VERSION ""

NS_ :

BS_:

BU_: SBZA_R_LS SBZA_L_LS VIS2_LS SDM_LS PEPS_LS UPA_LS PTM_LS MSM_LS HFP_LS EOCM_F_LS ECC_LS DCAC_LS CGM_LS BSM_LS BCM_LS AOS_LS

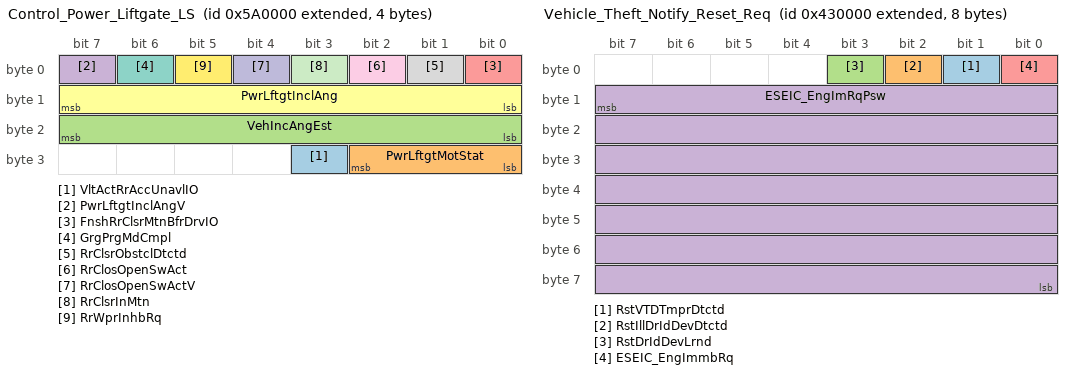
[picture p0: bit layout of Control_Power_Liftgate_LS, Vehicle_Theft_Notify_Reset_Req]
BO_ 2153381888 Control_Power_Liftgate_LS: 4 PTM_LS
 SG_ VltActRrAccUnavlIO : 27|1@0+ (1,0) [0|1] ""  CGM_LS
 SG_ PwrLftgtMotStat : 26|3@0+ (1,0) [0|7] ""  ECC_LS,CGM_LS
 SG_ VehIncAngEst : 23|8@0+ (1,0) [0|255] "deg"  CGM_LS
 SG_ PwrLftgtInclAngV : 7|1@0+ (1,0) [0|1] ""  CGM_LS
 SG_ FnshRrClsrMtnBfrDrvIO : 0|1@0+ (1,0) [0|1] ""  CGM_LS
 SG_ PwrLftgtInclAng : 15|8@0+ (1,0) [0|255] ""  CGM_LS
 SG_ GrgPrgMdCmpl : 6|1@0+ (1,0) [0|1] ""  CGM_LS,BCM_LS
 SG_ RrClsrObstclDtctd : 1|1@0+ (1,0) [0|1] ""  CGM_LS,BCM_LS
 SG_ RrClosOpenSwAct : 2|1@0+ (1,0) [0|1] ""  CGM_LS,BCM_LS
 SG_ RrClosOpenSwActV : 4|1@0+ (1,0) [0|1] ""  CGM_LS,BCM_LS
 SG_ RrClsrInMtn : 3|1@0+ (1,0) [0|1] ""  CGM_LS,BCM_LS
 SG_ RrWprInhbRq : 5|1@0+ (1,0) [0|1] ""  CGM_LS,BCM_LS

BO_ 2151514112 Reset_OilLife_Request_LS: 1 CGM_LS
 SG_ EngOilLfRstRq : 0|1@0+ (1,0) [0|1] ""  BCM_LS

BO_ 2151153664 Rear_Window_Defog_Status_LS: 1 ECC_LS
 SG_ RrWndDfgOn : 0|1@0+ (1,0) [0|1] ""  CGM_LS,BCM_LS

BO_ 2151874560 Vehicle_Theft_Notify_Reset_Req: 8 CGM_LS
 SG_ RstVTDTmprDtctd : 1|1@0+ (1,0) [0|1] ""  BCM_LS
 SG_ RstIllDrIdDevDtctd : 2|1@0+ (1,0) [0|1] ""  BCM_LS
 SG_ RstDrIdDevLrnd : 3|1@0+ (1,0) [0|1] ""  BCM_LS
 SG_ ESEIC_EngImRqPsw : 15|56@0+ (1,0) [0|1] ""  BCM_LS
 SG_ ESEIC_EngImmbRq : 0|1@0+ (1,0) [0|1] ""  BCM_LS

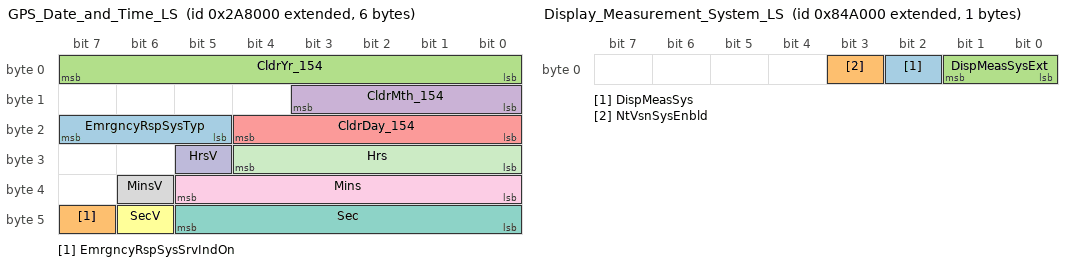
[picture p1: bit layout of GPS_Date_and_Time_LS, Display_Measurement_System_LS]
BO_ 2150268928 GPS_Date_and_Time_LS: 6 CGM_LS
 SG_ EmrgncyRspSysTyp : 23|3@0+ (1,0) [0|7] "" Vector__XXX
 SG_ EmrgncyRspSysSrvIndOn : 47|1@0+ (1,0) [0|1] "" Vector__XXX
 SG_ CldrYr_154 : 7|8@0+ (1,2000) [2000|2255] "year"  VIS2_LS,EOCM_F_LS,BCM_LS
 SG_ CldrMth_154 : 11|4@0+ (1,0) [0|15] ""  VIS2_LS,EOCM_F_LS,ECC_LS,BCM_LS
 SG_ CldrDay_154 : 20|5@0+ (1,0) [0|31] "days"  VIS2_LS,EOCM_F_LS,ECC_LS,BCM_LS
 SG_ SecV : 46|1@0+ (1,0) [0|1] ""  VIS2_LS,EOCM_F_LS,BCM_LS
 SG_ Sec : 45|6@0+ (1,0) [0|63] "s"  VIS2_LS,EOCM_F_LS,BCM_LS
 SG_ MinsV : 38|1@0+ (1,0) [0|1] ""  VIS2_LS,EOCM_F_LS,ECC_LS,BCM_LS
 SG_ Mins : 37|6@0+ (1,0) [0|63] "min"  VIS2_LS,EOCM_F_LS,ECC_LS,BCM_LS
 SG_ HrsV : 29|1@0+ (1,0) [0|1] ""  VIS2_LS,EOCM_F_LS,ECC_LS,BCM_LS
 SG_ Hrs : 28|5@0+ (1,0) [0|31] "h"  VIS2_LS,EOCM_F_LS,ECC_LS,BCM_LS

BO_ 2041 PCU_Resp_From_SDM_LS: 8 SDM_LS
 SG_ PCUInfo_7F9 : 7|64@0+ (1,0) [0|1.84467440737096E+019] ""  CGM_LS,BCM_LS

BO_ 577 USDT_Req_to_BCM_LS: 8 CGM_LS
 SG_ DgnInf : 7|64@0+ (1,0) [0|1.84467440737096E+019] ""  BCM_LS

BO_ 2156175360 Display_Measurement_System_LS: 1 CGM_LS
 SG_ DispMeasSys : 2|1@0+ (1,0) [0|1] ""  EOCM_F_LS,BCM_LS
 SG_ NtVsnSysEnbld : 3|1@0+ (1,0) [0|1] ""  EOCM_F_LS
 SG_ DispMeasSysExt : 1|2@0+ (1,0) [0|3] ""  ECC_LS,BSM_LS

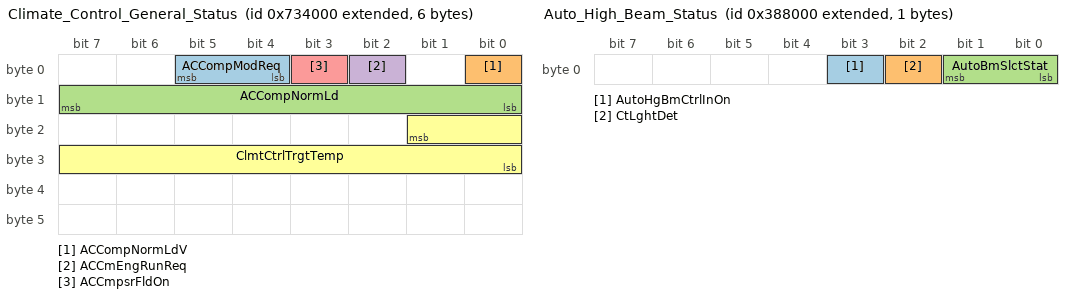
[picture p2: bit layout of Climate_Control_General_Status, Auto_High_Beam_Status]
BO_ 2155036672 Climate_Control_General_Status: 6 ECC_LS
 SG_ ACCompModReq : 5|2@0+ (1,0) [0|3] ""  CGM_LS,BSM_LS,BCM_LS
 SG_ ACCompNormLdV : 0|1@0+ (1,0) [0|1] ""  CGM_LS,BCM_LS
 SG_ ACCompNormLd : 15|8@0+ (0.1,0) [0|25.5] "l/min"  CGM_LS,BCM_LS
 SG_ ACCmEngRunReq : 2|1@0+ (1,0) [0|1] ""  CGM_LS,BCM_LS
 SG_ ACCmpsrFldOn : 3|1@0+ (1,0) [0|1] ""  CGM_LS,BCM_LS
 SG_ ClmtCtrlTrgtTemp : 17|10@0+ (0.1,-10) [-10|92.3] "deg C"  CGM_LS,BSM_LS

BO_ 2151186432 Auto_High_Beam_Status: 1 EOCM_F_LS
 SG_ AutoHgBmCtrlInOn : 3|1@0+ (1,0) [0|1] ""  CGM_LS
 SG_ CtLghtDet : 2|1@0+ (1,0) [0|1] ""  CGM_LS,BCM_LS
 SG_ AutoBmSlctStat : 1|2@0+ (1,0) [0|3] ""  CGM_LS,BCM_LS

BO_ 2152062976 Thrml_Ref_Comp_Spd_Feedbak_LS: 3 BCM_LS
 SG_ ThrmlRefCompStatFdbck : 3|4@0+ (1,0) [0|15] " "  ECC_LS,CGM_LS
 SG_ ThrmlRefCompSpdFdbck : 13|14@0+ (1,0) [0|16383] "rpm"  ECC_LS,CGM_LS

BO_ 2150711296 Tachometer_Engine_Speed_LS: 4 BCM_LS
 SG_ TachEngSpd : 4|13@0+ (1,0) [0|8191] "rpm"  CGM_LS

BO_ 2153406464 Power_Tailgate_Release_Info_LS: 1 BCM_LS
 SG_ RrClsrInrAjrSwAct : 6|1@0+ (1,0) [0|1] ""  CGM_LS
 SG_ TlgtUnavlbleIO : 7|1@0+ (1,0) [0|1] ""  CGM_LS

BO_ 2152177664 OTA_Electric_Pwr_Readiness_LS: 1 BCM_LS
 SG_ RmtRflshElecPwrRdness : 7|8@0+ (0.025,0) [0|6.375] "AmpHour"  CGM_LS

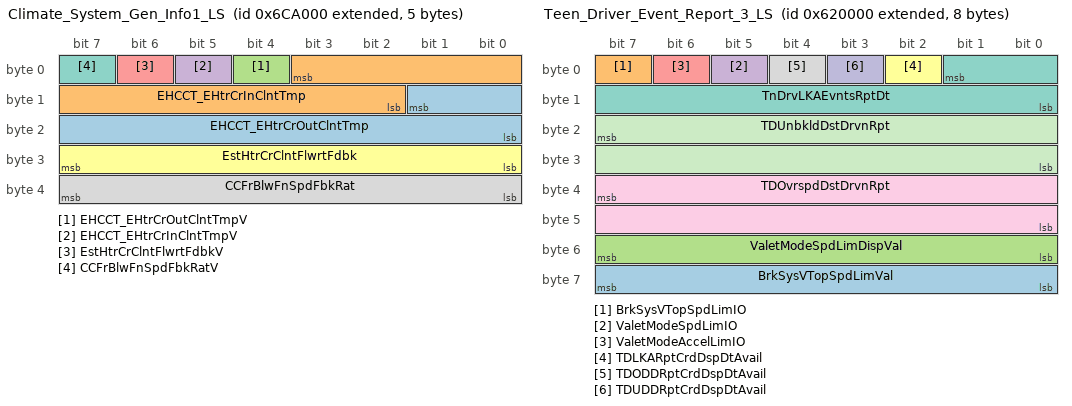
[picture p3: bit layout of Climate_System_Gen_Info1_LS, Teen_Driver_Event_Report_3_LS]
BO_ 2154602496 Climate_System_Gen_Info1_LS: 5 BCM_LS
 SG_ EHCCT_EHtrCrOutClntTmp : 9|10@0+ (0.1857,-40) [-40|149.9711] "DegC"  ECC_LS,CGM_LS
 SG_ EHCCT_EHtrCrInClntTmp : 3|10@0+ (0.1857,-40) [-40|149.9711] "DegC"  ECC_LS,CGM_LS
 SG_ EHCCT_EHtrCrOutClntTmpV : 4|1@0+ (1,0) [0|1] ""  ECC_LS,CGM_LS
 SG_ EHCCT_EHtrCrInClntTmpV : 5|1@0+ (1,0) [0|1] ""  ECC_LS,CGM_LS
 SG_ EstHtrCrClntFlwrtFdbkV : 6|1@0+ (1,0) [0|1] ""  ECC_LS,CGM_LS
 SG_ EstHtrCrClntFlwrtFdbk : 31|8@0+ (0.2509,0) [0|63.9795] "l/min"  ECC_LS,CGM_LS
 SG_ CCFrBlwFnSpdFbkRatV : 7|1@0+ (1,0) [0|1] ""  ECC_LS,CGM_LS
 SG_ CCFrBlwFnSpdFbkRat : 39|8@0+ (0.392157,0) [0|100.000035] "%"  ECC_LS,CGM_LS

BO_ 2153906176 Teen_Driver_Event_Report_3_LS: 8 BCM_LS
 SG_ BrkSysVTopSpdLimVal : 63|8@0+ (2,0) [0|510] "km / h"  CGM_LS
 SG_ BrkSysVTopSpdLimIO : 7|1@0+ (1,0) [0|1] ""  CGM_LS
 SG_ ValetModeSpdLimDispVal : 55|8@0+ (2,0) [0|510] "km/h"  CGM_LS
 SG_ ValetModeSpdLimIO : 5|1@0+ (1,0) [0|1] ""  CGM_LS
 SG_ ValetModeAccelLimIO : 6|1@0+ (1,0) [0|1] ""  CGM_LS
 SG_ TDLKARptCrdDspDtAvail : 2|1@0+ (1,0) [0|1] ""  CGM_LS
 SG_ TnDrvLKAEvntsRptDt : 1|10@0+ (1,0) [0|1023] ""  CGM_LS
 SG_ TDODDRptCrdDspDtAvail : 4|1@0+ (1,0) [0|1] ""  CGM_LS
 SG_ TDOvrspdDstDrvnRpt : 39|16@0+ (1,0) [0|65535] ""  CGM_LS
 SG_ TDUDDRptCrdDspDtAvail : 3|1@0+ (1,0) [0|1] ""  CGM_LS
 SG_ TDUnbkldDstDrvnRpt : 23|16@0+ (1,0) [0|65535] ""  CGM_LS

BO_ 2155978752 Brake_Pad_life_LS: 8 BCM_LS
 SG_ BrkPdLfRrCnfrmReplcmntIO : 63|1@0+ (1,0) [0|1] ""  CGM_LS
 SG_ BrkPdLfFrtCnfrmReplcmntIO : 48|1@0+ (1,0) [0|1] ""  CGM_LS
 SG_ ABSActIO : 39|1@0+ (1,0) [0|1] ""  CGM_LS
 SG_ CrwlModeDndRsnIndReq : 51|3@0+ (1,0) [0|7] ""  CGM_LS
 SG_ BrkPdLfRrDstRmng : 31|8@0+ (100,0) [0|25500] ""  CGM_LS
 SG_ BrkPdLfFrtDstRmng : 23|8@0+ (100,0) [0|25500] ""  CGM_LS
 SG_ BrkPdLfRrDstWrnIndRq : 53|2@0+ (1,0) [0|3] ""  CGM_LS
 SG_ BrkPdLfFrtDstWrnIndRq : 55|2@0+ (1,0) [0|3] ""  CGM_LS
 SG_ BrkPdLfRrRstAvail : 40|1@0+ (1,0) [0|1] ""  CGM_LS
 SG_ BrkPdLfFrtRstAvail : 41|1@0+ (1,0) [0|1] ""  CGM_LS
 SG_ BrkPdLfRrV : 15|1@0+ (1,0) [0|1] ""  CGM_LS
 SG_ BrkPdLfRr : 14|7@0+ (1,0) [0|127] "%"  CGM_LS
 SG_ BrkPdLfFrtV : 7|1@0+ (1,0) [0|1] ""  CGM_LS
 SG_ BrkPdLfFrt : 6|7@0+ (1,0) [0|127] "%"  CGM_LS
 SG_ BrkPdLfStatIndRq : 47|3@0+ (1,0) [0|7] ""  CGM_LS
 SG_ EngAirFltLfRmn : 38|7@0+ (1,0) [0|127] "%"  CGM_LS
 SG_ EngAirFltMonSt : 44|3@0+ (1,0) [0|7] ""  CGM_LS

BO_ 2159247360 ODI_BCM_2_CenterStack_LS: 8 BCM_LS
 SG_ ODI_BCM2CntrStck : 7|64@0+ (1,0) [0|1.84467440737096E+019] ""  CGM_LS

BO_ 2151833600 Heated_Wndshild_CstmrIhbt_Req_LS: 1 BCM_LS
 SG_ HtdFrntWSDispReq : 7|2@0+ (1,0) [0|3] ""  ECC_LS,CGM_LS
 SG_ HtdFrntWSCustRqIhbt : 5|1@0+ (1,0) [0|1] ""  ECC_LS,CGM_LS

BO_ 2150236160 Unlock_Key_Store_Crypt_2_LS: 8 BCM_LS
 SG_ UlckKyStrCrptoDt2M : 4|1@0+ (1,0) [0|1] ""  CGM_LS
 SG_ UlckKyStrCrptoDt2 : 3|60@0+ (1,0) [0|1.15292150460685E+018] ""  CGM_LS

BO_ 2150170624 Unlock_Key_Store_Crypt_1_LS: 8 BCM_LS
 SG_ UlckKyStrCrptoDt1M : 4|1@0+ (1,0) [0|1] ""  CGM_LS
 SG_ UlckKyStrCrptoDt1 : 3|60@0+ (1,0) [0|1.15292150460685E+018] ""  CGM_LS

BO_ 2154725376 Auxiliary_Heater_LS: 1 BCM_LS
 SG_ AuxHtrAtv378 : 6|1@0+ (1,0) [0|1] ""  ECC_LS,CGM_LS
 SG_ AuxHtrRq : 7|1@0+ (1,0) [0|1] ""  ECC_LS,CGM_LS

BO_ 2151931904 Custom_Launch_Ctrl_LS: 8 BCM_LS
 SG_ FourWhlDrvIdReqExtRng : 59|4@0+ (1,0) [0|15] ""  CGM_LS
 SG_ LnchCtrlTmrVal : 35|4@0+ (1,0) [0|15] ""  CGM_LS
 SG_ LnchCtrlBrkPresVal : 47|4@0+ (10,0) [0|150] "%"  CGM_LS
 SG_ FuelMdTrnstnIndReq : 63|4@0+ (1,0) [0|15] ""  CGM_LS
 SG_ BiFuelRflGaslinIndReq : 42|3@0+ (1,0) [0|7] ""  CGM_LS
 SG_ AutoShtdwnTmr : 55|8@0+ (1,0) [0|255] "min"  CGM_LS
 SG_ AutoShtdwnIO : 43|1@0+ (1,0) [0|1] ""  CGM_LS
 SG_ TCSTempDsblReqIO : 24|1@0+ (1,0) [0|1] ""  CGM_LS
 SG_ VehStbCmptvMdCstAvl : 25|1@0+ (1,0) [0|1] ""  CGM_LS
 SG_ VehStbEnmntCstAvl : 26|1@0+ (1,0) [0|1] ""  CGM_LS
 SG_ TCSysCstAvl : 27|1@0+ (1,0) [0|1] ""  CGM_LS
 SG_ VehStbCmptvMdCurSt : 28|1@0+ (1,0) [0|1] ""  CGM_LS
 SG_ VehStbEnhmntCurSt : 36|1@0+ (1,0) [0|1] ""  CGM_LS
 SG_ TCSysCurSt : 37|1@0+ (1,0) [0|1] ""  CGM_LS
 SG_ TracAndStbScrnCnfg : 39|2@0+ (1,0) [0|3] ""  CGM_LS
 SG_ ElctShfPriLtdPerfMdIO : 29|1@0+ (1,0) [0|1] ""  CGM_LS
 SG_ LnchCtrlWhlSlpStat : 7|5@0+ (1,0) [0|31] ""  CGM_LS
 SG_ LnchCtrlMdStat : 2|3@0+ (1,0) [0|7] ""  CGM_LS
 SG_ LnchCtrlEngRPMStat : 15|6@0+ (1,0) [0|63] ""  CGM_LS
 SG_ RegVltCtlEngyRcvryAct : 30|1@0+ (1,0) [0|1] ""  CGM_LS
 SG_ VehSpdCntlSystmType : 20|3@0+ (1,0) [0|7] ""  CGM_LS
 SG_ ACCSysSltdMdDispIO : 31|1@0+ (1,0) [0|1] ""  CGM_LS
 SG_ ACCSysSltdMd : 17|2@0+ (1,0) [0|3] ""  CGM_LS
 SG_ PTExPrtclFltWrng3IO : 8|1@0+ (1,0) [0|1] ""  CGM_LS
 SG_ PTExPartFltManRegStat : 23|3@0+ (1,0) [0|7] ""  CGM_LS
 SG_ AWDRecmndIO : 9|1@0+ (1,0) [0|1] ""  CGM_LS

BO_ 2151915520 HMI_Display_LS: 8 BCM_LS
 SG_ ESPTrnVehOffFrPrkIO : 44|1@0+ (1,0) [0|1] ""  CGM_LS
 SG_ ESPTrnsCtlrMalfIO : 45|1@0+ (1,0) [0|1] ""  CGM_LS
 SG_ ESPShfToDrvTryAgnIO : 43|1@0+ (1,0) [0|1] ""  CGM_LS
 SG_ ElcShfPriTwoGrsSlInRq : 47|2@0+ (1,0) [0|3] ""  CGM_LS
 SG_ DrvEffInd : 39|8@0- (0.78125,0) [-100|99.21875] "%"  CGM_LS
 SG_ EngIntkArBstPrExtRngV : 14|1@0+ (1,0) [0|1] ""  CGM_LS
 SG_ EngIntkArBstPrExtRng : 8|9@0+ (1,-110) [-110|401] "kPa"  CGM_LS
 SG_ ElecShfRngDispRCExtd : 27|4@0+ (1,0) [0|15] ""  CGM_LS
 SG_ ElecShfRngDisp : 31|4@0+ (1,0) [0|15] ""  CGM_LS
 SG_ ESPTransMalfIO : 9|1@0+ (1,0) [0|1] ""  CGM_LS
 SG_ ESPRngInvldReqIO : 10|1@0+ (1,0) [0|1] ""  CGM_LS
 SG_ ESPPrkInvldReqIO : 11|1@0+ (1,0) [0|1] ""  CGM_LS
 SG_ ESPHldShfLvrToEngRgIO : 12|1@0+ (1,0) [0|1] ""  CGM_LS
 SG_ ESPDrvrPrkIlkSftAtdIO : 13|1@0+ (1,0) [0|1] ""  CGM_LS
 SG_ ESPDrvrIlkShfAtdIO : 7|1@0+ (1,0) [0|1] ""  CGM_LS
 SG_ AHAct : 6|1@0+ (1,0) [0|1] ""  CGM_LS
 SG_ AHEnbld : 5|1@0+ (1,0) [0|1] ""  CGM_LS
 SG_ ShfToPrkBfExtngIO : 4|1@0+ (1,0) [0|1] ""  CGM_LS
 SG_ AHServcIO : 3|1@0+ (1,0) [0|1] ""  CGM_LS
 SG_ AHAppBrkPedlIO : 2|1@0+ (1,0) [0|1] ""  CGM_LS
 SG_ AHDisbldStbltIO : 1|1@0+ (1,0) [0|1] ""  CGM_LS
 SG_ AHDisbldDrOpnIO : 0|1@0+ (1,0) [0|1] ""  CGM_LS
 SG_ ElcTransRngSlctVDA : 15|1@0+ (1,0) [0|1] ""  CGM_LS

BO_ 2153947136 Remote_Reflash_Stat_LS: 1 BCM_LS
 SG_ RmtRflshMdAct : 7|1@0+ (1,0) [0|1] ""  CGM_LS

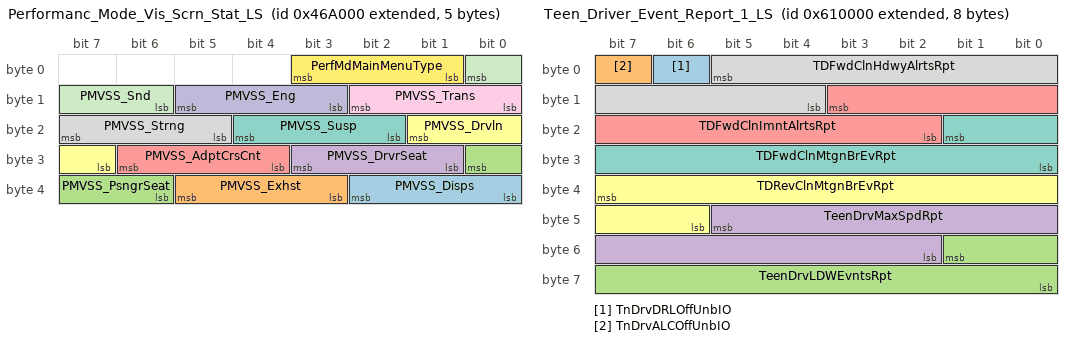
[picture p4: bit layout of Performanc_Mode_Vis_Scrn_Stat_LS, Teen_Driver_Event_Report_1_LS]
BO_ 2152112128 Performanc_Mode_Vis_Scrn_Stat_LS: 5 BCM_LS
 SG_ PMVSS_Disps : 34|3@0+ (1,0) [0|7] ""  CGM_LS
 SG_ PMVSS_Exhst : 37|3@0+ (1,0) [0|7] ""  CGM_LS
 SG_ PMVSS_PsngrSeat : 24|3@0+ (1,0) [0|7] ""  CGM_LS
 SG_ PMVSS_DrvrSeat : 27|3@0+ (1,0) [0|7] ""  CGM_LS
 SG_ PMVSS_AdptCrsCnt : 30|3@0+ (1,0) [0|7] ""  CGM_LS
 SG_ PMVSS_Drvln : 17|3@0+ (1,0) [0|7] ""  CGM_LS
 SG_ PMVSS_Susp : 20|3@0+ (1,0) [0|7] ""  CGM_LS
 SG_ PMVSS_Strng : 23|3@0+ (1,0) [0|7] ""  CGM_LS
 SG_ PMVSS_Trans : 10|3@0+ (1,0) [0|7] ""  CGM_LS
 SG_ PMVSS_Eng : 13|3@0+ (1,0) [0|7] ""  CGM_LS
 SG_ PMVSS_Snd : 0|3@0+ (1,0) [0|7] ""  CGM_LS
 SG_ PerfMdMainMenuType : 3|3@0+ (1,0) [0|7] ""  CGM_LS

BO_ 2153857024 Teen_Driver_Event_Report_2_LS: 8 BCM_LS
 SG_ TnDrvTrCtrlEvntsRpt : 49|10@0+ (1,0) [0|1023] "counts"  CGM_LS
 SG_ TnDrvDrowDrvAlrtsRpt : 43|10@0+ (1,0) [0|1023] "counts"  CGM_LS
 SG_ TDRCADD_WOTEvnts : 11|1@0+ (1,0) [0|1] ""  CGM_LS
 SG_ TDRCADD_LDWEvnts : 10|1@0+ (1,0) [0|1] ""  CGM_LS
 SG_ TDRCADD_FCMBrEvts : 13|1@0+ (1,0) [0|1] ""  CGM_LS
 SG_ TDRCADD_DrwDrvAlrt : 12|1@0+ (1,0) [0|1] ""  CGM_LS
 SG_ TDRCADD_RCMBrEvts : 14|1@0+ (1,0) [0|1] ""  CGM_LS
 SG_ TDRCADD_FCImntAlrts : 15|1@0+ (1,0) [0|1] ""  CGM_LS
 SG_ TDRCADD_FCHdwyAlrt : 0|1@0+ (1,0) [0|1] ""  CGM_LS
 SG_ TDRCADD_StCtrlEvnts : 2|1@0+ (1,0) [0|1] ""  CGM_LS
 SG_ TDRCADD_ABSAtvEvt : 1|1@0+ (1,0) [0|1] ""  CGM_LS
 SG_ TDRCADD_TrCtrlEvnts : 3|1@0+ (1,0) [0|1] ""  CGM_LS
 SG_ TDRCADD_OvSpdEvnt : 4|1@0+ (1,0) [0|1] ""  CGM_LS
 SG_ TDRCADD_DistDrvn : 5|1@0+ (1,0) [0|1] ""  CGM_LS
 SG_ TDRCADD_MaxSpd : 6|1@0+ (1,0) [0|1] ""  CGM_LS
 SG_ TnDrvStblCtrlEvntsRpt : 37|10@0+ (1,0) [0|1023] "counts"  CGM_LS
 SG_ TnDrvABSAtvEvntsRpt : 31|10@0+ (1,0) [0|1023] "counts"  CGM_LS
 SG_ TeenDrvWOTEvntsRpt : 9|10@0+ (1,0) [0|1023] "counts"  CGM_LS

BO_ 2153840640 Teen_Driver_Event_Report_1_LS: 8 BCM_LS
 SG_ TnDrvDRLOffUnbIO : 6|1@0+ (1,0) [0|1] ""  CGM_LS
 SG_ TnDrvALCOffUnbIO : 7|1@0+ (1,0) [0|1] ""  CGM_LS
 SG_ TeenDrvLDWEvntsRpt : 49|10@0+ (1,0) [0|1023] "counts"  CGM_LS
 SG_ TeenDrvMaxSpdRpt : 45|12@0+ (0.0625,0) [0|255.9375] "km/h"  CGM_LS
 SG_ TDFwdClnImntAlrtsRpt : 11|10@0+ (1,0) [0|1023] "counts"  CGM_LS
 SG_ TDRevClnMtgnBrEvRpt : 39|10@0+ (1,0) [0|1023] "counts"  CGM_LS
 SG_ TDFwdClnMtgnBrEvRpt : 17|10@0+ (1,0) [0|1023] "counts"  CGM_LS
 SG_ TDFwdClnHdwyAlrtsRpt : 5|10@0+ (1,0) [0|1023] "counts"  CGM_LS

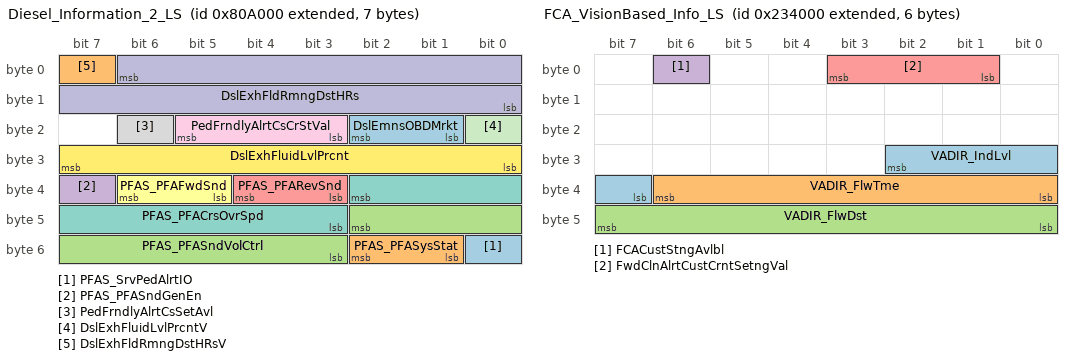
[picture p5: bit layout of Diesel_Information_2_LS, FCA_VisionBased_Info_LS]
BO_ 2155913216 Diesel_Information_2_LS: 7 BCM_LS
 SG_ PFAS_SrvPedAlrtIO : 48|1@0+ (1,0) [0|1] ""  CGM_LS
 SG_ PFAS_PFASysStat : 50|2@0+ (1,0) [0|3] ""  CGM_LS
 SG_ PFAS_PFASndVolCtrl : 42|8@0+ (0.392157,0) [0|100.000035] "%"  CGM_LS
 SG_ PFAS_PFASndGenEn : 39|1@0+ (1,0) [0|1] ""  CGM_LS
 SG_ PFAS_PFARevSnd : 36|2@0+ (1,0) [0|3] ""  CGM_LS
 SG_ PFAS_PFAFwdSnd : 38|2@0+ (1,0) [0|3] ""  CGM_LS
 SG_ PFAS_PFACrsOvrSpd : 34|8@0+ (1,0) [0|255] "km/h"  CGM_LS
 SG_ PedFrndlyAlrtCsSetAvl : 22|1@0+ (1,0) [0|1] ""  CGM_LS
 SG_ PedFrndlyAlrtCsCrStVal : 21|3@0+ (1,0) [0|7] ""  CGM_LS
 SG_ DslExhFldRmngDstHRs : 6|15@0+ (2,0) [0|65534] "km"  CGM_LS
 SG_ DslExhFluidLvlPrcntV : 16|1@0+ (1,0) [0|1] ""  CGM_LS
 SG_ DslExhFluidLvlPrcnt : 31|8@0+ (0.392157,0) [0|100.000035] "%"  CGM_LS
 SG_ DslEmnsOBDMrkt : 18|2@0+ (1,0) [0|3] ""  CGM_LS
 SG_ DslExhFldRmngDstHRsV : 7|1@0+ (1,0) [0|1] ""  CGM_LS

BO_ 2152095744 HSGMLAN_Customization_Setings_LS: 5 BCM_LS
 SG_ SPMCA_SusPrfMd6Avl : 32|1@0+ (1,0) [0|1] ""  CGM_LS
 SG_ SPMCA_SusPrfMd5Avl : 33|1@0+ (1,0) [0|1] ""  CGM_LS
 SG_ SPMCA_SusPrfMd4Avl : 34|1@0+ (1,0) [0|1] ""  CGM_LS
 SG_ SPMCA_SusPrfMd3Avl : 35|1@0+ (1,0) [0|1] ""  CGM_LS
 SG_ SPMCA_SusPrfMd2Avl : 36|1@0+ (1,0) [0|1] ""  CGM_LS
 SG_ SPMCA_SusPrfMd1Avl : 37|1@0+ (1,0) [0|1] ""  CGM_LS
 SG_ SPMCA_StrPrfMd6Avl : 24|1@0+ (1,0) [0|1] ""  CGM_LS
 SG_ SPMCA_StrPrfMd5Avl : 25|1@0+ (1,0) [0|1] ""  CGM_LS
 SG_ SPMCA_StrPrfMd4Avl : 26|1@0+ (1,0) [0|1] ""  CGM_LS
 SG_ SPMCA_StrPrfMd3Avl : 27|1@0+ (1,0) [0|1] ""  CGM_LS
 SG_ SPMCA_StrPrfMd2Avl : 28|1@0+ (1,0) [0|1] ""  CGM_LS
 SG_ SPMCA_StrPrfMd1Avl : 29|1@0+ (1,0) [0|1] ""  CGM_LS
 SG_ SPMCA_SndPrfMd6Avl : 16|1@0+ (1,0) [0|1] ""  CGM_LS
 SG_ SPMCA_SndPrfMd5Avl : 17|1@0+ (1,0) [0|1] ""  CGM_LS
 SG_ SPMCA_SndPrfMd4Avl : 18|1@0+ (1,0) [0|1] ""  CGM_LS
 SG_ SPMCA_SndPrfMd3Avl : 19|1@0+ (1,0) [0|1] ""  CGM_LS
 SG_ SPMCA_SndPrfMd2Avl : 20|1@0+ (1,0) [0|1] ""  CGM_LS
 SG_ SPMCA_SndPrfMd1Avl : 21|1@0+ (1,0) [0|1] ""  CGM_LS
 SG_ DPMCA_DispPrfMd6Avl : 8|1@0+ (1,0) [0|1] ""  CGM_LS
 SG_ DPMCA_DispPrfMd5Avl : 9|1@0+ (1,0) [0|1] ""  CGM_LS
 SG_ DPMCA_DispPrfMd4Avl : 10|1@0+ (1,0) [0|1] ""  CGM_LS
 SG_ DPMCA_DispPrfMd3Avl : 11|1@0+ (1,0) [0|1] ""  CGM_LS
 SG_ DPMCA_DispPrfMd2Avl : 12|1@0+ (1,0) [0|1] ""  CGM_LS
 SG_ DPMCA_DispPrfMd1Avl : 13|1@0+ (1,0) [0|1] ""  CGM_LS
 SG_ DPMCA_DrvlPrfMd6Avl : 0|1@0+ (1,0) [0|1] ""  CGM_LS
 SG_ DPMCA_DrvlPrfMd5Avl : 1|1@0+ (1,0) [0|1] ""  CGM_LS
 SG_ DPMCA_DrvlPrfMd4Avl : 2|1@0+ (1,0) [0|1] ""  CGM_LS
 SG_ DPMCA_DrvlPrfMd3Avl : 3|1@0+ (1,0) [0|1] ""  CGM_LS
 SG_ DPMCA_DrvlPrfMd2Avl : 4|1@0+ (1,0) [0|1] ""  CGM_LS
 SG_ DPMCA_DrvlPrfMd1Avl : 5|1@0+ (1,0) [0|1] ""  CGM_LS

BO_ 2151899136 PTO_Status_LS: 5 BCM_LS
 SG_ PTOAccelUpnBrkRelIO : 22|1@0+ (1,0) [0|1] ""  CGM_LS
 SG_ PTOEngUpnBrkRelIO : 23|1@0+ (1,0) [0|1] ""  CGM_LS
 SG_ PTOManTransInGrIO : 21|1@0+ (1,0) [0|1] ""  CGM_LS
 SG_ PTOServIndOn : 31|1@0+ (1,0) [0|1] ""  CGM_LS
 SG_ PTOVDM : 20|1@0+ (1,0) [0|1] ""  CGM_LS
 SG_ PTOVDA : 19|1@0+ (1,0) [0|1] ""  CGM_LS
 SG_ PTOTransInGearIO : 13|1@0+ (1,0) [0|1] ""  CGM_LS
 SG_ PTOTpStpSpdCsStAvl : 10|1@0+ (1,0) [0|1] ""  CGM_LS
 SG_ PTOTpStSpdCsCrStVal : 26|3@0+ (1,0) [0|7] ""  CGM_LS
 SG_ PTOStdbySpdCsStAvl : 12|1@0+ (1,0) [0|1] ""  CGM_LS
 SG_ PTOStdbSpdCsCrStVal : 18|3@0+ (1,0) [0|7] ""  CGM_LS
 SG_ PTOSetPrkBrkIO : 14|1@0+ (1,0) [0|1] ""  CGM_LS
 SG_ PTOSet2SpdCsStAvl : 9|1@0+ (1,0) [0|1] ""  CGM_LS
 SG_ PTOSet2SpdCsCrStVal : 39|4@0+ (1,0) [0|15] ""  CGM_LS
 SG_ PTOSet1SpdCsStAvl : 8|1@0+ (1,0) [0|1] ""  CGM_LS
 SG_ PTOSet1SpdCsCrStVal : 35|4@0+ (1,0) [0|15] ""  CGM_LS
 SG_ PTORelCltPedIO : 15|1@0+ (1,0) [0|1] ""  CGM_LS
 SG_ PTORelBrkPedIO : 0|1@0+ (1,0) [0|1] ""  CGM_LS
 SG_ PTORelAccPedIO : 1|1@0+ (1,0) [0|1] ""  CGM_LS
 SG_ PTORedEngSpdIO : 2|1@0+ (1,0) [0|1] ""  CGM_LS
 SG_ PTOPrsRelCltPedIO : 3|1@0+ (1,0) [0|1] ""  CGM_LS
 SG_ PTOPrsRelBrkPedIO : 4|1@0+ (1,0) [0|1] ""  CGM_LS
 SG_ PTOEngRnTmrCsStAvl : 11|1@0+ (1,0) [0|1] ""  CGM_LS
 SG_ PTOEnRnTmCsCrStVal : 30|4@0+ (1,0) [0|15] ""  CGM_LS
 SG_ PTOEngmntStatInd : 6|2@0+ (1,0) [0|3] ""  CGM_LS
 SG_ PTODisengCrsCntlIO : 7|1@0+ (1,0) [0|1] ""  CGM_LS

BO_ 2150449152 Engine_Information_5_LS: 4 BCM_LS
 SG_ ESPDrvrExtIO : 29|1@0+ (1,0) [0|1] ""  CGM_LS
 SG_ ESPDrvrDrStIndtrmntIO : 30|1@0+ (1,0) [0|1] ""  CGM_LS
 SG_ ESPAutoPrkIO : 31|1@0+ (1,0) [0|1] ""  CGM_LS
 SG_ ManTransIndReq : 28|3@0+ (1,0) [0|7] ""  CGM_LS
 SG_ SrvcFlSysPrkInOpnArIO : 0|1@0+ (1,0) [0|1] ""  CGM_LS
 SG_ TnDrvStblCtrlOffUnbIO : 2|1@0+ (1,0) [0|1] ""  CGM_LS
 SG_ TnDrvTrCtrlOffUnbIO : 1|1@0+ (1,0) [0|1] ""  CGM_LS
 SG_ ASIRI_Indication08 : 16|1@0+ (1,0) [0|1] ""  CGM_LS
 SG_ ASIRI_Indication07 : 17|1@0+ (1,0) [0|1] ""  CGM_LS
 SG_ ASIRI_Indication06 : 18|1@0+ (1,0) [0|1] ""  CGM_LS
 SG_ ASIRI_Indication05 : 19|1@0+ (1,0) [0|1] ""  CGM_LS
 SG_ ASIRI_Indication04 : 20|1@0+ (1,0) [0|1] ""  CGM_LS
 SG_ ASIRI_Indication03 : 21|1@0+ (1,0) [0|1] ""  CGM_LS
 SG_ ASIRI_Indication02 : 22|1@0+ (1,0) [0|1] ""  CGM_LS
 SG_ ASIRI_Indication01 : 23|1@0+ (1,0) [0|1] ""  CGM_LS
 SG_ SpdLmtrSttngTypAct : 25|2@0+ (1,0) [0|3] ""  VIS2_LS,CGM_LS
 SG_ FuelSysNEmsRltMalfAct : 4|1@0+ (1,0) [0|1] ""  CGM_LS
 SG_ InActFuelMdFuelLvlIO : 3|1@0+ (1,0) [0|1] ""  CGM_LS
 SG_ EngInltSpcfcHmdtyV : 7|1@0+ (1,0) [0|1] ""  ECC_LS,CGM_LS
 SG_ EngInltSpcfcHmdtyM : 6|1@0+ (1,0) [0|1] ""  ECC_LS,CGM_LS
 SG_ EngInltSpcfcHmdty : 15|8@0+ (0.0196078,0) [0|4.999989] "% water"  ECC_LS,CGM_LS

BO_ 2149810176 FCA_VisionBased_Info_1_LS: 1 BCM_LS
 SG_ FCAHptcStVbnRqSeqN : 1|2@0+ (1,0) [0|3] ""  MSM_LS,CGM_LS
 SG_ FCAHptcStVbnReq : 7|6@0+ (1,0) [0|63] ""  MSM_LS,CGM_LS

BO_ 2149793792 FCA_VisionBased_Info_LS: 6 BCM_LS
 SG_ VADIR_IndLvl : 26|4@0+ (1,0) [0|15] ""  CGM_LS
 SG_ VADIR_FlwTme : 38|7@0+ (0.1,0) [0|12.7] "s"  CGM_LS
 SG_ VADIR_FlwDst : 47|8@0+ (1,0) [0|255] "m"  CGM_LS
 SG_ FCACustStngAvlbl : 6|1@0+ (1,0) [0|1] ""  CGM_LS
 SG_ FwdClnAlrtCustCrntSetngVal : 3|3@0+ (1,0) [0|7] ""  CGM_LS

BO_ 2152128512 Performance_Mode_Cust_Setings_LS: 4 BCM_LS
 SG_ PSPMCA_PsngStPrfMd6Avl : 16|1@0+ (1,0) [0|1] ""  CGM_LS
 SG_ PSPMCA_PsngStPrfMd5Avl : 17|1@0+ (1,0) [0|1] ""  CGM_LS
 SG_ PSPMCA_PsngStPrfMd4Avl : 18|1@0+ (1,0) [0|1] ""  CGM_LS
 SG_ PSPMCA_PsngStPrfMd3Avl : 19|1@0+ (1,0) [0|1] ""  CGM_LS
 SG_ PSPMCA_PsngStPrfMd2Avl : 20|1@0+ (1,0) [0|1] ""  CGM_LS
 SG_ PSPMCA_PsngStPrfMd1Avl : 21|1@0+ (1,0) [0|1] ""  CGM_LS
 SG_ DSPMCA_DrvrStPrfMd6Avl : 8|1@0+ (1,0) [0|1] ""  CGM_LS
 SG_ DSPMCA_DrvrStPrfMd5Avl : 9|1@0+ (1,0) [0|1] ""  CGM_LS
 SG_ DSPMCA_DrvrStPrfMd4Avl : 10|1@0+ (1,0) [0|1] ""  CGM_LS
 SG_ DSPMCA_DrvrStPrfMd3Avl : 11|1@0+ (1,0) [0|1] ""  CGM_LS
 SG_ DSPMCA_DrvrStPrfMd2Avl : 12|1@0+ (1,0) [0|1] ""  CGM_LS
 SG_ DSPMCA_DrvrStPrfMd1Avl : 13|1@0+ (1,0) [0|1] ""  CGM_LS
 SG_ DSPMCA_DrvStyPrfMd7Avl : 24|1@0+ (1,0) [0|1] ""  CGM_LS
 SG_ DSPMCA_DrvStyPrfMd6Avl : 25|1@0+ (1,0) [0|1] ""  CGM_LS
 SG_ DSPMCA_DrvStyPrfMd5Avl : 26|1@0+ (1,0) [0|1] ""  CGM_LS
 SG_ DSPMCA_DrvStyPrfMd4Avl : 27|1@0+ (1,0) [0|1] ""  CGM_LS
 SG_ DSPMCA_DrvStyPrfMd3Avl : 28|1@0+ (1,0) [0|1] ""  CGM_LS
 SG_ DSPMCA_DrvStyPrfMd2Avl : 29|1@0+ (1,0) [0|1] ""  CGM_LS
 SG_ DSPMCA_DrvStyPrfMd1Avl : 30|1@0+ (1,0) [0|1] ""  CGM_LS
 SG_ ACCPMCA_ACCPrfMd6Avl : 0|1@0+ (1,0) [0|1] ""  CGM_LS
 SG_ ACCPMCA_ACCPrfMd5Avl : 1|1@0+ (1,0) [0|1] ""  CGM_LS
 SG_ ACCPMCA_ACCPrfMd4Avl : 2|1@0+ (1,0) [0|1] ""  CGM_LS
 SG_ ACCPMCA_ACCPrfMd3Avl : 3|1@0+ (1,0) [0|1] ""  CGM_LS
 SG_ ACCPMCA_ACCPrfMd2Avl : 4|1@0+ (1,0) [0|1] ""  CGM_LS
 SG_ ACCPMCA_ACCPrfMd1Avl : 5|1@0+ (1,0) [0|1] ""  CGM_LS

BO_ 2149924864 Drv_Pref_Mode_Switch_Status_LS: 8 BCM_LS
 SG_ PTOMobModTrnsInGrIO : 15|1@0+ (1,0) [0|1] ""  CGM_LS
 SG_ FwdClnMtgnBrkReqAct : 7|1@0+ (1,0) [0|1] ""  CGM_LS
 SG_ TireRRLowTracIO : 54|1@0+ (1,0) [0|1] ""  CGM_LS
 SG_ TireRFLowTracIO : 53|1@0+ (1,0) [0|1] ""  CGM_LS
 SG_ TireLRLowTracIO : 52|1@0+ (1,0) [0|1] ""  CGM_LS
 SG_ TireLFLowTracIO : 51|1@0+ (1,0) [0|1] ""  CGM_LS
 SG_ HilRlbkCtrlActIO : 6|1@0+ (1,0) [0|1] ""  CGM_LS
 SG_ FstIdlMdAct : 39|1@0+ (1,0) [0|1] ""  CGM_LS
 SG_ DsplyPerfMdRq : 50|3@0+ (1,0) [0|7] ""  CGM_LS
 SG_ DrvSelMd8Stat : 37|1@0+ (1,0) [0|1] ""  ECC_LS,CGM_LS
 SG_ DrvSelMd8ReqDnd : 38|1@0+ (1,0) [0|1] ""  CGM_LS
 SG_ DrvSelMd7Stat : 35|1@0+ (1,0) [0|1] ""  ECC_LS,CGM_LS
 SG_ DrvSelMd7ReqDnd : 36|1@0+ (1,0) [0|1] ""  CGM_LS
 SG_ DrvSelMd6Stat : 13|1@0+ (1,0) [0|1] ""  ECC_LS,CGM_LS
 SG_ DrvSelMd6ReqDnd : 14|1@0+ (1,0) [0|1] ""  CGM_LS
 SG_ DrvSelMd5Stat : 11|1@0+ (1,0) [0|1] ""  ECC_LS,CGM_LS
 SG_ DrvSelMd5ReqDnd : 12|1@0+ (1,0) [0|1] ""  CGM_LS
 SG_ DrvSelMd4Stat : 9|1@0+ (1,0) [0|1] ""  ECC_LS,CGM_LS
 SG_ DrvSelMd4ReqDnd : 10|1@0+ (1,0) [0|1] ""  CGM_LS
 SG_ EDADS_RcmndtFwdGr : 43|4@0+ (1,0) [0|15] ""  CGM_LS
 SG_ EDADS_CrntFwdMsdG : 47|4@0+ (1,0) [0|15] ""  CGM_LS
 SG_ EDADS_ShftIndStat : 33|2@0+ (1,0) [0|3] ""  CGM_LS
 SG_ EDADS_EcoDrvShftIO : 34|1@0+ (1,0) [0|1] ""  CGM_LS
 SG_ DSMSS_DrvSelMd0Pn : 24|1@0+ (1,0) [0|1] ""  CGM_LS
 SG_ DSMSS_DrvSelMd8Pn : 25|1@0+ (1,0) [0|1] ""  CGM_LS
 SG_ DSMSS_DrvSelMd7Pn : 26|1@0+ (1,0) [0|1] ""  CGM_LS
 SG_ DSMSS_DrvSelMd6Pn : 27|1@0+ (1,0) [0|1] ""  CGM_LS
 SG_ DSMSS_DrvSelMd5Pn : 28|1@0+ (1,0) [0|1] ""  CGM_LS
 SG_ DSMSS_DrvSelMd4Pn : 29|1@0+ (1,0) [0|1] ""  CGM_LS
 SG_ DSMSS_DrvSelMd3Pn : 30|1@0+ (1,0) [0|1] ""  CGM_LS
 SG_ DSMSS_DrvSelMd2Pn : 31|1@0+ (1,0) [0|1] ""  CGM_LS
 SG_ DSMSS_DrvSelMd1Pn : 16|1@0+ (1,0) [0|1] ""  CGM_LS
 SG_ DSMSS_DrvSelMd8Un : 17|1@0+ (1,0) [0|1] ""  CGM_LS
 SG_ DSMSS_DrvSelMd7Un : 18|1@0+ (1,0) [0|1] ""  CGM_LS
 SG_ DSMSS_DrvSelMd6Un : 19|1@0+ (1,0) [0|1] ""  CGM_LS
 SG_ DSMSS_DrvSelMd5Un : 20|1@0+ (1,0) [0|1] ""  CGM_LS
 SG_ DSMSS_DrvSelMd4Un : 21|1@0+ (1,0) [0|1] ""  CGM_LS
 SG_ DSMSS_DrvSelMd3Un : 22|1@0+ (1,0) [0|1] ""  CGM_LS
 SG_ DSMSS_DrvSelMd2Un : 23|1@0+ (1,0) [0|1] ""  CGM_LS
 SG_ DSMSS_DrvSelMd1Un : 8|1@0+ (1,0) [0|1] ""  CGM_LS
 SG_ DrvSelMd3Stat : 4|1@0+ (1,0) [0|1] ""  ECC_LS,CGM_LS,BSM_LS
 SG_ DrvSelMd3ReqDnd : 5|1@0+ (1,0) [0|1] ""  CGM_LS
 SG_ DrvSelMd2Stat : 2|1@0+ (1,0) [0|1] ""  ECC_LS,CGM_LS,BSM_LS
 SG_ DrvSelMd2ReqDnd : 3|1@0+ (1,0) [0|1] ""  CGM_LS
 SG_ DrvSelMd1Stat : 0|1@0+ (1,0) [0|1] ""  ECC_LS,CGM_LS,BSM_LS
 SG_ DrvSelMd1ReqDnd : 1|1@0+ (1,0) [0|1] ""  CGM_LS
 SG_ CPSCA_Resrv3Avail : 56|1@0+ (1,0) [0|1] ""  CGM_LS
 SG_ CPSCA_Resrv2Avail : 57|1@0+ (1,0) [0|1] ""  CGM_LS
 SG_ CPSCA_Resrv1Avail : 58|1@0+ (1,0) [0|1] ""  CGM_LS
 SG_ CPSCA_AlrtBrkStrAvail : 59|1@0+ (1,0) [0|1] ""  CGM_LS
 SG_ CPSCA_AlrtBrkAvail : 60|1@0+ (1,0) [0|1] ""  CGM_LS
 SG_ CPSCA_AlrtAvail : 61|1@0+ (1,0) [0|1] ""  CGM_LS
 SG_ CPSCA_OffAvail : 62|1@0+ (1,0) [0|1] ""  CGM_LS
 SG_ a_12VBatSysUnstab : 55|1@0+ (1,0) [0|1] ""  CGM_LS

BO_ 2150301696 HMI_Animation_Initiator_LS: 1 BCM_LS
 SG_ WlcAnmReq : 0|1@0+ (1,0) [0|1] ""  CGM_LS

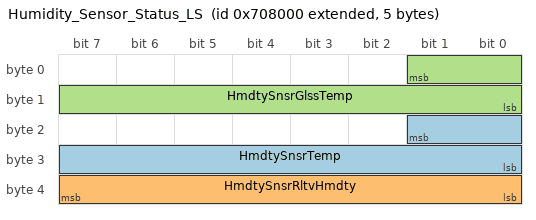
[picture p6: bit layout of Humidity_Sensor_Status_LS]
BO_ 2154856448 Humidity_Sensor_Status_LS: 5 BCM_LS
 SG_ HmdtySnsrTemp : 17|10@0+ (0.146628,-50) [-50|100.000444] "deg C"  ECC_LS,BSM_LS,CGM_LS
 SG_ HmdtySnsrRltvHmdty : 39|8@0+ (0.392157,0) [0|100.000035] "%"  ECC_LS,BSM_LS,CGM_LS
 SG_ HmdtySnsrGlssTemp : 1|10@0+ (0.146628,-50) [-50|100.000444] "deg C"  ECC_LS,CGM_LS

BO_TX_BU_ 2151186432 : VIS2_LS,EOCM_F_LS;
BO_TX_BU_ 2153406464 : PTM_LS,BCM_LS;
BO_TX_BU_ 2154725376 : ECC_LS,BCM_LS;
BO_TX_BU_ 2149793792 : EOCM_F_LS,BCM_LS;
CM_ SG_ 2151874560 ESEIC_EngImRqPsw "Desc: 7 ASCII characters";
CM_ SG_ 2154725376 AuxHtrAtv378 "Auxiliary Heater shall be used to denote a heater function that uses some kind of power, electrical or mechanical,  that was generated by the engine.";
CM_ SG_ 2154725376 AuxHtrRq "Auxiliary Heater shall be used to denote a heater function that uses some kind of power, electrical or mechanical,  that was generated by the engine.";
CM_ SG_ 2151899136 PTORelBrkPedIO "Power Take Off Release Brake Pedal To Engage Indication On";
BA_DEF_ SG_  "VNSigDiagnostic" ENUM  "No","Yes","DLCLS","DLCHS","DLCCE","DLCFO";
BA_DEF_ SG_  "VNSigUnused_4" ENUM  "No","Yes","DLCLS","DLCHS","DLCCE","DLCFO";
BA_DEF_ SG_  "VNSigIntermediate" ENUM  "No","Yes","DLCLS","DLCHS","DLCCE","DLCFO";
BA_DEF_ SG_  "VNSigParkedVehicle" ENUM  "No","Yes","DLCLS","DLCHS","DLCCE","DLCFO";
BA_DEF_ SG_  "VNSigRemoteDiagnostics" ENUM  "No","Yes","DLCLS","DLCHS","DLCCE","DLCFO";
BA_DEF_ SG_  "GenSigSendOnInit" ENUM  "Not Initialized","Application","Handler","DLCLS","DLCHS","DLCCE","DLCFO";
BA_DEF_ SG_  "GenSigSendType" ENUM  "not used","not used","not used","not used","not used","not used","not used","NoSigSendType","not used","not used","OnAnyChange","OnChangeIfActive","OnDelta","DLCLS","DLCHS","DLCCE","DLCFO";
BA_DEF_ SG_  "GenSigInactiveValue" INT 0 0;
BA_DEF_ SG_  "GenSigDeltaValue" INT 0 0;
BA_DEF_ SG_  "VNSigAllNodes" ENUM  "No","Yes","DLCLS","DLCHS","DLCCE","DLCFO";
BA_DEF_ SG_  "SignalType" STRING ;
BA_DEF_ SG_  "PacketOrder" INT 0 65535;
BA_DEF_ SG_  "SignalLongName" STRING ;
BA_DEF_ SG_  "GenSigStartValue" INT 0 65535;
BA_DEF_ SG_  "TxSignalSendOnInit" ENUM  "Not Initialized","Application","Handler";
BA_DEF_ BO_  "GenMsgILSupport" ENUM  "No","Yes","DLCLS","DLCHS","DLCCE","DLCFO";
BA_DEF_ BO_  "TpApplType" STRING ;
BA_DEF_ BO_  "Prio" INT 0 7;
BA_DEF_ BO_  "MessageSubnet" ENUM  "LS","MS","HS","CE","PE","HV","FO","S1","HE","LE","HE2","DLCLS","DLCHS","DLCCE","DLCFO","vector_leerstring";
BA_DEF_ BO_  "DiagState" ENUM  "No","Yes";
BA_DEF_ BO_  "GenMsgIlSupport" ENUM  "No","Yes";
BA_DEF_ BO_  "GenMsgStartDelayTime" INT 0 100000;
BA_DEF_ BO_  "GenMsgDelayTime" INT 0 100000;
BA_DEF_ BO_  "GenMsgCycleTime" INT 0 100000;
BA_DEF_ BO_  "GenMsgSendType" ENUM  "cyclicX","spontanX","cyclicIfActiveX","spontanWithDelay","cyclicAndSpontanX","cyclicAndSpontanWithDelay","spontanWithRepitition","cyclicIfActiveAndSpontanWD";
BA_DEF_ BO_  "DiagResponse" ENUM  "No","Yes";
BA_DEF_ BO_  "DiagRequest" ENUM  "No","Yes";
BA_DEF_ BO_  "NmMessage" ENUM  "No","Yes";
BA_DEF_REL_ BU_SG_REL_  "GenSigSuprvResp" ENUM  "None","Notify App","Substitute Default","DLCLS","DLCHS","DLCCE","DLCFO";
BA_DEF_REL_ BU_SG_REL_  "GenSigSuprvRespSubValue" INT 0 65535;
BA_DEF_REL_ BU_SG_REL_  "GenSigRxStartValue" STRING ;
BA_DEF_REL_ BU_SG_REL_  "GenSigVDAFailResp" ENUM  "No","Yes","DLCLS","DLCHS","DLCCE","DLCFO";
BA_DEF_REL_ BU_SG_REL_  "GenSigVDAFailComment" STRING ;
BA_DEF_REL_ BU_SG_REL_  "GenSigVBitRespComment" STRING ;
BA_DEF_REL_ BU_SG_REL_  "GenSigVBitResp" ENUM  "No","Yes","DLCLS","DLCHS","DLCCE","DLCFO";
BA_DEF_REL_ BU_SG_REL_  "GenSigSuprvRespComment" STRING ;
BA_DEF_REL_ BU_SG_REL_  "GenSigTimeoutTime" INT 0 5000;
BA_DEF_DEF_  "VNSigDiagnostic" "No";
BA_DEF_DEF_  "VNSigUnused_4" "No";
BA_DEF_DEF_  "VNSigIntermediate" "No";
BA_DEF_DEF_  "VNSigParkedVehicle" "No";
BA_DEF_DEF_  "VNSigRemoteDiagnostics" "No";
BA_DEF_DEF_  "GenSigSendOnInit" "Not Initialized";
BA_DEF_DEF_  "GenSigSendType" "NoSigSendType";
BA_DEF_DEF_  "GenSigInactiveValue" 0;
BA_DEF_DEF_  "GenSigDeltaValue" 0;
BA_DEF_DEF_  "VNSigAllNodes" "No";
BA_DEF_DEF_  "SignalType" "";
BA_DEF_DEF_  "PacketOrder" 0;
BA_DEF_DEF_  "SignalLongName" "";
BA_DEF_DEF_  "GenSigStartValue" 0;
BA_DEF_DEF_  "TxSignalSendOnInit" "Not Initialized";
BA_DEF_DEF_  "GenMsgILSupport" "Yes";
BA_DEF_DEF_  "TpApplType" "";
BA_DEF_DEF_  "Prio" 0;
BA_DEF_DEF_  "MessageSubnet" "LS";
BA_DEF_DEF_  "DiagState" "No";
BA_DEF_DEF_  "GenMsgIlSupport" "Yes";
BA_DEF_DEF_  "GenMsgStartDelayTime" 0;
BA_DEF_DEF_  "GenMsgDelayTime" 0;
BA_DEF_DEF_  "GenMsgCycleTime" 0;
BA_DEF_DEF_  "GenMsgSendType" "spontanX";
BA_DEF_DEF_  "DiagResponse" "No";
BA_DEF_DEF_  "DiagRequest" "No";
BA_DEF_DEF_  "NmMessage" "No";
BA_DEF_DEF_REL_ "GenSigSuprvResp" "None";
BA_DEF_DEF_REL_ "GenSigSuprvRespSubValue" 0;
BA_DEF_DEF_REL_ "GenSigRxStartValue" "";
BA_DEF_DEF_REL_ "GenSigVDAFailResp" "No";
BA_DEF_DEF_REL_ "GenSigVDAFailComment" "";
BA_DEF_DEF_REL_ "GenSigVBitRespComment" "";
BA_DEF_DEF_REL_ "GenSigVBitResp" "No";
BA_DEF_DEF_REL_ "GenSigSuprvRespComment" "";
BA_DEF_DEF_REL_ "GenSigTimeoutTime" 0;
BA_ "Prio" BO_ 2153381888 4;
BA_ "GenMsgDelayTime" BO_ 2153381888 100;
BA_ "Prio" BO_ 2151514112 4;
BA_ "GenMsgDelayTime" BO_ 2151514112 100;
BA_ "Prio" BO_ 2151153664 4;
BA_ "GenMsgDelayTime" BO_ 2151153664 100;
BA_ "Prio" BO_ 2151874560 4;
BA_ "GenMsgDelayTime" BO_ 2151874560 100;
BA_ "Prio" BO_ 2150268928 4;
BA_ "GenMsgDelayTime" BO_ 2150268928 100;
BA_ "DiagRequest" BO_ 577 1;
BA_ "Prio" BO_ 2156175360 4;
BA_ "GenMsgDelayTime" BO_ 2156175360 50;
BA_ "Prio" BO_ 2155036672 4;
BA_ "GenMsgDelayTime" BO_ 2155036672 100;
BA_ "GenMsgCycleTime" BO_ 2155036672 500;
BA_ "GenMsgSendType" BO_ 2155036672 0;
BA_ "Prio" BO_ 2151186432 4;
BA_ "GenMsgDelayTime" BO_ 2151186432 100;
BA_ "Prio" BO_ 2152062976 4;
BA_ "GenMsgCycleTime" BO_ 2152062976 500;
BA_ "GenMsgSendType" BO_ 2152062976 0;
BA_ "Prio" BO_ 2150711296 4;
BA_ "GenMsgCycleTime" BO_ 2150711296 100;
BA_ "GenMsgSendType" BO_ 2150711296 0;
BA_ "Prio" BO_ 2153406464 4;
BA_ "GenMsgDelayTime" BO_ 2153406464 100;
BA_ "Prio" BO_ 2152177664 4;
BA_ "GenMsgCycleTime" BO_ 2152177664 2000;
BA_ "GenMsgSendType" BO_ 2152177664 0;
BA_ "Prio" BO_ 2154602496 4;
BA_ "GenMsgCycleTime" BO_ 2154602496 1000;
BA_ "GenMsgSendType" BO_ 2154602496 0;
BA_ "Prio" BO_ 2153906176 4;
BA_ "GenMsgDelayTime" BO_ 2153906176 100;
BA_ "Prio" BO_ 2155978752 4;
BA_ "GenMsgDelayTime" BO_ 2155978752 100;
BA_ "Prio" BO_ 2159247360 4;
BA_ "GenMsgDelayTime" BO_ 2159247360 10;
BA_ "Prio" BO_ 2151833600 4;
BA_ "GenMsgDelayTime" BO_ 2151833600 20;
BA_ "Prio" BO_ 2150236160 4;
BA_ "GenMsgDelayTime" BO_ 2150236160 100;
BA_ "GenMsgCycleTime" BO_ 2150236160 1000;
BA_ "GenMsgSendType" BO_ 2150236160 0;
BA_ "Prio" BO_ 2150170624 4;
BA_ "GenMsgDelayTime" BO_ 2150170624 100;
BA_ "GenMsgCycleTime" BO_ 2150170624 1000;
BA_ "GenMsgSendType" BO_ 2150170624 0;
BA_ "Prio" BO_ 2154725376 4;
BA_ "GenMsgDelayTime" BO_ 2154725376 100;
BA_ "Prio" BO_ 2151931904 4;
BA_ "GenMsgDelayTime" BO_ 2151931904 100;
BA_ "Prio" BO_ 2151915520 4;
BA_ "GenMsgCycleTime" BO_ 2151915520 250;
BA_ "GenMsgSendType" BO_ 2151915520 0;
BA_ "Prio" BO_ 2153947136 4;
BA_ "GenMsgDelayTime" BO_ 2153947136 100;
BA_ "Prio" BO_ 2152112128 4;
BA_ "GenMsgDelayTime" BO_ 2152112128 100;
BA_ "Prio" BO_ 2153857024 4;
BA_ "GenMsgDelayTime" BO_ 2153857024 100;
BA_ "Prio" BO_ 2153840640 4;
BA_ "GenMsgDelayTime" BO_ 2153840640 100;
BA_ "Prio" BO_ 2155913216 4;
BA_ "GenMsgCycleTime" BO_ 2155913216 1000;
BA_ "GenMsgSendType" BO_ 2155913216 0;
BA_ "Prio" BO_ 2152095744 4;
BA_ "GenMsgStartDelayTime" BO_ 2152095744 120;
BA_ "GenMsgCycleTime" BO_ 2152095744 2000;
BA_ "GenMsgSendType" BO_ 2152095744 0;
BA_ "Prio" BO_ 2151899136 4;
BA_ "GenMsgCycleTime" BO_ 2151899136 250;
BA_ "GenMsgSendType" BO_ 2151899136 0;
BA_ "Prio" BO_ 2150449152 4;
BA_ "GenMsgDelayTime" BO_ 2150449152 100;
BA_ "Prio" BO_ 2149810176 4;
BA_ "GenMsgDelayTime" BO_ 2149810176 100;
BA_ "Prio" BO_ 2149793792 4;
BA_ "GenMsgDelayTime" BO_ 2149793792 100;
BA_ "Prio" BO_ 2152128512 4;
BA_ "GenMsgCycleTime" BO_ 2152128512 2000;
BA_ "GenMsgSendType" BO_ 2152128512 0;
BA_ "Prio" BO_ 2149924864 4;
BA_ "GenMsgDelayTime" BO_ 2149924864 100;
BA_ "Prio" BO_ 2150301696 4;
BA_ "GenMsgDelayTime" BO_ 2150301696 100;
BA_ "Prio" BO_ 2154856448 4;
BA_ "GenMsgDelayTime" BO_ 2154856448 100;
BA_ "GenSigSendType" SG_ 2153381888 VltActRrAccUnavlIO 10;
BA_ "VNSigAllNodes" SG_ 2153381888 VltActRrAccUnavlIO 1;
BA_ "SignalType" SG_ 2153381888 VltActRrAccUnavlIO "BLN";
BA_ "SignalLongName" SG_ 2153381888 VltActRrAccUnavlIO "Valet Active Rear Access Unavailable Indication On";
BA_ "GenSigSendType" SG_ 2153381888 PwrLftgtMotStat 10;
BA_ "VNSigAllNodes" SG_ 2153381888 PwrLftgtMotStat 1;
BA_ "SignalType" SG_ 2153381888 PwrLftgtMotStat "ENM";
BA_ "SignalLongName" SG_ 2153381888 PwrLftgtMotStat "Power Liftgate Motion Status";
BA_ "GenSigSendType" SG_ 2153381888 VehIncAngEst 12;
BA_ "GenSigDeltaValue" SG_ 2153381888 VehIncAngEst 1;
BA_ "VNSigAllNodes" SG_ 2153381888 VehIncAngEst 1;
BA_ "SignalType" SG_ 2153381888 VehIncAngEst "UNM";
BA_ "SignalLongName" SG_ 2153381888 VehIncAngEst "Vehicle Inclination Angle Estimated";
BA_ "VNSigParkedVehicle" SG_ 2153381888 PwrLftgtInclAngV 1;
BA_ "GenSigSendOnInit" SG_ 2153381888 PwrLftgtInclAngV 1;
BA_ "GenSigSendType" SG_ 2153381888 PwrLftgtInclAngV 10;
BA_ "VNSigAllNodes" SG_ 2153381888 PwrLftgtInclAngV 1;
BA_ "SignalType" SG_ 2153381888 PwrLftgtInclAngV "ENM";
BA_ "SignalLongName" SG_ 2153381888 PwrLftgtInclAngV "Power Liftgate Inclination Angle Validity";
BA_ "GenSigSendOnInit" SG_ 2153381888 FnshRrClsrMtnBfrDrvIO 1;
BA_ "GenSigSendType" SG_ 2153381888 FnshRrClsrMtnBfrDrvIO 10;
BA_ "VNSigAllNodes" SG_ 2153381888 FnshRrClsrMtnBfrDrvIO 1;
BA_ "SignalType" SG_ 2153381888 FnshRrClsrMtnBfrDrvIO "BLN";
BA_ "SignalLongName" SG_ 2153381888 FnshRrClsrMtnBfrDrvIO "Finish Rear Closure Motion Before Driving Indication On";
BA_ "VNSigParkedVehicle" SG_ 2153381888 PwrLftgtInclAng 1;
BA_ "GenSigSendOnInit" SG_ 2153381888 PwrLftgtInclAng 1;
BA_ "GenSigSendType" SG_ 2153381888 PwrLftgtInclAng 12;
BA_ "GenSigDeltaValue" SG_ 2153381888 PwrLftgtInclAng 1;
BA_ "VNSigAllNodes" SG_ 2153381888 PwrLftgtInclAng 1;
BA_ "SignalType" SG_ 2153381888 PwrLftgtInclAng "UNM";
BA_ "SignalLongName" SG_ 2153381888 PwrLftgtInclAng "Power Liftgate Inclination Angle";
BA_ "GenSigSendOnInit" SG_ 2153381888 GrgPrgMdCmpl 1;
BA_ "GenSigSendType" SG_ 2153381888 GrgPrgMdCmpl 10;
BA_ "VNSigAllNodes" SG_ 2153381888 GrgPrgMdCmpl 1;
BA_ "SignalType" SG_ 2153381888 GrgPrgMdCmpl "BLN";
BA_ "SignalLongName" SG_ 2153381888 GrgPrgMdCmpl "Garage Programming Mode Complete";
BA_ "GenSigSendOnInit" SG_ 2153381888 RrClsrObstclDtctd 1;
BA_ "GenSigSendType" SG_ 2153381888 RrClsrObstclDtctd 10;
BA_ "VNSigAllNodes" SG_ 2153381888 RrClsrObstclDtctd 1;
BA_ "SignalType" SG_ 2153381888 RrClsrObstclDtctd "BLN";
BA_ "SignalLongName" SG_ 2153381888 RrClsrObstclDtctd "Rear Closure Obstacle Detected";
BA_ "GenSigSendOnInit" SG_ 2153381888 RrClosOpenSwAct 1;
BA_ "GenSigSendType" SG_ 2153381888 RrClosOpenSwAct 10;
BA_ "VNSigAllNodes" SG_ 2153381888 RrClosOpenSwAct 1;
BA_ "SignalType" SG_ 2153381888 RrClosOpenSwAct "BLN";
BA_ "SignalLongName" SG_ 2153381888 RrClosOpenSwAct "Rear Closure Open Switch Active";
BA_ "GenSigSendType" SG_ 2153381888 RrClosOpenSwActV 10;
BA_ "VNSigAllNodes" SG_ 2153381888 RrClosOpenSwActV 1;
BA_ "SignalType" SG_ 2153381888 RrClosOpenSwActV "ENM";
BA_ "SignalLongName" SG_ 2153381888 RrClosOpenSwActV "Rear Closure Open Switch Active Validity";
BA_ "GenSigSendOnInit" SG_ 2153381888 RrClsrInMtn 1;
BA_ "GenSigSendType" SG_ 2153381888 RrClsrInMtn 10;
BA_ "VNSigAllNodes" SG_ 2153381888 RrClsrInMtn 1;
BA_ "SignalType" SG_ 2153381888 RrClsrInMtn "BLN";
BA_ "SignalLongName" SG_ 2153381888 RrClsrInMtn "Rear Closure In Motion";
BA_ "GenSigSendType" SG_ 2153381888 RrWprInhbRq 10;
BA_ "VNSigAllNodes" SG_ 2153381888 RrWprInhbRq 1;
BA_ "SignalType" SG_ 2153381888 RrWprInhbRq "BLN";
BA_ "SignalLongName" SG_ 2153381888 RrWprInhbRq "Rear Wiper Inhibit Request";
BA_ "GenSigSendType" SG_ 2151514112 EngOilLfRstRq 10;
BA_ "VNSigAllNodes" SG_ 2151514112 EngOilLfRstRq 1;
BA_ "SignalType" SG_ 2151514112 EngOilLfRstRq "BLN";
BA_ "SignalLongName" SG_ 2151514112 EngOilLfRstRq "Engine Oil Life Reset Request";
BA_ "GenSigSendOnInit" SG_ 2151153664 RrWndDfgOn 1;
BA_ "GenSigSendType" SG_ 2151153664 RrWndDfgOn 10;
BA_ "VNSigAllNodes" SG_ 2151153664 RrWndDfgOn 1;
BA_ "SignalType" SG_ 2151153664 RrWndDfgOn "BLN";
BA_ "SignalLongName" SG_ 2151153664 RrWndDfgOn "Rear Window Defog On";
BA_ "GenSigSendType" SG_ 2151874560 RstVTDTmprDtctd 10;
BA_ "VNSigAllNodes" SG_ 2151874560 RstVTDTmprDtctd 1;
BA_ "SignalType" SG_ 2151874560 RstVTDTmprDtctd "ENM";
BA_ "SignalLongName" SG_ 2151874560 RstVTDTmprDtctd "Reset Vehicle Theft Deterrent Tamper Detected";
BA_ "GenSigSendType" SG_ 2151874560 RstIllDrIdDevDtctd 10;
BA_ "VNSigAllNodes" SG_ 2151874560 RstIllDrIdDevDtctd 1;
BA_ "SignalType" SG_ 2151874560 RstIllDrIdDevDtctd "ENM";
BA_ "SignalLongName" SG_ 2151874560 RstIllDrIdDevDtctd "Reset Illegitimate Driver Identification Device Detected";
BA_ "GenSigSendType" SG_ 2151874560 RstDrIdDevLrnd 10;
BA_ "VNSigAllNodes" SG_ 2151874560 RstDrIdDevLrnd 1;
BA_ "SignalType" SG_ 2151874560 RstDrIdDevLrnd "ENM";
BA_ "SignalLongName" SG_ 2151874560 RstDrIdDevLrnd "Reset Driver Identification Device Learned";
BA_ "GenSigSendType" SG_ 2151874560 ESEIC_EngImRqPsw 10;
BA_ "VNSigAllNodes" SG_ 2151874560 ESEIC_EngImRqPsw 1;
BA_ "SignalType" SG_ 2151874560 ESEIC_EngImRqPsw "ASC";
BA_ "PacketOrder" SG_ 2151874560 ESEIC_EngImRqPsw 2;
BA_ "SignalLongName" SG_ 2151874560 ESEIC_EngImRqPsw "Enhanced Services Engine Immobilization Command : Enhanced Services Engine Immobilization Request Password";
BA_ "GenSigSendType" SG_ 2151874560 ESEIC_EngImmbRq 10;
BA_ "VNSigAllNodes" SG_ 2151874560 ESEIC_EngImmbRq 1;
BA_ "SignalType" SG_ 2151874560 ESEIC_EngImmbRq "ENM";
BA_ "PacketOrder" SG_ 2151874560 ESEIC_EngImmbRq 1;
BA_ "SignalLongName" SG_ 2151874560 ESEIC_EngImmbRq "Enhanced Services Engine Immobilization Command : Enhanced Services Engine Immobilization Request";
BA_ "GenSigSendType" SG_ 2150268928 EmrgncyRspSysTyp 10;
BA_ "VNSigAllNodes" SG_ 2150268928 EmrgncyRspSysTyp 1;
BA_ "SignalType" SG_ 2150268928 EmrgncyRspSysTyp "ENM";
BA_ "SignalLongName" SG_ 2150268928 EmrgncyRspSysTyp "Emergency Response System Type";
BA_ "GenSigSendOnInit" SG_ 2150268928 EmrgncyRspSysSrvIndOn 1;
BA_ "GenSigSendType" SG_ 2150268928 EmrgncyRspSysSrvIndOn 10;
BA_ "VNSigAllNodes" SG_ 2150268928 EmrgncyRspSysSrvIndOn 1;
BA_ "SignalType" SG_ 2150268928 EmrgncyRspSysSrvIndOn "BLN";
BA_ "SignalLongName" SG_ 2150268928 EmrgncyRspSysSrvIndOn "Emergency Response System Service Indication On";
BA_ "GenSigSendOnInit" SG_ 2150268928 CldrYr_154 1;
BA_ "GenSigSendType" SG_ 2150268928 CldrYr_154 12;
BA_ "GenSigDeltaValue" SG_ 2150268928 CldrYr_154 1;
BA_ "VNSigAllNodes" SG_ 2150268928 CldrYr_154 1;
BA_ "SignalType" SG_ 2150268928 CldrYr_154 "UNM";
BA_ "SignalLongName" SG_ 2150268928 CldrYr_154 "Calendar Year";
BA_ "GenSigSendOnInit" SG_ 2150268928 CldrMth_154 1;
BA_ "GenSigSendType" SG_ 2150268928 CldrMth_154 10;
BA_ "VNSigAllNodes" SG_ 2150268928 CldrMth_154 1;
BA_ "SignalType" SG_ 2150268928 CldrMth_154 "ENM";
BA_ "SignalLongName" SG_ 2150268928 CldrMth_154 "Calendar Month";
BA_ "GenSigSendOnInit" SG_ 2150268928 CldrDay_154 1;
BA_ "GenSigSendType" SG_ 2150268928 CldrDay_154 12;
BA_ "GenSigDeltaValue" SG_ 2150268928 CldrDay_154 1;
BA_ "VNSigAllNodes" SG_ 2150268928 CldrDay_154 1;
BA_ "SignalType" SG_ 2150268928 CldrDay_154 "UNM";
BA_ "SignalLongName" SG_ 2150268928 CldrDay_154 "Calendar Day";
BA_ "GenSigSendOnInit" SG_ 2150268928 SecV 1;
BA_ "GenSigSendType" SG_ 2150268928 SecV 10;
BA_ "VNSigAllNodes" SG_ 2150268928 SecV 1;
BA_ "SignalType" SG_ 2150268928 SecV "ENM";
BA_ "SignalLongName" SG_ 2150268928 SecV "Seconds Validity";
BA_ "GenSigSendOnInit" SG_ 2150268928 Sec 1;
BA_ "GenSigSendType" SG_ 2150268928 Sec 12;
BA_ "GenSigDeltaValue" SG_ 2150268928 Sec 1;
BA_ "VNSigAllNodes" SG_ 2150268928 Sec 1;
BA_ "SignalType" SG_ 2150268928 Sec "UNM";
BA_ "SignalLongName" SG_ 2150268928 Sec "Seconds";
BA_ "GenSigSendOnInit" SG_ 2150268928 MinsV 1;
BA_ "GenSigSendType" SG_ 2150268928 MinsV 10;
BA_ "VNSigAllNodes" SG_ 2150268928 MinsV 1;
BA_ "SignalType" SG_ 2150268928 MinsV "ENM";
BA_ "SignalLongName" SG_ 2150268928 MinsV "Minutes Validity";
BA_ "GenSigSendOnInit" SG_ 2150268928 Mins 1;
BA_ "GenSigSendType" SG_ 2150268928 Mins 12;
BA_ "GenSigDeltaValue" SG_ 2150268928 Mins 1;
BA_ "VNSigAllNodes" SG_ 2150268928 Mins 1;
BA_ "SignalType" SG_ 2150268928 Mins "UNM";
BA_ "SignalLongName" SG_ 2150268928 Mins "Minutes";
BA_ "GenSigSendOnInit" SG_ 2150268928 HrsV 1;
BA_ "GenSigSendType" SG_ 2150268928 HrsV 10;
BA_ "VNSigAllNodes" SG_ 2150268928 HrsV 1;
BA_ "SignalType" SG_ 2150268928 HrsV "ENM";
BA_ "SignalLongName" SG_ 2150268928 HrsV "Hours Validity";
BA_ "GenSigSendOnInit" SG_ 2150268928 Hrs 1;
BA_ "GenSigSendType" SG_ 2150268928 Hrs 12;
BA_ "GenSigDeltaValue" SG_ 2150268928 Hrs 1;
BA_ "VNSigAllNodes" SG_ 2150268928 Hrs 1;
BA_ "SignalType" SG_ 2150268928 Hrs "UNM";
BA_ "SignalLongName" SG_ 2150268928 Hrs "Hours";
BA_ "GenSigSendType" SG_ 2041 PCUInfo_7F9 12;
BA_ "GenSigDeltaValue" SG_ 2041 PCUInfo_7F9 1;
BA_ "VNSigAllNodes" SG_ 2041 PCUInfo_7F9 1;
BA_ "SignalType" SG_ 2041 PCUInfo_7F9 "UNM";
BA_ "SignalLongName" SG_ 2041 PCUInfo_7F9 "Pyrotechnical Control Unit Information 7F9";
BA_ "VNSigDiagnostic" SG_ 577 DgnInf 1;
BA_ "GenSigSendType" SG_ 577 DgnInf 12;
BA_ "GenSigDeltaValue" SG_ 577 DgnInf 1;
BA_ "VNSigAllNodes" SG_ 577 DgnInf 1;
BA_ "SignalType" SG_ 577 DgnInf "UNM";
BA_ "SignalLongName" SG_ 577 DgnInf "Diagnostic Information";
BA_ "GenSigSendOnInit" SG_ 2156175360 DispMeasSys 1;
BA_ "GenSigSendType" SG_ 2156175360 DispMeasSys 10;
BA_ "VNSigAllNodes" SG_ 2156175360 DispMeasSys 1;
BA_ "SignalType" SG_ 2156175360 DispMeasSys "ENM";
BA_ "SignalLongName" SG_ 2156175360 DispMeasSys "Display Measurement System";
BA_ "GenSigSendType" SG_ 2156175360 NtVsnSysEnbld 10;
BA_ "VNSigAllNodes" SG_ 2156175360 NtVsnSysEnbld 1;
BA_ "SignalType" SG_ 2156175360 NtVsnSysEnbld "BLN";
BA_ "SignalLongName" SG_ 2156175360 NtVsnSysEnbld "Night Vision System Enabled";
BA_ "GenSigSendOnInit" SG_ 2156175360 DispMeasSysExt 1;
BA_ "GenSigSendType" SG_ 2156175360 DispMeasSysExt 10;
BA_ "VNSigAllNodes" SG_ 2156175360 DispMeasSysExt 1;
BA_ "SignalType" SG_ 2156175360 DispMeasSysExt "ENM";
BA_ "SignalLongName" SG_ 2156175360 DispMeasSysExt "Display Measurement System Extended";
BA_ "GenSigSendOnInit" SG_ 2155036672 ACCompModReq 2;
BA_ "GenSigSendType" SG_ 2155036672 ACCompModReq 10;
BA_ "VNSigAllNodes" SG_ 2155036672 ACCompModReq 1;
BA_ "SignalType" SG_ 2155036672 ACCompModReq "ENM";
BA_ "SignalLongName" SG_ 2155036672 ACCompModReq "Air Conditioning Compressor Mode Request";
BA_ "GenSigSendOnInit" SG_ 2155036672 ACCompNormLdV 1;
BA_ "GenSigSendType" SG_ 2155036672 ACCompNormLdV 10;
BA_ "VNSigAllNodes" SG_ 2155036672 ACCompNormLdV 1;
BA_ "SignalType" SG_ 2155036672 ACCompNormLdV "ENM";
BA_ "SignalLongName" SG_ 2155036672 ACCompNormLdV "Air Conditioning Compressor Normalized Load Validity";
BA_ "GenSigSendOnInit" SG_ 2155036672 ACCompNormLd 1;
BA_ "GenSigSendType" SG_ 2155036672 ACCompNormLd 12;
BA_ "GenSigDeltaValue" SG_ 2155036672 ACCompNormLd 1;
BA_ "VNSigAllNodes" SG_ 2155036672 ACCompNormLd 1;
BA_ "SignalType" SG_ 2155036672 ACCompNormLd "UNM";
BA_ "SignalLongName" SG_ 2155036672 ACCompNormLd "Air Conditioning Compressor Normalized Load";
BA_ "GenSigSendType" SG_ 2155036672 ACCmEngRunReq 10;
BA_ "VNSigAllNodes" SG_ 2155036672 ACCmEngRunReq 1;
BA_ "SignalType" SG_ 2155036672 ACCmEngRunReq "ENM";
BA_ "SignalLongName" SG_ 2155036672 ACCmEngRunReq "Air Conditioning Compressor Engine Run Request";
BA_ "GenSigSendType" SG_ 2155036672 ACCmpsrFldOn 10;
BA_ "VNSigAllNodes" SG_ 2155036672 ACCmpsrFldOn 1;
BA_ "SignalType" SG_ 2155036672 ACCmpsrFldOn "BLN";
BA_ "SignalLongName" SG_ 2155036672 ACCmpsrFldOn "Air Conditioning Compressor Failed On";
BA_ "GenSigSendType" SG_ 2155036672 ClmtCtrlTrgtTemp 12;
BA_ "GenSigDeltaValue" SG_ 2155036672 ClmtCtrlTrgtTemp 1;
BA_ "VNSigAllNodes" SG_ 2155036672 ClmtCtrlTrgtTemp 1;
BA_ "SignalType" SG_ 2155036672 ClmtCtrlTrgtTemp "UNM";
BA_ "SignalLongName" SG_ 2155036672 ClmtCtrlTrgtTemp "Climate Control Target Temperature";
BA_ "GenSigSendType" SG_ 2151186432 AutoHgBmCtrlInOn 10;
BA_ "VNSigAllNodes" SG_ 2151186432 AutoHgBmCtrlInOn 1;
BA_ "SignalType" SG_ 2151186432 AutoHgBmCtrlInOn "BLN";
BA_ "SignalLongName" SG_ 2151186432 AutoHgBmCtrlInOn "Auto High Beam Control Indication On";
BA_ "GenSigSendOnInit" SG_ 2151186432 CtLghtDet 2;
BA_ "GenSigSendType" SG_ 2151186432 CtLghtDet 10;
BA_ "VNSigAllNodes" SG_ 2151186432 CtLghtDet 1;
BA_ "SignalType" SG_ 2151186432 CtLghtDet "BLN";
BA_ "SignalLongName" SG_ 2151186432 CtLghtDet "City Light Detected";
BA_ "GenSigSendOnInit" SG_ 2151186432 AutoBmSlctStat 2;
BA_ "GenSigSendType" SG_ 2151186432 AutoBmSlctStat 10;
BA_ "VNSigAllNodes" SG_ 2151186432 AutoBmSlctStat 1;
BA_ "SignalType" SG_ 2151186432 AutoBmSlctStat "ENM";
BA_ "SignalLongName" SG_ 2151186432 AutoBmSlctStat "Automatic Beam Select Status";
BA_ "VNSigAllNodes" SG_ 2152062976 ThrmlRefCompStatFdbck 1;
BA_ "SignalType" SG_ 2152062976 ThrmlRefCompStatFdbck "ENM";
BA_ "SignalLongName" SG_ 2152062976 ThrmlRefCompStatFdbck "Thermal Refrigerant Compressor Status Feedback";
BA_ "VNSigAllNodes" SG_ 2152062976 ThrmlRefCompSpdFdbck 1;
BA_ "SignalType" SG_ 2152062976 ThrmlRefCompSpdFdbck "UNM";
BA_ "SignalLongName" SG_ 2152062976 ThrmlRefCompSpdFdbck "Thermal Refrigerant Compressor Speed Feedback";
BA_ "VNSigAllNodes" SG_ 2150711296 TachEngSpd 1;
BA_ "SignalType" SG_ 2150711296 TachEngSpd "UNM";
BA_ "SignalLongName" SG_ 2150711296 TachEngSpd "Tachometer Engine Speed";
BA_ "GenSigSendOnInit" SG_ 2153406464 RrClsrInrAjrSwAct 1;
BA_ "GenSigSendType" SG_ 2153406464 RrClsrInrAjrSwAct 10;
BA_ "VNSigAllNodes" SG_ 2153406464 RrClsrInrAjrSwAct 1;
BA_ "SignalType" SG_ 2153406464 RrClsrInrAjrSwAct "BLN";
BA_ "SignalLongName" SG_ 2153406464 RrClsrInrAjrSwAct "Rear Closure Inner Ajar Switch Active";
BA_ "GenSigSendOnInit" SG_ 2153406464 TlgtUnavlbleIO 1;
BA_ "GenSigSendType" SG_ 2153406464 TlgtUnavlbleIO 10;
BA_ "VNSigAllNodes" SG_ 2153406464 TlgtUnavlbleIO 1;
BA_ "SignalType" SG_ 2153406464 TlgtUnavlbleIO "BLN";
BA_ "SignalLongName" SG_ 2153406464 TlgtUnavlbleIO "Tailgate Unavailable Indication On";
BA_ "VNSigAllNodes" SG_ 2152177664 RmtRflshElecPwrRdness 1;
BA_ "SignalType" SG_ 2152177664 RmtRflshElecPwrRdness "UNM";
BA_ "SignalLongName" SG_ 2152177664 RmtRflshElecPwrRdness "Remote Reflash Electric Power Readiness";
BA_ "VNSigAllNodes" SG_ 2154602496 EHCCT_EHtrCrOutClntTmp 1;
BA_ "SignalType" SG_ 2154602496 EHCCT_EHtrCrOutClntTmp "UNM";
BA_ "PacketOrder" SG_ 2154602496 EHCCT_EHtrCrOutClntTmp 4;
BA_ "SignalLongName" SG_ 2154602496 EHCCT_EHtrCrOutClntTmp "Estimated Heater Core Coolant Temperature : Estimated Heater Core Out Coolant Temperature";
BA_ "GenSigStartValue" SG_ 2154602496 EHCCT_EHtrCrOutClntTmp 565.428109854604;
BA_ "VNSigAllNodes" SG_ 2154602496 EHCCT_EHtrCrInClntTmp 1;
BA_ "SignalType" SG_ 2154602496 EHCCT_EHtrCrInClntTmp "UNM";
BA_ "PacketOrder" SG_ 2154602496 EHCCT_EHtrCrInClntTmp 3;
BA_ "SignalLongName" SG_ 2154602496 EHCCT_EHtrCrInClntTmp "Estimated Heater Core Coolant Temperature : Estimated Heater Core In Coolant Temperature";
BA_ "GenSigStartValue" SG_ 2154602496 EHCCT_EHtrCrInClntTmp 619.278406031233;
BA_ "VNSigAllNodes" SG_ 2154602496 EHCCT_EHtrCrOutClntTmpV 1;
BA_ "SignalType" SG_ 2154602496 EHCCT_EHtrCrOutClntTmpV "ENM";
BA_ "PacketOrder" SG_ 2154602496 EHCCT_EHtrCrOutClntTmpV 2;
BA_ "SignalLongName" SG_ 2154602496 EHCCT_EHtrCrOutClntTmpV "Estimated Heater Core Coolant Temperature : Estimated Heater Core Out Coolant Temperature Validity";
BA_ "VNSigAllNodes" SG_ 2154602496 EHCCT_EHtrCrInClntTmpV 1;
BA_ "SignalType" SG_ 2154602496 EHCCT_EHtrCrInClntTmpV "ENM";
BA_ "PacketOrder" SG_ 2154602496 EHCCT_EHtrCrInClntTmpV 1;
BA_ "SignalLongName" SG_ 2154602496 EHCCT_EHtrCrInClntTmpV "Estimated Heater Core Coolant Temperature : Estimated Heater Core In Coolant Temperature Validity";
BA_ "VNSigAllNodes" SG_ 2154602496 EstHtrCrClntFlwrtFdbkV 1;
BA_ "SignalType" SG_ 2154602496 EstHtrCrClntFlwrtFdbkV "ENM";
BA_ "SignalLongName" SG_ 2154602496 EstHtrCrClntFlwrtFdbkV "Estimated Heater Core Coolant Flowrate Feedback Validity";
BA_ "VNSigAllNodes" SG_ 2154602496 EstHtrCrClntFlwrtFdbk 1;
BA_ "SignalType" SG_ 2154602496 EstHtrCrClntFlwrtFdbk "UNM";
BA_ "SignalLongName" SG_ 2154602496 EstHtrCrClntFlwrtFdbk "Estimated Heater Core Coolant Flowrate Feedback";
BA_ "VNSigAllNodes" SG_ 2154602496 CCFrBlwFnSpdFbkRatV 1;
BA_ "SignalType" SG_ 2154602496 CCFrBlwFnSpdFbkRatV "ENM";
BA_ "SignalLongName" SG_ 2154602496 CCFrBlwFnSpdFbkRatV "Climate Control Front Blower Fan Speed Feedback Rationalized Validity";
BA_ "VNSigAllNodes" SG_ 2154602496 CCFrBlwFnSpdFbkRat 1;
BA_ "SignalType" SG_ 2154602496 CCFrBlwFnSpdFbkRat "UNM";
BA_ "SignalLongName" SG_ 2154602496 CCFrBlwFnSpdFbkRat "Climate Control Front Blower Fan Speed Feedback Rationalized";
BA_ "GenSigSendType" SG_ 2153906176 BrkSysVTopSpdLimVal 12;
BA_ "GenSigDeltaValue" SG_ 2153906176 BrkSysVTopSpdLimVal 1;
BA_ "VNSigAllNodes" SG_ 2153906176 BrkSysVTopSpdLimVal 1;
BA_ "SignalType" SG_ 2153906176 BrkSysVTopSpdLimVal "UNM";
BA_ "SignalLongName" SG_ 2153906176 BrkSysVTopSpdLimVal "Braking System Vehicle Top Speed Limit Value";
BA_ "GenSigStartValue" SG_ 2153906176 BrkSysVTopSpdLimVal 255;
BA_ "GenSigSendType" SG_ 2153906176 BrkSysVTopSpdLimIO 10;
BA_ "VNSigAllNodes" SG_ 2153906176 BrkSysVTopSpdLimIO 1;
BA_ "SignalType" SG_ 2153906176 BrkSysVTopSpdLimIO "BLN";
BA_ "SignalLongName" SG_ 2153906176 BrkSysVTopSpdLimIO "Braking System Vehicle Top Speed Limit Indication On";
BA_ "GenSigSendOnInit" SG_ 2153906176 ValetModeSpdLimDispVal 2;
BA_ "GenSigSendType" SG_ 2153906176 ValetModeSpdLimDispVal 12;
BA_ "GenSigDeltaValue" SG_ 2153906176 ValetModeSpdLimDispVal 1;
BA_ "VNSigAllNodes" SG_ 2153906176 ValetModeSpdLimDispVal 1;
BA_ "SignalType" SG_ 2153906176 ValetModeSpdLimDispVal "UNM";
BA_ "SignalLongName" SG_ 2153906176 ValetModeSpdLimDispVal "Valet Mode Speed Limit Display Value";
BA_ "GenSigSendOnInit" SG_ 2153906176 ValetModeSpdLimIO 2;
BA_ "GenSigSendType" SG_ 2153906176 ValetModeSpdLimIO 10;
BA_ "VNSigAllNodes" SG_ 2153906176 ValetModeSpdLimIO 1;
BA_ "SignalType" SG_ 2153906176 ValetModeSpdLimIO "BLN";
BA_ "SignalLongName" SG_ 2153906176 ValetModeSpdLimIO "Valet Mode Speed Limit Indication On";
BA_ "GenSigSendOnInit" SG_ 2153906176 ValetModeAccelLimIO 2;
BA_ "GenSigSendType" SG_ 2153906176 ValetModeAccelLimIO 10;
BA_ "VNSigAllNodes" SG_ 2153906176 ValetModeAccelLimIO 1;
BA_ "SignalType" SG_ 2153906176 ValetModeAccelLimIO "BLN";
BA_ "SignalLongName" SG_ 2153906176 ValetModeAccelLimIO "Valet Mode Acceleration Limit Indication On";
BA_ "GenSigSendOnInit" SG_ 2153906176 TDLKARptCrdDspDtAvail 2;
BA_ "GenSigSendType" SG_ 2153906176 TDLKARptCrdDspDtAvail 10;
BA_ "VNSigAllNodes" SG_ 2153906176 TDLKARptCrdDspDtAvail 1;
BA_ "SignalType" SG_ 2153906176 TDLKARptCrdDspDtAvail "BLN";
BA_ "SignalLongName" SG_ 2153906176 TDLKARptCrdDspDtAvail "Teen Driver Lane Keep Assist Report Card Display Data Available";
BA_ "GenSigSendOnInit" SG_ 2153906176 TnDrvLKAEvntsRptDt 2;
BA_ "GenSigSendType" SG_ 2153906176 TnDrvLKAEvntsRptDt 12;
BA_ "GenSigDeltaValue" SG_ 2153906176 TnDrvLKAEvntsRptDt 1;
BA_ "VNSigAllNodes" SG_ 2153906176 TnDrvLKAEvntsRptDt 1;
BA_ "SignalType" SG_ 2153906176 TnDrvLKAEvntsRptDt "UNM";
BA_ "SignalLongName" SG_ 2153906176 TnDrvLKAEvntsRptDt "Teen Driver Lane Keep Assist Events Report Data";
BA_ "GenSigSendOnInit" SG_ 2153906176 TDODDRptCrdDspDtAvail 2;
BA_ "GenSigSendType" SG_ 2153906176 TDODDRptCrdDspDtAvail 10;
BA_ "VNSigAllNodes" SG_ 2153906176 TDODDRptCrdDspDtAvail 1;
BA_ "SignalType" SG_ 2153906176 TDODDRptCrdDspDtAvail "BLN";
BA_ "SignalLongName" SG_ 2153906176 TDODDRptCrdDspDtAvail "Teen Driver Overspeed Distance Driven Report Card Display Data Available";
BA_ "GenSigSendOnInit" SG_ 2153906176 TDOvrspdDstDrvnRpt 2;
BA_ "GenSigSendType" SG_ 2153906176 TDOvrspdDstDrvnRpt 12;
BA_ "GenSigDeltaValue" SG_ 2153906176 TDOvrspdDstDrvnRpt 1;
BA_ "VNSigAllNodes" SG_ 2153906176 TDOvrspdDstDrvnRpt 1;
BA_ "SignalType" SG_ 2153906176 TDOvrspdDstDrvnRpt "UNM";
BA_ "SignalLongName" SG_ 2153906176 TDOvrspdDstDrvnRpt "Teen Driver Overspeed Distance Driven Report";
BA_ "GenSigSendOnInit" SG_ 2153906176 TDUDDRptCrdDspDtAvail 2;
BA_ "GenSigSendType" SG_ 2153906176 TDUDDRptCrdDspDtAvail 10;
BA_ "VNSigAllNodes" SG_ 2153906176 TDUDDRptCrdDspDtAvail 1;
BA_ "SignalType" SG_ 2153906176 TDUDDRptCrdDspDtAvail "BLN";
BA_ "SignalLongName" SG_ 2153906176 TDUDDRptCrdDspDtAvail "Teen Driver Unbuckled Distance Driven Report Card Display Data Available";
BA_ "GenSigSendOnInit" SG_ 2153906176 TDUnbkldDstDrvnRpt 2;
BA_ "GenSigSendType" SG_ 2153906176 TDUnbkldDstDrvnRpt 12;
BA_ "GenSigDeltaValue" SG_ 2153906176 TDUnbkldDstDrvnRpt 1;
BA_ "VNSigAllNodes" SG_ 2153906176 TDUnbkldDstDrvnRpt 1;
BA_ "SignalType" SG_ 2153906176 TDUnbkldDstDrvnRpt "UNM";
BA_ "SignalLongName" SG_ 2153906176 TDUnbkldDstDrvnRpt "Teen Driver Unbuckled Distance Driven Report";
BA_ "GenSigSendType" SG_ 2155978752 BrkPdLfRrCnfrmReplcmntIO 10;
BA_ "VNSigAllNodes" SG_ 2155978752 BrkPdLfRrCnfrmReplcmntIO 1;
BA_ "SignalType" SG_ 2155978752 BrkPdLfRrCnfrmReplcmntIO "BLN";
BA_ "SignalLongName" SG_ 2155978752 BrkPdLfRrCnfrmReplcmntIO "Brake Pad Life Rear Confirm Replacement Indication On";
BA_ "GenSigSendType" SG_ 2155978752 BrkPdLfFrtCnfrmReplcmntIO 10;
BA_ "VNSigAllNodes" SG_ 2155978752 BrkPdLfFrtCnfrmReplcmntIO 1;
BA_ "SignalType" SG_ 2155978752 BrkPdLfFrtCnfrmReplcmntIO "BLN";
BA_ "SignalLongName" SG_ 2155978752 BrkPdLfFrtCnfrmReplcmntIO "Brake Pad Life Front Confirm Replacement Indication On";
BA_ "GenSigSendType" SG_ 2155978752 ABSActIO 10;
BA_ "VNSigAllNodes" SG_ 2155978752 ABSActIO 1;
BA_ "SignalType" SG_ 2155978752 ABSActIO "BLN";
BA_ "SignalLongName" SG_ 2155978752 ABSActIO "Antilock Brake System Active Indication On";
BA_ "GenSigSendType" SG_ 2155978752 CrwlModeDndRsnIndReq 10;
BA_ "VNSigAllNodes" SG_ 2155978752 CrwlModeDndRsnIndReq 1;
BA_ "SignalType" SG_ 2155978752 CrwlModeDndRsnIndReq "ENM";
BA_ "SignalLongName" SG_ 2155978752 CrwlModeDndRsnIndReq "Crawl Mode Denied Reason Indication Request";
BA_ "GenSigSendType" SG_ 2155978752 BrkPdLfRrDstRmng 12;
BA_ "GenSigDeltaValue" SG_ 2155978752 BrkPdLfRrDstRmng 1;
BA_ "VNSigAllNodes" SG_ 2155978752 BrkPdLfRrDstRmng 1;
BA_ "SignalType" SG_ 2155978752 BrkPdLfRrDstRmng "UNM";
BA_ "SignalLongName" SG_ 2155978752 BrkPdLfRrDstRmng "Brake Pad Life Rear Distance Remaining";
BA_ "GenSigSendType" SG_ 2155978752 BrkPdLfFrtDstRmng 12;
BA_ "GenSigDeltaValue" SG_ 2155978752 BrkPdLfFrtDstRmng 1;
BA_ "VNSigAllNodes" SG_ 2155978752 BrkPdLfFrtDstRmng 1;
BA_ "SignalType" SG_ 2155978752 BrkPdLfFrtDstRmng "UNM";
BA_ "SignalLongName" SG_ 2155978752 BrkPdLfFrtDstRmng "Brake Pad Life Front Distance Remaining";
BA_ "GenSigSendType" SG_ 2155978752 BrkPdLfRrDstWrnIndRq 10;
BA_ "VNSigAllNodes" SG_ 2155978752 BrkPdLfRrDstWrnIndRq 1;
BA_ "SignalType" SG_ 2155978752 BrkPdLfRrDstWrnIndRq "ENM";
BA_ "SignalLongName" SG_ 2155978752 BrkPdLfRrDstWrnIndRq "Brake Pad Life Rear Distance Warning Indication Request";
BA_ "GenSigSendType" SG_ 2155978752 BrkPdLfFrtDstWrnIndRq 10;
BA_ "VNSigAllNodes" SG_ 2155978752 BrkPdLfFrtDstWrnIndRq 1;
BA_ "SignalType" SG_ 2155978752 BrkPdLfFrtDstWrnIndRq "ENM";
BA_ "SignalLongName" SG_ 2155978752 BrkPdLfFrtDstWrnIndRq "Brake Pad Life Front Distance Warning Indication Request";
BA_ "GenSigSendType" SG_ 2155978752 BrkPdLfRrRstAvail 10;
BA_ "VNSigAllNodes" SG_ 2155978752 BrkPdLfRrRstAvail 1;
BA_ "SignalType" SG_ 2155978752 BrkPdLfRrRstAvail "BLN";
BA_ "SignalLongName" SG_ 2155978752 BrkPdLfRrRstAvail "Brake Pad Life Rear Reset Available";
BA_ "GenSigSendType" SG_ 2155978752 BrkPdLfFrtRstAvail 10;
BA_ "VNSigAllNodes" SG_ 2155978752 BrkPdLfFrtRstAvail 1;
BA_ "SignalType" SG_ 2155978752 BrkPdLfFrtRstAvail "BLN";
BA_ "SignalLongName" SG_ 2155978752 BrkPdLfFrtRstAvail "Brake Pad Life Front Reset Available";
BA_ "GenSigSendType" SG_ 2155978752 BrkPdLfRrV 10;
BA_ "VNSigAllNodes" SG_ 2155978752 BrkPdLfRrV 1;
BA_ "SignalType" SG_ 2155978752 BrkPdLfRrV "ENM";
BA_ "SignalLongName" SG_ 2155978752 BrkPdLfRrV "Brake Pad Life Rear Validity";
BA_ "GenSigSendType" SG_ 2155978752 BrkPdLfRr 12;
BA_ "GenSigDeltaValue" SG_ 2155978752 BrkPdLfRr 1;
BA_ "VNSigAllNodes" SG_ 2155978752 BrkPdLfRr 1;
BA_ "SignalType" SG_ 2155978752 BrkPdLfRr "UNM";
BA_ "SignalLongName" SG_ 2155978752 BrkPdLfRr "Brake Pad Life Rear";
BA_ "GenSigSendType" SG_ 2155978752 BrkPdLfFrtV 10;
BA_ "VNSigAllNodes" SG_ 2155978752 BrkPdLfFrtV 1;
BA_ "SignalType" SG_ 2155978752 BrkPdLfFrtV "ENM";
BA_ "SignalLongName" SG_ 2155978752 BrkPdLfFrtV "Brake Pad Life Front Validity";
BA_ "GenSigSendType" SG_ 2155978752 BrkPdLfFrt 12;
BA_ "GenSigDeltaValue" SG_ 2155978752 BrkPdLfFrt 1;
BA_ "VNSigAllNodes" SG_ 2155978752 BrkPdLfFrt 1;
BA_ "SignalType" SG_ 2155978752 BrkPdLfFrt "UNM";
BA_ "SignalLongName" SG_ 2155978752 BrkPdLfFrt "Brake Pad Life Front";
BA_ "GenSigSendOnInit" SG_ 2155978752 BrkPdLfStatIndRq 2;
BA_ "GenSigSendType" SG_ 2155978752 BrkPdLfStatIndRq 10;
BA_ "VNSigAllNodes" SG_ 2155978752 BrkPdLfStatIndRq 1;
BA_ "SignalType" SG_ 2155978752 BrkPdLfStatIndRq "ENM";
BA_ "SignalLongName" SG_ 2155978752 BrkPdLfStatIndRq "Brake Pad Life Status Indication Request";
BA_ "GenSigSendType" SG_ 2155978752 EngAirFltLfRmn 12;
BA_ "GenSigDeltaValue" SG_ 2155978752 EngAirFltLfRmn 1;
BA_ "VNSigAllNodes" SG_ 2155978752 EngAirFltLfRmn 1;
BA_ "SignalType" SG_ 2155978752 EngAirFltLfRmn "UNM";
BA_ "SignalLongName" SG_ 2155978752 EngAirFltLfRmn "Engine Air Filter Life Remaining";
BA_ "GenSigSendOnInit" SG_ 2155978752 EngAirFltMonSt 2;
BA_ "GenSigSendType" SG_ 2155978752 EngAirFltMonSt 10;
BA_ "VNSigAllNodes" SG_ 2155978752 EngAirFltMonSt 1;
BA_ "SignalType" SG_ 2155978752 EngAirFltMonSt "ENM";
BA_ "SignalLongName" SG_ 2155978752 EngAirFltMonSt "Engine Air Filter Monitor Status";
BA_ "GenSigSendType" SG_ 2159247360 ODI_BCM2CntrStck 12;
BA_ "GenSigDeltaValue" SG_ 2159247360 ODI_BCM2CntrStck 1;
BA_ "VNSigAllNodes" SG_ 2159247360 ODI_BCM2CntrStck 1;
BA_ "SignalType" SG_ 2159247360 ODI_BCM2CntrStck "UNM";
BA_ "SignalLongName" SG_ 2159247360 ODI_BCM2CntrStck "Open Display Interface BCM 2 CenterStack";
BA_ "GenSigSendType" SG_ 2151833600 HtdFrntWSDispReq 10;
BA_ "VNSigAllNodes" SG_ 2151833600 HtdFrntWSDispReq 1;
BA_ "SignalType" SG_ 2151833600 HtdFrntWSDispReq "ENM";
BA_ "SignalLongName" SG_ 2151833600 HtdFrntWSDispReq "Heated Front Windshield Display Request";
BA_ "GenSigSendType" SG_ 2151833600 HtdFrntWSCustRqIhbt 10;
BA_ "VNSigAllNodes" SG_ 2151833600 HtdFrntWSCustRqIhbt 1;
BA_ "SignalType" SG_ 2151833600 HtdFrntWSCustRqIhbt "BLN";
BA_ "SignalLongName" SG_ 2151833600 HtdFrntWSCustRqIhbt "Heated Front Windshield Customer Request Inhibit";
BA_ "GenSigSendOnInit" SG_ 2150236160 UlckKyStrCrptoDt2M 2;
BA_ "GenSigSendType" SG_ 2150236160 UlckKyStrCrptoDt2M 10;
BA_ "VNSigAllNodes" SG_ 2150236160 UlckKyStrCrptoDt2M 1;
BA_ "SignalType" SG_ 2150236160 UlckKyStrCrptoDt2M "ENM";
BA_ "SignalLongName" SG_ 2150236160 UlckKyStrCrptoDt2M "Unlock Key Store Cryptographic Data 2 Mask";
BA_ "GenSigSendOnInit" SG_ 2150236160 UlckKyStrCrptoDt2 2;
BA_ "GenSigSendType" SG_ 2150236160 UlckKyStrCrptoDt2 12;
BA_ "GenSigDeltaValue" SG_ 2150236160 UlckKyStrCrptoDt2 1;
BA_ "VNSigAllNodes" SG_ 2150236160 UlckKyStrCrptoDt2 1;
BA_ "SignalType" SG_ 2150236160 UlckKyStrCrptoDt2 "UNM";
BA_ "SignalLongName" SG_ 2150236160 UlckKyStrCrptoDt2 "Unlock Key Store Cryptographic Data 2";
BA_ "GenSigSendOnInit" SG_ 2150170624 UlckKyStrCrptoDt1M 2;
BA_ "GenSigSendType" SG_ 2150170624 UlckKyStrCrptoDt1M 10;
BA_ "VNSigAllNodes" SG_ 2150170624 UlckKyStrCrptoDt1M 1;
BA_ "SignalType" SG_ 2150170624 UlckKyStrCrptoDt1M "ENM";
BA_ "SignalLongName" SG_ 2150170624 UlckKyStrCrptoDt1M "Unlock Key Store Cryptographic Data 1 Mask";
BA_ "GenSigSendOnInit" SG_ 2150170624 UlckKyStrCrptoDt1 2;
BA_ "GenSigSendType" SG_ 2150170624 UlckKyStrCrptoDt1 12;
BA_ "GenSigDeltaValue" SG_ 2150170624 UlckKyStrCrptoDt1 1;
BA_ "VNSigAllNodes" SG_ 2150170624 UlckKyStrCrptoDt1 1;
BA_ "SignalType" SG_ 2150170624 UlckKyStrCrptoDt1 "UNM";
BA_ "SignalLongName" SG_ 2150170624 UlckKyStrCrptoDt1 "Unlock Key Store Cryptographic Data 1";
BA_ "GenSigSendType" SG_ 2154725376 AuxHtrAtv378 10;
BA_ "VNSigAllNodes" SG_ 2154725376 AuxHtrAtv378 1;
BA_ "SignalType" SG_ 2154725376 AuxHtrAtv378 "BLN";
BA_ "SignalLongName" SG_ 2154725376 AuxHtrAtv378 "Auxiliary Heater Active";
BA_ "GenSigSendType" SG_ 2154725376 AuxHtrRq 10;
BA_ "VNSigAllNodes" SG_ 2154725376 AuxHtrRq 1;
BA_ "SignalType" SG_ 2154725376 AuxHtrRq "ENM";
BA_ "SignalLongName" SG_ 2154725376 AuxHtrRq "Auxiliary Heater Request";
BA_ "GenSigSendOnInit" SG_ 2151931904 FourWhlDrvIdReqExtRng 2;
BA_ "GenSigSendType" SG_ 2151931904 FourWhlDrvIdReqExtRng 10;
BA_ "VNSigAllNodes" SG_ 2151931904 FourWhlDrvIdReqExtRng 1;
BA_ "SignalType" SG_ 2151931904 FourWhlDrvIdReqExtRng "ENM";
BA_ "SignalLongName" SG_ 2151931904 FourWhlDrvIdReqExtRng "Four Wheel Drive Indication Request Extended Range";
BA_ "GenSigSendType" SG_ 2151931904 LnchCtrlTmrVal 12;
BA_ "GenSigDeltaValue" SG_ 2151931904 LnchCtrlTmrVal 1;
BA_ "VNSigAllNodes" SG_ 2151931904 LnchCtrlTmrVal 1;
BA_ "SignalType" SG_ 2151931904 LnchCtrlTmrVal "UNM";
BA_ "SignalLongName" SG_ 2151931904 LnchCtrlTmrVal "Launch Control Timer Value";
BA_ "GenSigSendType" SG_ 2151931904 LnchCtrlBrkPresVal 12;
BA_ "GenSigDeltaValue" SG_ 2151931904 LnchCtrlBrkPresVal 1;
BA_ "VNSigAllNodes" SG_ 2151931904 LnchCtrlBrkPresVal 1;
BA_ "SignalType" SG_ 2151931904 LnchCtrlBrkPresVal "UNM";
BA_ "SignalLongName" SG_ 2151931904 LnchCtrlBrkPresVal "Launch Control Brake Pressure Value";
BA_ "GenSigSendType" SG_ 2151931904 FuelMdTrnstnIndReq 10;
BA_ "VNSigAllNodes" SG_ 2151931904 FuelMdTrnstnIndReq 1;
BA_ "SignalType" SG_ 2151931904 FuelMdTrnstnIndReq "ENM";
BA_ "SignalLongName" SG_ 2151931904 FuelMdTrnstnIndReq "Fuel Mode Transition Indication Request";
BA_ "GenSigSendType" SG_ 2151931904 BiFuelRflGaslinIndReq 10;
BA_ "VNSigAllNodes" SG_ 2151931904 BiFuelRflGaslinIndReq 1;
BA_ "SignalType" SG_ 2151931904 BiFuelRflGaslinIndReq "ENM";
BA_ "SignalLongName" SG_ 2151931904 BiFuelRflGaslinIndReq "Bi Fuel Refill Gasoline Indication Request";
BA_ "GenSigSendType" SG_ 2151931904 AutoShtdwnTmr 12;
BA_ "GenSigDeltaValue" SG_ 2151931904 AutoShtdwnTmr 1;
BA_ "VNSigAllNodes" SG_ 2151931904 AutoShtdwnTmr 1;
BA_ "SignalType" SG_ 2151931904 AutoShtdwnTmr "UNM";
BA_ "SignalLongName" SG_ 2151931904 AutoShtdwnTmr "Automatic Shutdown Timer";
BA_ "GenSigSendType" SG_ 2151931904 AutoShtdwnIO 10;
BA_ "VNSigAllNodes" SG_ 2151931904 AutoShtdwnIO 1;
BA_ "SignalType" SG_ 2151931904 AutoShtdwnIO "BLN";
BA_ "SignalLongName" SG_ 2151931904 AutoShtdwnIO "Automatic Shutdown Indication On";
BA_ "GenSigSendOnInit" SG_ 2151931904 TCSTempDsblReqIO 2;
BA_ "GenSigSendType" SG_ 2151931904 TCSTempDsblReqIO 10;
BA_ "VNSigAllNodes" SG_ 2151931904 TCSTempDsblReqIO 1;
BA_ "SignalType" SG_ 2151931904 TCSTempDsblReqIO "BLN";
BA_ "SignalLongName" SG_ 2151931904 TCSTempDsblReqIO "Traction Control System Temporary Disable Request Indication On";
BA_ "GenSigSendOnInit" SG_ 2151931904 VehStbCmptvMdCstAvl 2;
BA_ "GenSigSendType" SG_ 2151931904 VehStbCmptvMdCstAvl 10;
BA_ "VNSigAllNodes" SG_ 2151931904 VehStbCmptvMdCstAvl 1;
BA_ "SignalType" SG_ 2151931904 VehStbCmptvMdCstAvl "BLN";
BA_ "SignalLongName" SG_ 2151931904 VehStbCmptvMdCstAvl "Vehicle Stability Competitive Mode Customization Available";
BA_ "GenSigSendOnInit" SG_ 2151931904 VehStbEnmntCstAvl 2;
BA_ "GenSigSendType" SG_ 2151931904 VehStbEnmntCstAvl 10;
BA_ "VNSigAllNodes" SG_ 2151931904 VehStbEnmntCstAvl 1;
BA_ "SignalType" SG_ 2151931904 VehStbEnmntCstAvl "BLN";
BA_ "SignalLongName" SG_ 2151931904 VehStbEnmntCstAvl "Vehicle Stability Enhancement Customization Available";
BA_ "GenSigSendOnInit" SG_ 2151931904 TCSysCstAvl 2;
BA_ "GenSigSendType" SG_ 2151931904 TCSysCstAvl 10;
BA_ "VNSigAllNodes" SG_ 2151931904 TCSysCstAvl 1;
BA_ "SignalType" SG_ 2151931904 TCSysCstAvl "BLN";
BA_ "SignalLongName" SG_ 2151931904 TCSysCstAvl "Traction Control System Customization Available";
BA_ "GenSigSendOnInit" SG_ 2151931904 VehStbCmptvMdCurSt 2;
BA_ "GenSigSendType" SG_ 2151931904 VehStbCmptvMdCurSt 10;
BA_ "VNSigAllNodes" SG_ 2151931904 VehStbCmptvMdCurSt 1;
BA_ "SignalType" SG_ 2151931904 VehStbCmptvMdCurSt "ENM";
BA_ "SignalLongName" SG_ 2151931904 VehStbCmptvMdCurSt "Vehicle Stability Competitive Mode Current State";
BA_ "GenSigSendOnInit" SG_ 2151931904 VehStbEnhmntCurSt 2;
BA_ "GenSigSendType" SG_ 2151931904 VehStbEnhmntCurSt 10;
BA_ "VNSigAllNodes" SG_ 2151931904 VehStbEnhmntCurSt 1;
BA_ "SignalType" SG_ 2151931904 VehStbEnhmntCurSt "ENM";
BA_ "SignalLongName" SG_ 2151931904 VehStbEnhmntCurSt "Vehicle Stability Enhancement Current State";
BA_ "GenSigSendOnInit" SG_ 2151931904 TCSysCurSt 2;
BA_ "GenSigSendType" SG_ 2151931904 TCSysCurSt 10;
BA_ "VNSigAllNodes" SG_ 2151931904 TCSysCurSt 1;
BA_ "SignalType" SG_ 2151931904 TCSysCurSt "ENM";
BA_ "SignalLongName" SG_ 2151931904 TCSysCurSt "Traction Control System Current State";
BA_ "GenSigSendOnInit" SG_ 2151931904 TracAndStbScrnCnfg 2;
BA_ "GenSigSendType" SG_ 2151931904 TracAndStbScrnCnfg 10;
BA_ "VNSigAllNodes" SG_ 2151931904 TracAndStbScrnCnfg 1;
BA_ "SignalType" SG_ 2151931904 TracAndStbScrnCnfg "ENM";
BA_ "SignalLongName" SG_ 2151931904 TracAndStbScrnCnfg "Traction And Stability Screen Configuration";
BA_ "GenSigSendType" SG_ 2151931904 ElctShfPriLtdPerfMdIO 10;
BA_ "VNSigAllNodes" SG_ 2151931904 ElctShfPriLtdPerfMdIO 1;
BA_ "SignalType" SG_ 2151931904 ElctShfPriLtdPerfMdIO "BLN";
BA_ "SignalLongName" SG_ 2151931904 ElctShfPriLtdPerfMdIO "Electronic Shift Primary Limited Performance Mode Indication On";
BA_ "GenSigSendType" SG_ 2151931904 LnchCtrlWhlSlpStat 10;
BA_ "VNSigAllNodes" SG_ 2151931904 LnchCtrlWhlSlpStat 1;
BA_ "SignalType" SG_ 2151931904 LnchCtrlWhlSlpStat "ENM";
BA_ "SignalLongName" SG_ 2151931904 LnchCtrlWhlSlpStat "Launch Control Wheel Slip Status";
BA_ "GenSigSendType" SG_ 2151931904 LnchCtrlMdStat 10;
BA_ "VNSigAllNodes" SG_ 2151931904 LnchCtrlMdStat 1;
BA_ "SignalType" SG_ 2151931904 LnchCtrlMdStat "ENM";
BA_ "SignalLongName" SG_ 2151931904 LnchCtrlMdStat "Launch Control Mode Status";
BA_ "GenSigSendType" SG_ 2151931904 LnchCtrlEngRPMStat 10;
BA_ "VNSigAllNodes" SG_ 2151931904 LnchCtrlEngRPMStat 1;
BA_ "SignalType" SG_ 2151931904 LnchCtrlEngRPMStat "ENM";
BA_ "SignalLongName" SG_ 2151931904 LnchCtrlEngRPMStat "Launch Control Engine RPM Status";
BA_ "GenSigSendType" SG_ 2151931904 RegVltCtlEngyRcvryAct 10;
BA_ "VNSigAllNodes" SG_ 2151931904 RegVltCtlEngyRcvryAct 1;
BA_ "SignalType" SG_ 2151931904 RegVltCtlEngyRcvryAct "BLN";
BA_ "SignalLongName" SG_ 2151931904 RegVltCtlEngyRcvryAct "Regulated Voltage Control Energy Recovery Active";
BA_ "GenSigSendType" SG_ 2151931904 VehSpdCntlSystmType 10;
BA_ "VNSigAllNodes" SG_ 2151931904 VehSpdCntlSystmType 1;
BA_ "SignalType" SG_ 2151931904 VehSpdCntlSystmType "ENM";
BA_ "SignalLongName" SG_ 2151931904 VehSpdCntlSystmType "Vehicle Speed Control System Type";
BA_ "GenSigSendOnInit" SG_ 2151931904 ACCSysSltdMdDispIO 2;
BA_ "GenSigSendType" SG_ 2151931904 ACCSysSltdMdDispIO 10;
BA_ "VNSigAllNodes" SG_ 2151931904 ACCSysSltdMdDispIO 1;
BA_ "SignalType" SG_ 2151931904 ACCSysSltdMdDispIO "BLN";
BA_ "SignalLongName" SG_ 2151931904 ACCSysSltdMdDispIO "Adaptive Cruise Control System Selected Mode Display Indication On";
BA_ "GenSigSendOnInit" SG_ 2151931904 ACCSysSltdMd 2;
BA_ "GenSigSendType" SG_ 2151931904 ACCSysSltdMd 10;
BA_ "VNSigAllNodes" SG_ 2151931904 ACCSysSltdMd 1;
BA_ "SignalType" SG_ 2151931904 ACCSysSltdMd "ENM";
BA_ "SignalLongName" SG_ 2151931904 ACCSysSltdMd "Adaptive Cruise Control System Selected Mode";
BA_ "GenSigSendType" SG_ 2151931904 PTExPrtclFltWrng3IO 10;
BA_ "VNSigAllNodes" SG_ 2151931904 PTExPrtclFltWrng3IO 1;
BA_ "SignalType" SG_ 2151931904 PTExPrtclFltWrng3IO "BLN";
BA_ "SignalLongName" SG_ 2151931904 PTExPrtclFltWrng3IO "Powertrain Exhaust Particle Filter Warning 3 Indication On";
BA_ "GenSigSendType" SG_ 2151931904 PTExPartFltManRegStat 10;
BA_ "VNSigAllNodes" SG_ 2151931904 PTExPartFltManRegStat 1;
BA_ "SignalType" SG_ 2151931904 PTExPartFltManRegStat "ENM";
BA_ "SignalLongName" SG_ 2151931904 PTExPartFltManRegStat "Powertrain Exhaust Particle Filter Manual Regeneration Status";
BA_ "GenSigSendType" SG_ 2151931904 AWDRecmndIO 10;
BA_ "VNSigAllNodes" SG_ 2151931904 AWDRecmndIO 1;
BA_ "SignalType" SG_ 2151931904 AWDRecmndIO "BLN";
BA_ "SignalLongName" SG_ 2151931904 AWDRecmndIO "All Wheel Drive Recommended Indication On";
BA_ "VNSigAllNodes" SG_ 2151915520 ESPTrnVehOffFrPrkIO 1;
BA_ "SignalType" SG_ 2151915520 ESPTrnVehOffFrPrkIO "BLN";
BA_ "SignalLongName" SG_ 2151915520 ESPTrnVehOffFrPrkIO "Electronic Shift Primary Turn Vehicle Off For Park Indication On";
BA_ "VNSigAllNodes" SG_ 2151915520 ESPTrnsCtlrMalfIO 1;
BA_ "SignalType" SG_ 2151915520 ESPTrnsCtlrMalfIO "BLN";
BA_ "SignalLongName" SG_ 2151915520 ESPTrnsCtlrMalfIO "Electronic Shift Primary Transmission Controller Malfunction Indication On";
BA_ "VNSigAllNodes" SG_ 2151915520 ESPShfToDrvTryAgnIO 1;
BA_ "SignalType" SG_ 2151915520 ESPShfToDrvTryAgnIO "BLN";
BA_ "SignalLongName" SG_ 2151915520 ESPShfToDrvTryAgnIO "Electronic Shift Primary Shift To Drive Try Again Indication On";
BA_ "VNSigAllNodes" SG_ 2151915520 ElcShfPriTwoGrsSlInRq 1;
BA_ "SignalType" SG_ 2151915520 ElcShfPriTwoGrsSlInRq "ENM";
BA_ "SignalLongName" SG_ 2151915520 ElcShfPriTwoGrsSlInRq "Electronic Shift Primary Two Gears Selected Indication Request";
BA_ "VNSigAllNodes" SG_ 2151915520 DrvEffInd 1;
BA_ "SignalType" SG_ 2151915520 DrvEffInd "SNM";
BA_ "SignalLongName" SG_ 2151915520 DrvEffInd "Drive Efficiency Indication";
BA_ "VNSigAllNodes" SG_ 2151915520 EngIntkArBstPrExtRngV 1;
BA_ "SignalType" SG_ 2151915520 EngIntkArBstPrExtRngV "ENM";
BA_ "SignalLongName" SG_ 2151915520 EngIntkArBstPrExtRngV "Engine Intake Air Boost Pressure Extended Range Validity";
BA_ "VNSigAllNodes" SG_ 2151915520 EngIntkArBstPrExtRng 1;
BA_ "SignalType" SG_ 2151915520 EngIntkArBstPrExtRng "UNM";
BA_ "SignalLongName" SG_ 2151915520 EngIntkArBstPrExtRng "Engine Intake Air Boost Pressure Extended Range";
BA_ "VNSigAllNodes" SG_ 2151915520 ElecShfRngDispRCExtd 1;
BA_ "SignalType" SG_ 2151915520 ElecShfRngDispRCExtd "UNM";
BA_ "SignalLongName" SG_ 2151915520 ElecShfRngDispRCExtd "Electronic Shift Range Display Rolling Count Extended";
BA_ "VNSigAllNodes" SG_ 2151915520 ElecShfRngDisp 1;
BA_ "SignalType" SG_ 2151915520 ElecShfRngDisp "ENM";
BA_ "SignalLongName" SG_ 2151915520 ElecShfRngDisp "Electronic Shift Range Display";
BA_ "VNSigAllNodes" SG_ 2151915520 ESPTransMalfIO 1;
BA_ "SignalType" SG_ 2151915520 ESPTransMalfIO "BLN";
BA_ "SignalLongName" SG_ 2151915520 ESPTransMalfIO "Electronic Shift Primary Transmission Malfunction Indication On";
BA_ "VNSigAllNodes" SG_ 2151915520 ESPRngInvldReqIO 1;
BA_ "SignalType" SG_ 2151915520 ESPRngInvldReqIO "BLN";
BA_ "SignalLongName" SG_ 2151915520 ESPRngInvldReqIO "Electronic Shift Primary Range Invalid Request Indication On";
BA_ "VNSigAllNodes" SG_ 2151915520 ESPPrkInvldReqIO 1;
BA_ "SignalType" SG_ 2151915520 ESPPrkInvldReqIO "BLN";
BA_ "SignalLongName" SG_ 2151915520 ESPPrkInvldReqIO "Electronic Shift Primary Park Invalid Request Indication On";
BA_ "VNSigAllNodes" SG_ 2151915520 ESPHldShfLvrToEngRgIO 1;
BA_ "SignalType" SG_ 2151915520 ESPHldShfLvrToEngRgIO "BLN";
BA_ "SignalLongName" SG_ 2151915520 ESPHldShfLvrToEngRgIO "Electronic Shift Primary Hold Shift Lever to Engage Range Indication On";
BA_ "VNSigAllNodes" SG_ 2151915520 ESPDrvrPrkIlkSftAtdIO 1;
BA_ "SignalType" SG_ 2151915520 ESPDrvrPrkIlkSftAtdIO "BLN";
BA_ "SignalLongName" SG_ 2151915520 ESPDrvrPrkIlkSftAtdIO "Electronic Shift Primary Driver Park Interlock Shift Attempted Indication On";
BA_ "VNSigAllNodes" SG_ 2151915520 ESPDrvrIlkShfAtdIO 1;
BA_ "SignalType" SG_ 2151915520 ESPDrvrIlkShfAtdIO "BLN";
BA_ "SignalLongName" SG_ 2151915520 ESPDrvrIlkShfAtdIO "Electronic Shift Primary Driver Interlock Shift Attempted Indication On";
BA_ "VNSigAllNodes" SG_ 2151915520 AHAct 1;
BA_ "SignalType" SG_ 2151915520 AHAct "BLN";
BA_ "SignalLongName" SG_ 2151915520 AHAct "Auto Hold Active";
BA_ "VNSigAllNodes" SG_ 2151915520 AHEnbld 1;
BA_ "SignalType" SG_ 2151915520 AHEnbld "BLN";
BA_ "SignalLongName" SG_ 2151915520 AHEnbld "Auto Hold Enabled";
BA_ "VNSigAllNodes" SG_ 2151915520 ShfToPrkBfExtngIO 1;
BA_ "SignalType" SG_ 2151915520 ShfToPrkBfExtngIO "BLN";
BA_ "SignalLongName" SG_ 2151915520 ShfToPrkBfExtngIO "Shift To Park Before Exiting Indication On";
BA_ "VNSigAllNodes" SG_ 2151915520 AHServcIO 1;
BA_ "SignalType" SG_ 2151915520 AHServcIO "BLN";
BA_ "SignalLongName" SG_ 2151915520 AHServcIO "Auto Hold Service Indication On";
BA_ "VNSigAllNodes" SG_ 2151915520 AHAppBrkPedlIO 1;
BA_ "SignalType" SG_ 2151915520 AHAppBrkPedlIO "BLN";
BA_ "SignalLongName" SG_ 2151915520 AHAppBrkPedlIO "Auto Hold Apply Brake Pedal Indication On";
BA_ "VNSigAllNodes" SG_ 2151915520 AHDisbldStbltIO 1;
BA_ "SignalType" SG_ 2151915520 AHDisbldStbltIO "BLN";
BA_ "SignalLongName" SG_ 2151915520 AHDisbldStbltIO "Auto Hold Disabled Seatbelt Indication On";
BA_ "VNSigAllNodes" SG_ 2151915520 AHDisbldDrOpnIO 1;
BA_ "SignalType" SG_ 2151915520 AHDisbldDrOpnIO "BLN";
BA_ "SignalLongName" SG_ 2151915520 AHDisbldDrOpnIO "Auto Hold Disabled Door Open Indication On";
BA_ "VNSigAllNodes" SG_ 2151915520 ElcTransRngSlctVDA 1;
BA_ "SignalType" SG_ 2151915520 ElcTransRngSlctVDA "ENM";
BA_ "SignalLongName" SG_ 2151915520 ElcTransRngSlctVDA "Electronic Transmission Range Select Virtual Device Availability";
BA_ "GenSigStartValue" SG_ 2151915520 ElcTransRngSlctVDA 1;
BA_ "VNSigRemoteDiagnostics" SG_ 2153947136 RmtRflshMdAct 1;
BA_ "GenSigSendType" SG_ 2153947136 RmtRflshMdAct 10;
BA_ "SignalType" SG_ 2153947136 RmtRflshMdAct "BLN";
BA_ "SignalLongName" SG_ 2153947136 RmtRflshMdAct "Remote Reflash Mode Active";
BA_ "GenSigSendOnInit" SG_ 2152112128 PMVSS_Disps 2;
BA_ "GenSigSendType" SG_ 2152112128 PMVSS_Disps 10;
BA_ "VNSigAllNodes" SG_ 2152112128 PMVSS_Disps 1;
BA_ "SignalType" SG_ 2152112128 PMVSS_Disps "ENM";
BA_ "PacketOrder" SG_ 2152112128 PMVSS_Disps 11;
BA_ "SignalLongName" SG_ 2152112128 PMVSS_Disps "Performance Mode Visualization Screen Status : Displays";
BA_ "GenSigSendOnInit" SG_ 2152112128 PMVSS_Exhst 2;
BA_ "GenSigSendType" SG_ 2152112128 PMVSS_Exhst 10;
BA_ "VNSigAllNodes" SG_ 2152112128 PMVSS_Exhst 1;
BA_ "SignalType" SG_ 2152112128 PMVSS_Exhst "ENM";
BA_ "PacketOrder" SG_ 2152112128 PMVSS_Exhst 10;
BA_ "SignalLongName" SG_ 2152112128 PMVSS_Exhst "Performance Mode Visualization Screen Status : Exhaust";
BA_ "GenSigSendOnInit" SG_ 2152112128 PMVSS_PsngrSeat 2;
BA_ "GenSigSendType" SG_ 2152112128 PMVSS_PsngrSeat 10;
BA_ "VNSigAllNodes" SG_ 2152112128 PMVSS_PsngrSeat 1;
BA_ "SignalType" SG_ 2152112128 PMVSS_PsngrSeat "ENM";
BA_ "PacketOrder" SG_ 2152112128 PMVSS_PsngrSeat 9;
BA_ "SignalLongName" SG_ 2152112128 PMVSS_PsngrSeat "Performance Mode Visualization Screen Status : Passenger Seat";
BA_ "GenSigSendOnInit" SG_ 2152112128 PMVSS_DrvrSeat 2;
BA_ "GenSigSendType" SG_ 2152112128 PMVSS_DrvrSeat 10;
BA_ "VNSigAllNodes" SG_ 2152112128 PMVSS_DrvrSeat 1;
BA_ "SignalType" SG_ 2152112128 PMVSS_DrvrSeat "ENM";
BA_ "PacketOrder" SG_ 2152112128 PMVSS_DrvrSeat 8;
BA_ "SignalLongName" SG_ 2152112128 PMVSS_DrvrSeat "Performance Mode Visualization Screen Status : Driver Seat";
BA_ "GenSigSendOnInit" SG_ 2152112128 PMVSS_AdptCrsCnt 2;
BA_ "GenSigSendType" SG_ 2152112128 PMVSS_AdptCrsCnt 10;
BA_ "VNSigAllNodes" SG_ 2152112128 PMVSS_AdptCrsCnt 1;
BA_ "SignalType" SG_ 2152112128 PMVSS_AdptCrsCnt "ENM";
BA_ "PacketOrder" SG_ 2152112128 PMVSS_AdptCrsCnt 7;
BA_ "SignalLongName" SG_ 2152112128 PMVSS_AdptCrsCnt "Performance Mode Visualization Screen Status : Adaptive Cruise Control";
BA_ "GenSigSendOnInit" SG_ 2152112128 PMVSS_Drvln 2;
BA_ "GenSigSendType" SG_ 2152112128 PMVSS_Drvln 10;
BA_ "VNSigAllNodes" SG_ 2152112128 PMVSS_Drvln 1;
BA_ "SignalType" SG_ 2152112128 PMVSS_Drvln "ENM";
BA_ "PacketOrder" SG_ 2152112128 PMVSS_Drvln 6;
BA_ "SignalLongName" SG_ 2152112128 PMVSS_Drvln "Performance Mode Visualization Screen Status : Driveline";
BA_ "GenSigSendOnInit" SG_ 2152112128 PMVSS_Susp 2;
BA_ "GenSigSendType" SG_ 2152112128 PMVSS_Susp 10;
BA_ "VNSigAllNodes" SG_ 2152112128 PMVSS_Susp 1;
BA_ "SignalType" SG_ 2152112128 PMVSS_Susp "ENM";
BA_ "PacketOrder" SG_ 2152112128 PMVSS_Susp 5;
BA_ "SignalLongName" SG_ 2152112128 PMVSS_Susp "Performance Mode Visualization Screen Status : Suspension";
BA_ "GenSigSendOnInit" SG_ 2152112128 PMVSS_Strng 2;
BA_ "GenSigSendType" SG_ 2152112128 PMVSS_Strng 10;
BA_ "VNSigAllNodes" SG_ 2152112128 PMVSS_Strng 1;
BA_ "SignalType" SG_ 2152112128 PMVSS_Strng "ENM";
BA_ "PacketOrder" SG_ 2152112128 PMVSS_Strng 4;
BA_ "SignalLongName" SG_ 2152112128 PMVSS_Strng "Performance Mode Visualization Screen Status : Steering";
BA_ "GenSigSendOnInit" SG_ 2152112128 PMVSS_Trans 2;
BA_ "GenSigSendType" SG_ 2152112128 PMVSS_Trans 10;
BA_ "VNSigAllNodes" SG_ 2152112128 PMVSS_Trans 1;
BA_ "SignalType" SG_ 2152112128 PMVSS_Trans "ENM";
BA_ "PacketOrder" SG_ 2152112128 PMVSS_Trans 3;
BA_ "SignalLongName" SG_ 2152112128 PMVSS_Trans "Performance Mode Visualization Screen Status : Transmission";
BA_ "GenSigSendOnInit" SG_ 2152112128 PMVSS_Eng 2;
BA_ "GenSigSendType" SG_ 2152112128 PMVSS_Eng 10;
BA_ "VNSigAllNodes" SG_ 2152112128 PMVSS_Eng 1;
BA_ "SignalType" SG_ 2152112128 PMVSS_Eng "ENM";
BA_ "PacketOrder" SG_ 2152112128 PMVSS_Eng 2;
BA_ "SignalLongName" SG_ 2152112128 PMVSS_Eng "Performance Mode Visualization Screen Status : Engine";
BA_ "GenSigSendOnInit" SG_ 2152112128 PMVSS_Snd 2;
BA_ "GenSigSendType" SG_ 2152112128 PMVSS_Snd 10;
BA_ "VNSigAllNodes" SG_ 2152112128 PMVSS_Snd 1;
BA_ "SignalType" SG_ 2152112128 PMVSS_Snd "ENM";
BA_ "PacketOrder" SG_ 2152112128 PMVSS_Snd 1;
BA_ "SignalLongName" SG_ 2152112128 PMVSS_Snd "Performance Mode Visualization Screen Status : Sound";
BA_ "GenSigSendOnInit" SG_ 2152112128 PerfMdMainMenuType 2;
BA_ "GenSigSendType" SG_ 2152112128 PerfMdMainMenuType 10;
BA_ "VNSigAllNodes" SG_ 2152112128 PerfMdMainMenuType 1;
BA_ "SignalType" SG_ 2152112128 PerfMdMainMenuType "ENM";
BA_ "SignalLongName" SG_ 2152112128 PerfMdMainMenuType "Performance Mode Main Menu Type";
BA_ "GenSigSendOnInit" SG_ 2153857024 TnDrvTrCtrlEvntsRpt 2;
BA_ "GenSigSendType" SG_ 2153857024 TnDrvTrCtrlEvntsRpt 12;
BA_ "GenSigDeltaValue" SG_ 2153857024 TnDrvTrCtrlEvntsRpt 1;
BA_ "VNSigAllNodes" SG_ 2153857024 TnDrvTrCtrlEvntsRpt 1;
BA_ "SignalType" SG_ 2153857024 TnDrvTrCtrlEvntsRpt "UNM";
BA_ "SignalLongName" SG_ 2153857024 TnDrvTrCtrlEvntsRpt "Teen Driver Traction Control Events Report";
BA_ "GenSigSendOnInit" SG_ 2153857024 TnDrvDrowDrvAlrtsRpt 2;
BA_ "GenSigSendType" SG_ 2153857024 TnDrvDrowDrvAlrtsRpt 12;
BA_ "GenSigDeltaValue" SG_ 2153857024 TnDrvDrowDrvAlrtsRpt 1;
BA_ "VNSigAllNodes" SG_ 2153857024 TnDrvDrowDrvAlrtsRpt 1;
BA_ "SignalType" SG_ 2153857024 TnDrvDrowDrvAlrtsRpt "UNM";
BA_ "SignalLongName" SG_ 2153857024 TnDrvDrowDrvAlrtsRpt "Teen Driver Drowsy Driver Alerts Report";
BA_ "GenSigSendOnInit" SG_ 2153857024 TDRCADD_WOTEvnts 2;
BA_ "GenSigSendType" SG_ 2153857024 TDRCADD_WOTEvnts 10;
BA_ "VNSigAllNodes" SG_ 2153857024 TDRCADD_WOTEvnts 1;
BA_ "SignalType" SG_ 2153857024 TDRCADD_WOTEvnts "BLN";
BA_ "PacketOrder" SG_ 2153857024 TDRCADD_WOTEvnts 12;
BA_ "SignalLongName" SG_ 2153857024 TDRCADD_WOTEvnts "Teen Driver Report Card Available Display Data : Wide Open Throttle Events";
BA_ "GenSigSendOnInit" SG_ 2153857024 TDRCADD_LDWEvnts 2;
BA_ "GenSigSendType" SG_ 2153857024 TDRCADD_LDWEvnts 10;
BA_ "VNSigAllNodes" SG_ 2153857024 TDRCADD_LDWEvnts 1;
BA_ "SignalType" SG_ 2153857024 TDRCADD_LDWEvnts "BLN";
BA_ "PacketOrder" SG_ 2153857024 TDRCADD_LDWEvnts 13;
BA_ "SignalLongName" SG_ 2153857024 TDRCADD_LDWEvnts "Teen Driver Report Card Available Display Data : Lane Departure Warning Events";
BA_ "GenSigSendOnInit" SG_ 2153857024 TDRCADD_FCMBrEvts 2;
BA_ "GenSigSendType" SG_ 2153857024 TDRCADD_FCMBrEvts 10;
BA_ "VNSigAllNodes" SG_ 2153857024 TDRCADD_FCMBrEvts 1;
BA_ "SignalType" SG_ 2153857024 TDRCADD_FCMBrEvts "BLN";
BA_ "PacketOrder" SG_ 2153857024 TDRCADD_FCMBrEvts 10;
BA_ "SignalLongName" SG_ 2153857024 TDRCADD_FCMBrEvts "Teen Driver Report Card Available Display Data : Forward Collision Mitigation Braking Events";
BA_ "GenSigSendOnInit" SG_ 2153857024 TDRCADD_DrwDrvAlrt 2;
BA_ "GenSigSendType" SG_ 2153857024 TDRCADD_DrwDrvAlrt 10;
BA_ "VNSigAllNodes" SG_ 2153857024 TDRCADD_DrwDrvAlrt 1;
BA_ "SignalType" SG_ 2153857024 TDRCADD_DrwDrvAlrt "BLN";
BA_ "PacketOrder" SG_ 2153857024 TDRCADD_DrwDrvAlrt 11;
BA_ "SignalLongName" SG_ 2153857024 TDRCADD_DrwDrvAlrt "Teen Driver Report Card Available Display Data : Drowsy Driver Alerts";
BA_ "GenSigSendOnInit" SG_ 2153857024 TDRCADD_RCMBrEvts 2;
BA_ "GenSigSendType" SG_ 2153857024 TDRCADD_RCMBrEvts 10;
BA_ "VNSigAllNodes" SG_ 2153857024 TDRCADD_RCMBrEvts 1;
BA_ "SignalType" SG_ 2153857024 TDRCADD_RCMBrEvts "BLN";
BA_ "PacketOrder" SG_ 2153857024 TDRCADD_RCMBrEvts 9;
BA_ "SignalLongName" SG_ 2153857024 TDRCADD_RCMBrEvts "Teen Driver Report Card Available Display Data : Reverse Collision Mitigation Braking Events";
BA_ "GenSigSendOnInit" SG_ 2153857024 TDRCADD_FCImntAlrts 2;
BA_ "GenSigSendType" SG_ 2153857024 TDRCADD_FCImntAlrts 10;
BA_ "VNSigAllNodes" SG_ 2153857024 TDRCADD_FCImntAlrts 1;
BA_ "SignalType" SG_ 2153857024 TDRCADD_FCImntAlrts "BLN";
BA_ "PacketOrder" SG_ 2153857024 TDRCADD_FCImntAlrts 8;
BA_ "SignalLongName" SG_ 2153857024 TDRCADD_FCImntAlrts "Teen Driver Report Card Available Display Data : Forward Collision Imminent Alerts";
BA_ "GenSigSendOnInit" SG_ 2153857024 TDRCADD_FCHdwyAlrt 2;
BA_ "GenSigSendType" SG_ 2153857024 TDRCADD_FCHdwyAlrt 10;
BA_ "VNSigAllNodes" SG_ 2153857024 TDRCADD_FCHdwyAlrt 1;
BA_ "SignalType" SG_ 2153857024 TDRCADD_FCHdwyAlrt "BLN";
BA_ "PacketOrder" SG_ 2153857024 TDRCADD_FCHdwyAlrt 7;
BA_ "SignalLongName" SG_ 2153857024 TDRCADD_FCHdwyAlrt "Teen Driver Report Card Available Display Data : Forward Collision Headway Alerts";
BA_ "GenSigSendOnInit" SG_ 2153857024 TDRCADD_StCtrlEvnts 2;
BA_ "GenSigSendType" SG_ 2153857024 TDRCADD_StCtrlEvnts 10;
BA_ "VNSigAllNodes" SG_ 2153857024 TDRCADD_StCtrlEvnts 1;
BA_ "SignalType" SG_ 2153857024 TDRCADD_StCtrlEvnts "BLN";
BA_ "PacketOrder" SG_ 2153857024 TDRCADD_StCtrlEvnts 5;
BA_ "SignalLongName" SG_ 2153857024 TDRCADD_StCtrlEvnts "Teen Driver Report Card Available Display Data : Stability Control Events";
BA_ "GenSigSendOnInit" SG_ 2153857024 TDRCADD_ABSAtvEvt 2;
BA_ "GenSigSendType" SG_ 2153857024 TDRCADD_ABSAtvEvt 10;
BA_ "VNSigAllNodes" SG_ 2153857024 TDRCADD_ABSAtvEvt 1;
BA_ "SignalType" SG_ 2153857024 TDRCADD_ABSAtvEvt "BLN";
BA_ "PacketOrder" SG_ 2153857024 TDRCADD_ABSAtvEvt 6;
BA_ "SignalLongName" SG_ 2153857024 TDRCADD_ABSAtvEvt "Teen Driver Report Card Available Display Data : Antilock Braking System Active Events";
BA_ "GenSigSendOnInit" SG_ 2153857024 TDRCADD_TrCtrlEvnts 2;
BA_ "GenSigSendType" SG_ 2153857024 TDRCADD_TrCtrlEvnts 10;
BA_ "VNSigAllNodes" SG_ 2153857024 TDRCADD_TrCtrlEvnts 1;
BA_ "SignalType" SG_ 2153857024 TDRCADD_TrCtrlEvnts "BLN";
BA_ "PacketOrder" SG_ 2153857024 TDRCADD_TrCtrlEvnts 4;
BA_ "SignalLongName" SG_ 2153857024 TDRCADD_TrCtrlEvnts "Teen Driver Report Card Available Display Data : Traction Control Events";
BA_ "GenSigSendOnInit" SG_ 2153857024 TDRCADD_OvSpdEvnt 2;
BA_ "GenSigSendType" SG_ 2153857024 TDRCADD_OvSpdEvnt 10;
BA_ "VNSigAllNodes" SG_ 2153857024 TDRCADD_OvSpdEvnt 1;
BA_ "SignalType" SG_ 2153857024 TDRCADD_OvSpdEvnt "BLN";
BA_ "PacketOrder" SG_ 2153857024 TDRCADD_OvSpdEvnt 3;
BA_ "SignalLongName" SG_ 2153857024 TDRCADD_OvSpdEvnt "Teen Driver Report Card Available Display Data : Overspeed Events";
BA_ "GenSigSendOnInit" SG_ 2153857024 TDRCADD_DistDrvn 2;
BA_ "GenSigSendType" SG_ 2153857024 TDRCADD_DistDrvn 10;
BA_ "VNSigAllNodes" SG_ 2153857024 TDRCADD_DistDrvn 1;
BA_ "SignalType" SG_ 2153857024 TDRCADD_DistDrvn "BLN";
BA_ "PacketOrder" SG_ 2153857024 TDRCADD_DistDrvn 2;
BA_ "SignalLongName" SG_ 2153857024 TDRCADD_DistDrvn "Teen Driver Report Card Available Display Data : Distance Driven";
BA_ "GenSigSendOnInit" SG_ 2153857024 TDRCADD_MaxSpd 2;
BA_ "GenSigSendType" SG_ 2153857024 TDRCADD_MaxSpd 10;
BA_ "VNSigAllNodes" SG_ 2153857024 TDRCADD_MaxSpd 1;
BA_ "SignalType" SG_ 2153857024 TDRCADD_MaxSpd "BLN";
BA_ "PacketOrder" SG_ 2153857024 TDRCADD_MaxSpd 1;
BA_ "SignalLongName" SG_ 2153857024 TDRCADD_MaxSpd "Teen Driver Report Card Available Display Data : Maximum Speed";
BA_ "GenSigSendOnInit" SG_ 2153857024 TnDrvStblCtrlEvntsRpt 2;
BA_ "GenSigSendType" SG_ 2153857024 TnDrvStblCtrlEvntsRpt 12;
BA_ "GenSigDeltaValue" SG_ 2153857024 TnDrvStblCtrlEvntsRpt 1;
BA_ "VNSigAllNodes" SG_ 2153857024 TnDrvStblCtrlEvntsRpt 1;
BA_ "SignalType" SG_ 2153857024 TnDrvStblCtrlEvntsRpt "UNM";
BA_ "SignalLongName" SG_ 2153857024 TnDrvStblCtrlEvntsRpt "Teen Driver Stability Control Events Report";
BA_ "GenSigSendOnInit" SG_ 2153857024 TnDrvABSAtvEvntsRpt 2;
BA_ "GenSigSendType" SG_ 2153857024 TnDrvABSAtvEvntsRpt 12;
BA_ "GenSigDeltaValue" SG_ 2153857024 TnDrvABSAtvEvntsRpt 1;
BA_ "VNSigAllNodes" SG_ 2153857024 TnDrvABSAtvEvntsRpt 1;
BA_ "SignalType" SG_ 2153857024 TnDrvABSAtvEvntsRpt "UNM";
BA_ "SignalLongName" SG_ 2153857024 TnDrvABSAtvEvntsRpt "Teen Driver Antilock Brake System Active Events Report";
BA_ "GenSigSendOnInit" SG_ 2153857024 TeenDrvWOTEvntsRpt 2;
BA_ "GenSigSendType" SG_ 2153857024 TeenDrvWOTEvntsRpt 12;
BA_ "GenSigDeltaValue" SG_ 2153857024 TeenDrvWOTEvntsRpt 1;
BA_ "VNSigAllNodes" SG_ 2153857024 TeenDrvWOTEvntsRpt 1;
BA_ "SignalType" SG_ 2153857024 TeenDrvWOTEvntsRpt "UNM";
BA_ "SignalLongName" SG_ 2153857024 TeenDrvWOTEvntsRpt "Teen Driver Wide Open Throttle Events Report";
BA_ "GenSigSendType" SG_ 2153840640 TnDrvDRLOffUnbIO 10;
BA_ "VNSigAllNodes" SG_ 2153840640 TnDrvDRLOffUnbIO 1;
BA_ "SignalType" SG_ 2153840640 TnDrvDRLOffUnbIO "BLN";
BA_ "SignalLongName" SG_ 2153840640 TnDrvDRLOffUnbIO "Teen Driver Daytime Running Lights Off Unavailable Indication On";
BA_ "GenSigSendType" SG_ 2153840640 TnDrvALCOffUnbIO 10;
BA_ "VNSigAllNodes" SG_ 2153840640 TnDrvALCOffUnbIO 1;
BA_ "SignalType" SG_ 2153840640 TnDrvALCOffUnbIO "BLN";
BA_ "SignalLongName" SG_ 2153840640 TnDrvALCOffUnbIO "Teen Driver Automatic Light Control Off Unavailable Indication On";
BA_ "GenSigSendOnInit" SG_ 2153840640 TeenDrvLDWEvntsRpt 2;
BA_ "GenSigSendType" SG_ 2153840640 TeenDrvLDWEvntsRpt 12;
BA_ "GenSigDeltaValue" SG_ 2153840640 TeenDrvLDWEvntsRpt 1;
BA_ "VNSigAllNodes" SG_ 2153840640 TeenDrvLDWEvntsRpt 1;
BA_ "SignalType" SG_ 2153840640 TeenDrvLDWEvntsRpt "UNM";
BA_ "SignalLongName" SG_ 2153840640 TeenDrvLDWEvntsRpt "Teen Driver Lane Departure Warning Events Report";
BA_ "GenSigSendOnInit" SG_ 2153840640 TeenDrvMaxSpdRpt 2;
BA_ "GenSigSendType" SG_ 2153840640 TeenDrvMaxSpdRpt 12;
BA_ "GenSigDeltaValue" SG_ 2153840640 TeenDrvMaxSpdRpt 1;
BA_ "VNSigAllNodes" SG_ 2153840640 TeenDrvMaxSpdRpt 1;
BA_ "SignalType" SG_ 2153840640 TeenDrvMaxSpdRpt "UNM";
BA_ "SignalLongName" SG_ 2153840640 TeenDrvMaxSpdRpt "Teen Driver Maximum Speed Report";
BA_ "GenSigSendOnInit" SG_ 2153840640 TDFwdClnImntAlrtsRpt 2;
BA_ "GenSigSendType" SG_ 2153840640 TDFwdClnImntAlrtsRpt 12;
BA_ "GenSigDeltaValue" SG_ 2153840640 TDFwdClnImntAlrtsRpt 1;
BA_ "VNSigAllNodes" SG_ 2153840640 TDFwdClnImntAlrtsRpt 1;
BA_ "SignalType" SG_ 2153840640 TDFwdClnImntAlrtsRpt "UNM";
BA_ "SignalLongName" SG_ 2153840640 TDFwdClnImntAlrtsRpt "Teen Driver Forward Collision Imminent Alerts Report";
BA_ "GenSigSendOnInit" SG_ 2153840640 TDRevClnMtgnBrEvRpt 2;
BA_ "GenSigSendType" SG_ 2153840640 TDRevClnMtgnBrEvRpt 12;
BA_ "GenSigDeltaValue" SG_ 2153840640 TDRevClnMtgnBrEvRpt 1;
BA_ "VNSigAllNodes" SG_ 2153840640 TDRevClnMtgnBrEvRpt 1;
BA_ "SignalType" SG_ 2153840640 TDRevClnMtgnBrEvRpt "UNM";
BA_ "SignalLongName" SG_ 2153840640 TDRevClnMtgnBrEvRpt "Teen Driver Reverse Collision Mitigation Braking Events Report";
BA_ "GenSigSendOnInit" SG_ 2153840640 TDFwdClnMtgnBrEvRpt 2;
BA_ "GenSigSendType" SG_ 2153840640 TDFwdClnMtgnBrEvRpt 12;
BA_ "GenSigDeltaValue" SG_ 2153840640 TDFwdClnMtgnBrEvRpt 1;
BA_ "VNSigAllNodes" SG_ 2153840640 TDFwdClnMtgnBrEvRpt 1;
BA_ "SignalType" SG_ 2153840640 TDFwdClnMtgnBrEvRpt "UNM";
BA_ "SignalLongName" SG_ 2153840640 TDFwdClnMtgnBrEvRpt "Teen Driver Forward Collision Mitigation Braking Events Report";
BA_ "GenSigSendOnInit" SG_ 2153840640 TDFwdClnHdwyAlrtsRpt 2;
BA_ "GenSigSendType" SG_ 2153840640 TDFwdClnHdwyAlrtsRpt 12;
BA_ "GenSigDeltaValue" SG_ 2153840640 TDFwdClnHdwyAlrtsRpt 1;
BA_ "VNSigAllNodes" SG_ 2153840640 TDFwdClnHdwyAlrtsRpt 1;
BA_ "SignalType" SG_ 2153840640 TDFwdClnHdwyAlrtsRpt "UNM";
BA_ "SignalLongName" SG_ 2153840640 TDFwdClnHdwyAlrtsRpt "Teen Driver Forward Collision Headway Alerts Report";
BA_ "VNSigAllNodes" SG_ 2155913216 PFAS_SrvPedAlrtIO 1;
BA_ "SignalType" SG_ 2155913216 PFAS_SrvPedAlrtIO "BLN";
BA_ "PacketOrder" SG_ 2155913216 PFAS_SrvPedAlrtIO 7;
BA_ "SignalLongName" SG_ 2155913216 PFAS_SrvPedAlrtIO "Pedestrian Friendly Alert Status : Service Pedestrian Friendly Alert Indication On";
BA_ "VNSigAllNodes" SG_ 2155913216 PFAS_PFASysStat 1;
BA_ "SignalType" SG_ 2155913216 PFAS_PFASysStat "ENM";
BA_ "PacketOrder" SG_ 2155913216 PFAS_PFASysStat 6;
BA_ "SignalLongName" SG_ 2155913216 PFAS_PFASysStat "Pedestrian Friendly Alert Status : Pedestrian Friendly Alert System Status";
BA_ "VNSigAllNodes" SG_ 2155913216 PFAS_PFASndVolCtrl 1;
BA_ "SignalType" SG_ 2155913216 PFAS_PFASndVolCtrl "UNM";
BA_ "PacketOrder" SG_ 2155913216 PFAS_PFASndVolCtrl 5;
BA_ "SignalLongName" SG_ 2155913216 PFAS_PFASndVolCtrl "Pedestrian Friendly Alert Status : Pedestrian Friendly Alert Sound Volume Control";
BA_ "VNSigAllNodes" SG_ 2155913216 PFAS_PFASndGenEn 1;
BA_ "SignalType" SG_ 2155913216 PFAS_PFASndGenEn "BLN";
BA_ "PacketOrder" SG_ 2155913216 PFAS_PFASndGenEn 1;
BA_ "SignalLongName" SG_ 2155913216 PFAS_PFASndGenEn "Pedestrian Friendly Alert Status : Pedestrian Friendly Alert Sound Generation Enable";
BA_ "VNSigAllNodes" SG_ 2155913216 PFAS_PFARevSnd 1;
BA_ "SignalType" SG_ 2155913216 PFAS_PFARevSnd "ENM";
BA_ "PacketOrder" SG_ 2155913216 PFAS_PFARevSnd 3;
BA_ "SignalLongName" SG_ 2155913216 PFAS_PFARevSnd "Pedestrian Friendly Alert Status : Pedestrian Friendly Alert Reverse Sound";
BA_ "VNSigAllNodes" SG_ 2155913216 PFAS_PFAFwdSnd 1;
BA_ "SignalType" SG_ 2155913216 PFAS_PFAFwdSnd "ENM";
BA_ "PacketOrder" SG_ 2155913216 PFAS_PFAFwdSnd 2;
BA_ "SignalLongName" SG_ 2155913216 PFAS_PFAFwdSnd "Pedestrian Friendly Alert Status : Pedestrian Friendly Alert Forward Sound";
BA_ "VNSigAllNodes" SG_ 2155913216 PFAS_PFACrsOvrSpd 1;
BA_ "SignalType" SG_ 2155913216 PFAS_PFACrsOvrSpd "UNM";
BA_ "PacketOrder" SG_ 2155913216 PFAS_PFACrsOvrSpd 4;
BA_ "SignalLongName" SG_ 2155913216 PFAS_PFACrsOvrSpd "Pedestrian Friendly Alert Status : Pedestrian Friendly Alert Crossover Speed";
BA_ "VNSigAllNodes" SG_ 2155913216 PedFrndlyAlrtCsSetAvl 1;
BA_ "SignalType" SG_ 2155913216 PedFrndlyAlrtCsSetAvl "BLN";
BA_ "SignalLongName" SG_ 2155913216 PedFrndlyAlrtCsSetAvl "Pedestrian Friendly Alert Customization Setting Available";
BA_ "VNSigAllNodes" SG_ 2155913216 PedFrndlyAlrtCsCrStVal 1;
BA_ "SignalType" SG_ 2155913216 PedFrndlyAlrtCsCrStVal "ENM";
BA_ "SignalLongName" SG_ 2155913216 PedFrndlyAlrtCsCrStVal "Pedestrian Friendly Alert Customization Current Setting Value";
BA_ "VNSigAllNodes" SG_ 2155913216 DslExhFldRmngDstHRs 1;
BA_ "SignalType" SG_ 2155913216 DslExhFldRmngDstHRs "UNM";
BA_ "SignalLongName" SG_ 2155913216 DslExhFldRmngDstHRs "Diesel Exhaust Fluid Remaining Distance High Resolution";
BA_ "VNSigAllNodes" SG_ 2155913216 DslExhFluidLvlPrcntV 1;
BA_ "SignalType" SG_ 2155913216 DslExhFluidLvlPrcntV "ENM";
BA_ "SignalLongName" SG_ 2155913216 DslExhFluidLvlPrcntV "Diesel Exhaust Fluid Level Percent Validity";
BA_ "VNSigAllNodes" SG_ 2155913216 DslExhFluidLvlPrcnt 1;
BA_ "SignalType" SG_ 2155913216 DslExhFluidLvlPrcnt "UNM";
BA_ "SignalLongName" SG_ 2155913216 DslExhFluidLvlPrcnt "Diesel Exhaust Fluid Level Percent";
BA_ "VNSigAllNodes" SG_ 2155913216 DslEmnsOBDMrkt 1;
BA_ "SignalType" SG_ 2155913216 DslEmnsOBDMrkt "ENM";
BA_ "SignalLongName" SG_ 2155913216 DslEmnsOBDMrkt "Diesel Emissions OBD Market";
BA_ "VNSigAllNodes" SG_ 2155913216 DslExhFldRmngDstHRsV 1;
BA_ "SignalType" SG_ 2155913216 DslExhFldRmngDstHRsV "ENM";
BA_ "SignalLongName" SG_ 2155913216 DslExhFldRmngDstHRsV "Diesel Exhaust Fluid Remaining Distance High Resolution Validity";
BA_ "VNSigAllNodes" SG_ 2152095744 SPMCA_SusPrfMd6Avl 1;
BA_ "SignalType" SG_ 2152095744 SPMCA_SusPrfMd6Avl "BLN";
BA_ "PacketOrder" SG_ 2152095744 SPMCA_SusPrfMd6Avl 6;
BA_ "SignalLongName" SG_ 2152095744 SPMCA_SusPrfMd6Avl "Suspension Performance Mode Customization Available : Suspension Performance Mode 6 Available";
BA_ "VNSigAllNodes" SG_ 2152095744 SPMCA_SusPrfMd5Avl 1;
BA_ "SignalType" SG_ 2152095744 SPMCA_SusPrfMd5Avl "BLN";
BA_ "PacketOrder" SG_ 2152095744 SPMCA_SusPrfMd5Avl 5;
BA_ "SignalLongName" SG_ 2152095744 SPMCA_SusPrfMd5Avl "Suspension Performance Mode Customization Available : Suspension Performance Mode 5 Available";
BA_ "VNSigAllNodes" SG_ 2152095744 SPMCA_SusPrfMd4Avl 1;
BA_ "SignalType" SG_ 2152095744 SPMCA_SusPrfMd4Avl "BLN";
BA_ "PacketOrder" SG_ 2152095744 SPMCA_SusPrfMd4Avl 4;
BA_ "SignalLongName" SG_ 2152095744 SPMCA_SusPrfMd4Avl "Suspension Performance Mode Customization Available : Suspension Performance Mode 4 Available";
BA_ "VNSigAllNodes" SG_ 2152095744 SPMCA_SusPrfMd3Avl 1;
BA_ "SignalType" SG_ 2152095744 SPMCA_SusPrfMd3Avl "BLN";
BA_ "PacketOrder" SG_ 2152095744 SPMCA_SusPrfMd3Avl 3;
BA_ "SignalLongName" SG_ 2152095744 SPMCA_SusPrfMd3Avl "Suspension Performance Mode Customization Available : Suspension Performance Mode 3 Available";
BA_ "VNSigAllNodes" SG_ 2152095744 SPMCA_SusPrfMd2Avl 1;
BA_ "SignalType" SG_ 2152095744 SPMCA_SusPrfMd2Avl "BLN";
BA_ "PacketOrder" SG_ 2152095744 SPMCA_SusPrfMd2Avl 2;
BA_ "SignalLongName" SG_ 2152095744 SPMCA_SusPrfMd2Avl "Suspension Performance Mode Customization Available : Suspension Performance Mode 2 Available";
BA_ "VNSigAllNodes" SG_ 2152095744 SPMCA_SusPrfMd1Avl 1;
BA_ "SignalType" SG_ 2152095744 SPMCA_SusPrfMd1Avl "BLN";
BA_ "PacketOrder" SG_ 2152095744 SPMCA_SusPrfMd1Avl 1;
BA_ "SignalLongName" SG_ 2152095744 SPMCA_SusPrfMd1Avl "Suspension Performance Mode Customization Available : Suspension Performance Mode 1 Available";
BA_ "VNSigAllNodes" SG_ 2152095744 SPMCA_StrPrfMd6Avl 1;
BA_ "SignalType" SG_ 2152095744 SPMCA_StrPrfMd6Avl "BLN";
BA_ "PacketOrder" SG_ 2152095744 SPMCA_StrPrfMd6Avl 6;
BA_ "SignalLongName" SG_ 2152095744 SPMCA_StrPrfMd6Avl "Steering Performance Mode Customization Available : Steering Performance Mode 6 Available";
BA_ "VNSigAllNodes" SG_ 2152095744 SPMCA_StrPrfMd5Avl 1;
BA_ "SignalType" SG_ 2152095744 SPMCA_StrPrfMd5Avl "BLN";
BA_ "PacketOrder" SG_ 2152095744 SPMCA_StrPrfMd5Avl 5;
BA_ "SignalLongName" SG_ 2152095744 SPMCA_StrPrfMd5Avl "Steering Performance Mode Customization Available : Steering Performance Mode 5 Available";
BA_ "VNSigAllNodes" SG_ 2152095744 SPMCA_StrPrfMd4Avl 1;
BA_ "SignalType" SG_ 2152095744 SPMCA_StrPrfMd4Avl "BLN";
BA_ "PacketOrder" SG_ 2152095744 SPMCA_StrPrfMd4Avl 4;
BA_ "SignalLongName" SG_ 2152095744 SPMCA_StrPrfMd4Avl "Steering Performance Mode Customization Available : Steering Performance Mode 4 Available";
BA_ "VNSigAllNodes" SG_ 2152095744 SPMCA_StrPrfMd3Avl 1;
BA_ "SignalType" SG_ 2152095744 SPMCA_StrPrfMd3Avl "BLN";
BA_ "PacketOrder" SG_ 2152095744 SPMCA_StrPrfMd3Avl 3;
BA_ "SignalLongName" SG_ 2152095744 SPMCA_StrPrfMd3Avl "Steering Performance Mode Customization Available : Steering Performance Mode 3 Available";
BA_ "VNSigAllNodes" SG_ 2152095744 SPMCA_StrPrfMd2Avl 1;
BA_ "SignalType" SG_ 2152095744 SPMCA_StrPrfMd2Avl "BLN";
BA_ "PacketOrder" SG_ 2152095744 SPMCA_StrPrfMd2Avl 2;
BA_ "SignalLongName" SG_ 2152095744 SPMCA_StrPrfMd2Avl "Steering Performance Mode Customization Available : Steering Performance Mode 2 Available";
BA_ "VNSigAllNodes" SG_ 2152095744 SPMCA_StrPrfMd1Avl 1;
BA_ "SignalType" SG_ 2152095744 SPMCA_StrPrfMd1Avl "BLN";
BA_ "PacketOrder" SG_ 2152095744 SPMCA_StrPrfMd1Avl 1;
BA_ "SignalLongName" SG_ 2152095744 SPMCA_StrPrfMd1Avl "Steering Performance Mode Customization Available : Steering Performance Mode 1 Available";
BA_ "VNSigAllNodes" SG_ 2152095744 SPMCA_SndPrfMd6Avl 1;
BA_ "SignalType" SG_ 2152095744 SPMCA_SndPrfMd6Avl "BLN";
BA_ "PacketOrder" SG_ 2152095744 SPMCA_SndPrfMd6Avl 6;
BA_ "SignalLongName" SG_ 2152095744 SPMCA_SndPrfMd6Avl "Sound Performance Mode Customization Available : Sound Performance Mode 6 Available";
BA_ "VNSigAllNodes" SG_ 2152095744 SPMCA_SndPrfMd5Avl 1;
BA_ "SignalType" SG_ 2152095744 SPMCA_SndPrfMd5Avl "BLN";
BA_ "PacketOrder" SG_ 2152095744 SPMCA_SndPrfMd5Avl 5;
BA_ "SignalLongName" SG_ 2152095744 SPMCA_SndPrfMd5Avl "Sound Performance Mode Customization Available : Sound Performance Mode 5 Available";
BA_ "VNSigAllNodes" SG_ 2152095744 SPMCA_SndPrfMd4Avl 1;
BA_ "SignalType" SG_ 2152095744 SPMCA_SndPrfMd4Avl "BLN";
BA_ "PacketOrder" SG_ 2152095744 SPMCA_SndPrfMd4Avl 4;
BA_ "SignalLongName" SG_ 2152095744 SPMCA_SndPrfMd4Avl "Sound Performance Mode Customization Available : Sound Performance Mode 4 Available";
BA_ "VNSigAllNodes" SG_ 2152095744 SPMCA_SndPrfMd3Avl 1;
BA_ "SignalType" SG_ 2152095744 SPMCA_SndPrfMd3Avl "BLN";
BA_ "PacketOrder" SG_ 2152095744 SPMCA_SndPrfMd3Avl 3;
BA_ "SignalLongName" SG_ 2152095744 SPMCA_SndPrfMd3Avl "Sound Performance Mode Customization Available : Sound Performance Mode 3 Available";
BA_ "VNSigAllNodes" SG_ 2152095744 SPMCA_SndPrfMd2Avl 1;
BA_ "SignalType" SG_ 2152095744 SPMCA_SndPrfMd2Avl "BLN";
BA_ "PacketOrder" SG_ 2152095744 SPMCA_SndPrfMd2Avl 2;
BA_ "SignalLongName" SG_ 2152095744 SPMCA_SndPrfMd2Avl "Sound Performance Mode Customization Available : Sound Performance Mode 2 Available";
BA_ "VNSigAllNodes" SG_ 2152095744 SPMCA_SndPrfMd1Avl 1;
BA_ "SignalType" SG_ 2152095744 SPMCA_SndPrfMd1Avl "BLN";
BA_ "PacketOrder" SG_ 2152095744 SPMCA_SndPrfMd1Avl 1;
BA_ "SignalLongName" SG_ 2152095744 SPMCA_SndPrfMd1Avl "Sound Performance Mode Customization Available : Sound Performance Mode 1 Available";
BA_ "VNSigAllNodes" SG_ 2152095744 DPMCA_DispPrfMd6Avl 1;
BA_ "SignalType" SG_ 2152095744 DPMCA_DispPrfMd6Avl "BLN";
BA_ "PacketOrder" SG_ 2152095744 DPMCA_DispPrfMd6Avl 6;
BA_ "SignalLongName" SG_ 2152095744 DPMCA_DispPrfMd6Avl "Display Performance Mode Customization Available : Display Performance Mode 6 Available";
BA_ "VNSigAllNodes" SG_ 2152095744 DPMCA_DispPrfMd5Avl 1;
BA_ "SignalType" SG_ 2152095744 DPMCA_DispPrfMd5Avl "BLN";
BA_ "PacketOrder" SG_ 2152095744 DPMCA_DispPrfMd5Avl 5;
BA_ "SignalLongName" SG_ 2152095744 DPMCA_DispPrfMd5Avl "Display Performance Mode Customization Available : Display Performance Mode 5 Available";
BA_ "VNSigAllNodes" SG_ 2152095744 DPMCA_DispPrfMd4Avl 1;
BA_ "SignalType" SG_ 2152095744 DPMCA_DispPrfMd4Avl "BLN";
BA_ "PacketOrder" SG_ 2152095744 DPMCA_DispPrfMd4Avl 4;
BA_ "SignalLongName" SG_ 2152095744 DPMCA_DispPrfMd4Avl "Display Performance Mode Customization Available : Display Performance Mode 4 Available";
BA_ "VNSigAllNodes" SG_ 2152095744 DPMCA_DispPrfMd3Avl 1;
BA_ "SignalType" SG_ 2152095744 DPMCA_DispPrfMd3Avl "BLN";
BA_ "PacketOrder" SG_ 2152095744 DPMCA_DispPrfMd3Avl 3;
BA_ "SignalLongName" SG_ 2152095744 DPMCA_DispPrfMd3Avl "Display Performance Mode Customization Available : Display Performance Mode 3 Available";
BA_ "VNSigAllNodes" SG_ 2152095744 DPMCA_DispPrfMd2Avl 1;
BA_ "SignalType" SG_ 2152095744 DPMCA_DispPrfMd2Avl "BLN";
BA_ "PacketOrder" SG_ 2152095744 DPMCA_DispPrfMd2Avl 2;
BA_ "SignalLongName" SG_ 2152095744 DPMCA_DispPrfMd2Avl "Display Performance Mode Customization Available : Display Performance Mode 2 Available";
BA_ "VNSigAllNodes" SG_ 2152095744 DPMCA_DispPrfMd1Avl 1;
BA_ "SignalType" SG_ 2152095744 DPMCA_DispPrfMd1Avl "BLN";
BA_ "PacketOrder" SG_ 2152095744 DPMCA_DispPrfMd1Avl 1;
BA_ "SignalLongName" SG_ 2152095744 DPMCA_DispPrfMd1Avl "Display Performance Mode Customization Available : Display Performance Mode 1 Available";
BA_ "VNSigAllNodes" SG_ 2152095744 DPMCA_DrvlPrfMd6Avl 1;
BA_ "SignalType" SG_ 2152095744 DPMCA_DrvlPrfMd6Avl "BLN";
BA_ "PacketOrder" SG_ 2152095744 DPMCA_DrvlPrfMd6Avl 6;
BA_ "SignalLongName" SG_ 2152095744 DPMCA_DrvlPrfMd6Avl "Driveline Performance Mode Customization Available : Driveline Performance Mode 6 Available";
BA_ "VNSigAllNodes" SG_ 2152095744 DPMCA_DrvlPrfMd5Avl 1;
BA_ "SignalType" SG_ 2152095744 DPMCA_DrvlPrfMd5Avl "BLN";
BA_ "PacketOrder" SG_ 2152095744 DPMCA_DrvlPrfMd5Avl 5;
BA_ "SignalLongName" SG_ 2152095744 DPMCA_DrvlPrfMd5Avl "Driveline Performance Mode Customization Available : Driveline Performance Mode 5 Available";
BA_ "VNSigAllNodes" SG_ 2152095744 DPMCA_DrvlPrfMd4Avl 1;
BA_ "SignalType" SG_ 2152095744 DPMCA_DrvlPrfMd4Avl "BLN";
BA_ "PacketOrder" SG_ 2152095744 DPMCA_DrvlPrfMd4Avl 4;
BA_ "SignalLongName" SG_ 2152095744 DPMCA_DrvlPrfMd4Avl "Driveline Performance Mode Customization Available : Driveline Performance Mode 4 Available";
BA_ "VNSigAllNodes" SG_ 2152095744 DPMCA_DrvlPrfMd3Avl 1;
BA_ "SignalType" SG_ 2152095744 DPMCA_DrvlPrfMd3Avl "BLN";
BA_ "PacketOrder" SG_ 2152095744 DPMCA_DrvlPrfMd3Avl 3;
BA_ "SignalLongName" SG_ 2152095744 DPMCA_DrvlPrfMd3Avl "Driveline Performance Mode Customization Available : Driveline Performance Mode 3 Available";
BA_ "VNSigAllNodes" SG_ 2152095744 DPMCA_DrvlPrfMd2Avl 1;
BA_ "SignalType" SG_ 2152095744 DPMCA_DrvlPrfMd2Avl "BLN";
BA_ "PacketOrder" SG_ 2152095744 DPMCA_DrvlPrfMd2Avl 2;
BA_ "SignalLongName" SG_ 2152095744 DPMCA_DrvlPrfMd2Avl "Driveline Performance Mode Customization Available : Driveline Performance Mode 2 Available";
BA_ "VNSigAllNodes" SG_ 2152095744 DPMCA_DrvlPrfMd1Avl 1;
BA_ "SignalType" SG_ 2152095744 DPMCA_DrvlPrfMd1Avl "BLN";
BA_ "PacketOrder" SG_ 2152095744 DPMCA_DrvlPrfMd1Avl 1;
BA_ "SignalLongName" SG_ 2152095744 DPMCA_DrvlPrfMd1Avl "Driveline Performance Mode Customization Available : Driveline Performance Mode 1 Available";
BA_ "VNSigAllNodes" SG_ 2151899136 PTOAccelUpnBrkRelIO 1;
BA_ "SignalType" SG_ 2151899136 PTOAccelUpnBrkRelIO "BLN";
BA_ "SignalLongName" SG_ 2151899136 PTOAccelUpnBrkRelIO "Power Take Off Acceleration Upon Brake Release Indication On";
BA_ "VNSigAllNodes" SG_ 2151899136 PTOEngUpnBrkRelIO 1;
BA_ "SignalType" SG_ 2151899136 PTOEngUpnBrkRelIO "BLN";
BA_ "SignalLongName" SG_ 2151899136 PTOEngUpnBrkRelIO "Power Take Off Engage Upon Brake Release Indication On";
BA_ "VNSigAllNodes" SG_ 2151899136 PTOManTransInGrIO 1;
BA_ "SignalType" SG_ 2151899136 PTOManTransInGrIO "BLN";
BA_ "SignalLongName" SG_ 2151899136 PTOManTransInGrIO "Power Take Off Manual Transmission In Gear Indication On";
BA_ "VNSigAllNodes" SG_ 2151899136 PTOServIndOn 1;
BA_ "SignalType" SG_ 2151899136 PTOServIndOn "BLN";
BA_ "SignalLongName" SG_ 2151899136 PTOServIndOn "Power Take Off Service Indication On";
BA_ "VNSigAllNodes" SG_ 2151899136 PTOVDM 1;
BA_ "SignalType" SG_ 2151899136 PTOVDM "ENM";
BA_ "SignalLongName" SG_ 2151899136 PTOVDM "Power Take Off Virtual Device Mask";
BA_ "VNSigAllNodes" SG_ 2151899136 PTOVDA 1;
BA_ "SignalType" SG_ 2151899136 PTOVDA "ENM";
BA_ "SignalLongName" SG_ 2151899136 PTOVDA "Power Take Off Virtual Device Availability";
BA_ "GenSigStartValue" SG_ 2151899136 PTOVDA 1;
BA_ "VNSigAllNodes" SG_ 2151899136 PTOTransInGearIO 1;
BA_ "SignalType" SG_ 2151899136 PTOTransInGearIO "BLN";
BA_ "SignalLongName" SG_ 2151899136 PTOTransInGearIO "Power Take Off Transmission In Gear Indication On";
BA_ "VNSigAllNodes" SG_ 2151899136 PTOTpStpSpdCsStAvl 1;
BA_ "SignalType" SG_ 2151899136 PTOTpStpSpdCsStAvl "BLN";
BA_ "SignalLongName" SG_ 2151899136 PTOTpStpSpdCsStAvl "Power Take Off Tap Step Speed Customization Setting Available";
BA_ "VNSigAllNodes" SG_ 2151899136 PTOTpStSpdCsCrStVal 1;
BA_ "SignalType" SG_ 2151899136 PTOTpStSpdCsCrStVal "ENM";
BA_ "SignalLongName" SG_ 2151899136 PTOTpStSpdCsCrStVal "Power Take Off Tap Step Speed Customization Current Setting Value";
BA_ "VNSigAllNodes" SG_ 2151899136 PTOStdbySpdCsStAvl 1;
BA_ "SignalType" SG_ 2151899136 PTOStdbySpdCsStAvl "BLN";
BA_ "SignalLongName" SG_ 2151899136 PTOStdbySpdCsStAvl "Power Take Off Standby Speed Customization Setting Available";
BA_ "VNSigAllNodes" SG_ 2151899136 PTOStdbSpdCsCrStVal 1;
BA_ "SignalType" SG_ 2151899136 PTOStdbSpdCsCrStVal "ENM";
BA_ "SignalLongName" SG_ 2151899136 PTOStdbSpdCsCrStVal "Power Take Off Standby Speed Customization Current Setting Value";
BA_ "VNSigAllNodes" SG_ 2151899136 PTOSetPrkBrkIO 1;
BA_ "SignalType" SG_ 2151899136 PTOSetPrkBrkIO "BLN";
BA_ "SignalLongName" SG_ 2151899136 PTOSetPrkBrkIO "Power Take Off Set Park Brake Indication On";
BA_ "VNSigAllNodes" SG_ 2151899136 PTOSet2SpdCsStAvl 1;
BA_ "SignalType" SG_ 2151899136 PTOSet2SpdCsStAvl "BLN";
BA_ "SignalLongName" SG_ 2151899136 PTOSet2SpdCsStAvl "Power Take Off Set 2 Speed Customization Setting Available";
BA_ "VNSigAllNodes" SG_ 2151899136 PTOSet2SpdCsCrStVal 1;
BA_ "SignalType" SG_ 2151899136 PTOSet2SpdCsCrStVal "ENM";
BA_ "SignalLongName" SG_ 2151899136 PTOSet2SpdCsCrStVal "Power Take Off Set 2 Speed Customization Current Setting Value";
BA_ "VNSigAllNodes" SG_ 2151899136 PTOSet1SpdCsStAvl 1;
BA_ "SignalType" SG_ 2151899136 PTOSet1SpdCsStAvl "BLN";
BA_ "SignalLongName" SG_ 2151899136 PTOSet1SpdCsStAvl "Power Take Off Set 1 Speed Customization Setting Available";
BA_ "VNSigAllNodes" SG_ 2151899136 PTOSet1SpdCsCrStVal 1;
BA_ "SignalType" SG_ 2151899136 PTOSet1SpdCsCrStVal "ENM";
BA_ "SignalLongName" SG_ 2151899136 PTOSet1SpdCsCrStVal "Power Take Off Set 1 Speed Customization Current Setting Value";
BA_ "VNSigAllNodes" SG_ 2151899136 PTORelCltPedIO 1;
BA_ "SignalType" SG_ 2151899136 PTORelCltPedIO "BLN";
BA_ "SignalLongName" SG_ 2151899136 PTORelCltPedIO "Power Take Off Release Clutch Pedal Indication On";
BA_ "VNSigAllNodes" SG_ 2151899136 PTORelBrkPedIO 1;
BA_ "SignalType" SG_ 2151899136 PTORelBrkPedIO "BLN";
BA_ "SignalLongName" SG_ 2151899136 PTORelBrkPedIO "Power Take Off Release Brake Pedal Indication On";
BA_ "VNSigAllNodes" SG_ 2151899136 PTORelAccPedIO 1;
BA_ "SignalType" SG_ 2151899136 PTORelAccPedIO "BLN";
BA_ "SignalLongName" SG_ 2151899136 PTORelAccPedIO "Power Take Off Release Accelerator Pedal Indication On";
BA_ "VNSigAllNodes" SG_ 2151899136 PTORedEngSpdIO 1;
BA_ "SignalType" SG_ 2151899136 PTORedEngSpdIO "BLN";
BA_ "SignalLongName" SG_ 2151899136 PTORedEngSpdIO "Power Take Off Reduce Engine Speed Indication On";
BA_ "VNSigAllNodes" SG_ 2151899136 PTOPrsRelCltPedIO 1;
BA_ "SignalType" SG_ 2151899136 PTOPrsRelCltPedIO "BLN";
BA_ "SignalLongName" SG_ 2151899136 PTOPrsRelCltPedIO "Power Take Off Press and Release Clutch Pedal Indication On";
BA_ "VNSigAllNodes" SG_ 2151899136 PTOPrsRelBrkPedIO 1;
BA_ "SignalType" SG_ 2151899136 PTOPrsRelBrkPedIO "BLN";
BA_ "SignalLongName" SG_ 2151899136 PTOPrsRelBrkPedIO "Power Take Off Press and Release Brake Pedal Indication On";
BA_ "VNSigAllNodes" SG_ 2151899136 PTOEngRnTmrCsStAvl 1;
BA_ "SignalType" SG_ 2151899136 PTOEngRnTmrCsStAvl "BLN";
BA_ "SignalLongName" SG_ 2151899136 PTOEngRnTmrCsStAvl "Power Take Off Engine Run Timer Customization Setting Available";
BA_ "VNSigAllNodes" SG_ 2151899136 PTOEnRnTmCsCrStVal 1;
BA_ "SignalType" SG_ 2151899136 PTOEnRnTmCsCrStVal "ENM";
BA_ "SignalLongName" SG_ 2151899136 PTOEnRnTmCsCrStVal "Power Take Off Engine Run Timer Customization Current Setting Value";
BA_ "VNSigAllNodes" SG_ 2151899136 PTOEngmntStatInd 1;
BA_ "SignalType" SG_ 2151899136 PTOEngmntStatInd "ENM";
BA_ "SignalLongName" SG_ 2151899136 PTOEngmntStatInd "Power Take Off Engagement Status Indication";
BA_ "VNSigAllNodes" SG_ 2151899136 PTODisengCrsCntlIO 1;
BA_ "SignalType" SG_ 2151899136 PTODisengCrsCntlIO "BLN";
BA_ "SignalLongName" SG_ 2151899136 PTODisengCrsCntlIO "Power Take Off Disengage Cruise Control Indication On";
BA_ "GenSigSendType" SG_ 2150449152 ESPDrvrExtIO 10;
BA_ "VNSigAllNodes" SG_ 2150449152 ESPDrvrExtIO 1;
BA_ "SignalType" SG_ 2150449152 ESPDrvrExtIO "BLN";
BA_ "SignalLongName" SG_ 2150449152 ESPDrvrExtIO "Electronic Shift Primary Driver Exit Indication On";
BA_ "GenSigSendType" SG_ 2150449152 ESPDrvrDrStIndtrmntIO 10;
BA_ "VNSigAllNodes" SG_ 2150449152 ESPDrvrDrStIndtrmntIO 1;
BA_ "SignalType" SG_ 2150449152 ESPDrvrDrStIndtrmntIO "BLN";
BA_ "SignalLongName" SG_ 2150449152 ESPDrvrDrStIndtrmntIO "Electronic Shift Primary Driver Door State Indeterminate Indication On";
BA_ "GenSigSendType" SG_ 2150449152 ESPAutoPrkIO 10;
BA_ "VNSigAllNodes" SG_ 2150449152 ESPAutoPrkIO 1;
BA_ "SignalType" SG_ 2150449152 ESPAutoPrkIO "BLN";
BA_ "SignalLongName" SG_ 2150449152 ESPAutoPrkIO "Electronic Shift Primary Auto Park Indication On";
BA_ "GenSigSendType" SG_ 2150449152 ManTransIndReq 10;
BA_ "VNSigAllNodes" SG_ 2150449152 ManTransIndReq 1;
BA_ "SignalType" SG_ 2150449152 ManTransIndReq "ENM";
BA_ "SignalLongName" SG_ 2150449152 ManTransIndReq "Manual Transmission Indication Request";
BA_ "GenSigSendType" SG_ 2150449152 SrvcFlSysPrkInOpnArIO 10;
BA_ "VNSigAllNodes" SG_ 2150449152 SrvcFlSysPrkInOpnArIO 1;
BA_ "SignalType" SG_ 2150449152 SrvcFlSysPrkInOpnArIO "BLN";
BA_ "SignalLongName" SG_ 2150449152 SrvcFlSysPrkInOpnArIO "Service Fuel System Park In Open Area Indication On";
BA_ "GenSigSendType" SG_ 2150449152 TnDrvStblCtrlOffUnbIO 10;
BA_ "VNSigAllNodes" SG_ 2150449152 TnDrvStblCtrlOffUnbIO 1;
BA_ "SignalType" SG_ 2150449152 TnDrvStblCtrlOffUnbIO "BLN";
BA_ "SignalLongName" SG_ 2150449152 TnDrvStblCtrlOffUnbIO "Teen Driver Stability Control Off Unavailable Indication On";
BA_ "GenSigSendType" SG_ 2150449152 TnDrvTrCtrlOffUnbIO 10;
BA_ "VNSigAllNodes" SG_ 2150449152 TnDrvTrCtrlOffUnbIO 1;
BA_ "SignalType" SG_ 2150449152 TnDrvTrCtrlOffUnbIO "BLN";
BA_ "SignalLongName" SG_ 2150449152 TnDrvTrCtrlOffUnbIO "Teen Driver Traction Control Off Unavailable Indication On";
BA_ "GenSigSendType" SG_ 2150449152 ASIRI_Indication08 10;
BA_ "VNSigAllNodes" SG_ 2150449152 ASIRI_Indication08 1;
BA_ "SignalType" SG_ 2150449152 ASIRI_Indication08 "BLN";
BA_ "PacketOrder" SG_ 2150449152 ASIRI_Indication08 8;
BA_ "SignalLongName" SG_ 2150449152 ASIRI_Indication08 "Auto Stop Inhibit Reason Indication : Indication 8";
BA_ "GenSigSendType" SG_ 2150449152 ASIRI_Indication07 10;
BA_ "VNSigAllNodes" SG_ 2150449152 ASIRI_Indication07 1;
BA_ "SignalType" SG_ 2150449152 ASIRI_Indication07 "BLN";
BA_ "PacketOrder" SG_ 2150449152 ASIRI_Indication07 7;
BA_ "SignalLongName" SG_ 2150449152 ASIRI_Indication07 "Auto Stop Inhibit Reason Indication : Indication 7";
BA_ "GenSigSendType" SG_ 2150449152 ASIRI_Indication06 10;
BA_ "VNSigAllNodes" SG_ 2150449152 ASIRI_Indication06 1;
BA_ "SignalType" SG_ 2150449152 ASIRI_Indication06 "BLN";
BA_ "PacketOrder" SG_ 2150449152 ASIRI_Indication06 6;
BA_ "SignalLongName" SG_ 2150449152 ASIRI_Indication06 "Auto Stop Inhibit Reason Indication : Indication 6";
BA_ "GenSigSendType" SG_ 2150449152 ASIRI_Indication05 10;
BA_ "VNSigAllNodes" SG_ 2150449152 ASIRI_Indication05 1;
BA_ "SignalType" SG_ 2150449152 ASIRI_Indication05 "BLN";
BA_ "PacketOrder" SG_ 2150449152 ASIRI_Indication05 5;
BA_ "SignalLongName" SG_ 2150449152 ASIRI_Indication05 "Auto Stop Inhibit Reason Indication : Indication 5";
BA_ "GenSigSendType" SG_ 2150449152 ASIRI_Indication04 10;
BA_ "VNSigAllNodes" SG_ 2150449152 ASIRI_Indication04 1;
BA_ "SignalType" SG_ 2150449152 ASIRI_Indication04 "BLN";
BA_ "PacketOrder" SG_ 2150449152 ASIRI_Indication04 4;
BA_ "SignalLongName" SG_ 2150449152 ASIRI_Indication04 "Auto Stop Inhibit Reason Indication : Indication 4";
BA_ "GenSigSendType" SG_ 2150449152 ASIRI_Indication03 10;
BA_ "VNSigAllNodes" SG_ 2150449152 ASIRI_Indication03 1;
BA_ "SignalType" SG_ 2150449152 ASIRI_Indication03 "BLN";
BA_ "PacketOrder" SG_ 2150449152 ASIRI_Indication03 3;
BA_ "SignalLongName" SG_ 2150449152 ASIRI_Indication03 "Auto Stop Inhibit Reason Indication : Indication 3";
BA_ "GenSigSendType" SG_ 2150449152 ASIRI_Indication02 10;
BA_ "VNSigAllNodes" SG_ 2150449152 ASIRI_Indication02 1;
BA_ "SignalType" SG_ 2150449152 ASIRI_Indication02 "BLN";
BA_ "PacketOrder" SG_ 2150449152 ASIRI_Indication02 2;
BA_ "SignalLongName" SG_ 2150449152 ASIRI_Indication02 "Auto Stop Inhibit Reason Indication : Indication 2";
BA_ "GenSigSendType" SG_ 2150449152 ASIRI_Indication01 10;
BA_ "VNSigAllNodes" SG_ 2150449152 ASIRI_Indication01 1;
BA_ "SignalType" SG_ 2150449152 ASIRI_Indication01 "BLN";
BA_ "PacketOrder" SG_ 2150449152 ASIRI_Indication01 1;
BA_ "SignalLongName" SG_ 2150449152 ASIRI_Indication01 "Auto Stop Inhibit Reason Indication : Indication 1";
BA_ "GenSigSendType" SG_ 2150449152 SpdLmtrSttngTypAct 10;
BA_ "VNSigAllNodes" SG_ 2150449152 SpdLmtrSttngTypAct 1;
BA_ "SignalType" SG_ 2150449152 SpdLmtrSttngTypAct "ENM";
BA_ "SignalLongName" SG_ 2150449152 SpdLmtrSttngTypAct "Speed Limiter Setting Type Active";
BA_ "GenSigSendType" SG_ 2150449152 FuelSysNEmsRltMalfAct 10;
BA_ "VNSigAllNodes" SG_ 2150449152 FuelSysNEmsRltMalfAct 1;
BA_ "SignalType" SG_ 2150449152 FuelSysNEmsRltMalfAct "BLN";
BA_ "SignalLongName" SG_ 2150449152 FuelSysNEmsRltMalfAct "Fuel System Non Emissions Related Malfunction Active";
BA_ "GenSigSendType" SG_ 2150449152 InActFuelMdFuelLvlIO 10;
BA_ "VNSigAllNodes" SG_ 2150449152 InActFuelMdFuelLvlIO 1;
BA_ "SignalType" SG_ 2150449152 InActFuelMdFuelLvlIO "BLN";
BA_ "SignalLongName" SG_ 2150449152 InActFuelMdFuelLvlIO "Inactive Fuel Mode Fuel Level Indication On";
BA_ "GenSigSendType" SG_ 2150449152 EngInltSpcfcHmdtyV 10;
BA_ "VNSigAllNodes" SG_ 2150449152 EngInltSpcfcHmdtyV 1;
BA_ "SignalType" SG_ 2150449152 EngInltSpcfcHmdtyV "ENM";
BA_ "SignalLongName" SG_ 2150449152 EngInltSpcfcHmdtyV "Engine Inlet Specific Humidity Validity";
BA_ "GenSigSendType" SG_ 2150449152 EngInltSpcfcHmdtyM 10;
BA_ "VNSigAllNodes" SG_ 2150449152 EngInltSpcfcHmdtyM 1;
BA_ "SignalType" SG_ 2150449152 EngInltSpcfcHmdtyM "ENM";
BA_ "SignalLongName" SG_ 2150449152 EngInltSpcfcHmdtyM "Engine Inlet Specific Humidity Mask";
BA_ "GenSigSendType" SG_ 2150449152 EngInltSpcfcHmdty 12;
BA_ "GenSigDeltaValue" SG_ 2150449152 EngInltSpcfcHmdty 1;
BA_ "VNSigAllNodes" SG_ 2150449152 EngInltSpcfcHmdty 1;
BA_ "SignalType" SG_ 2150449152 EngInltSpcfcHmdty "UNM";
BA_ "SignalLongName" SG_ 2150449152 EngInltSpcfcHmdty "Engine Inlet Specific Humidity";
BA_ "GenSigSendType" SG_ 2149810176 FCAHptcStVbnRqSeqN 12;
BA_ "GenSigDeltaValue" SG_ 2149810176 FCAHptcStVbnRqSeqN 1;
BA_ "VNSigAllNodes" SG_ 2149810176 FCAHptcStVbnRqSeqN 1;
BA_ "SignalType" SG_ 2149810176 FCAHptcStVbnRqSeqN "UNM";
BA_ "SignalLongName" SG_ 2149810176 FCAHptcStVbnRqSeqN "Forward Collision Alert Haptic Seat Vibration Request Sequence Number";
BA_ "GenSigSendType" SG_ 2149810176 FCAHptcStVbnReq 12;
BA_ "GenSigDeltaValue" SG_ 2149810176 FCAHptcStVbnReq 1;
BA_ "VNSigAllNodes" SG_ 2149810176 FCAHptcStVbnReq 1;
BA_ "SignalType" SG_ 2149810176 FCAHptcStVbnReq "UNM";
BA_ "SignalLongName" SG_ 2149810176 FCAHptcStVbnReq "Forward Collision Alert Haptic Seat Vibration Request";
BA_ "GenSigSendOnInit" SG_ 2149793792 VADIR_IndLvl 1;
BA_ "GenSigSendType" SG_ 2149793792 VADIR_IndLvl 10;
BA_ "VNSigAllNodes" SG_ 2149793792 VADIR_IndLvl 1;
BA_ "SignalType" SG_ 2149793792 VADIR_IndLvl "ENM";
BA_ "PacketOrder" SG_ 2149793792 VADIR_IndLvl 1;
BA_ "SignalLongName" SG_ 2149793792 VADIR_IndLvl "Vehicle Ahead Distance Indication Request : Indication Level";
BA_ "GenSigSendOnInit" SG_ 2149793792 VADIR_FlwTme 1;
BA_ "GenSigSendType" SG_ 2149793792 VADIR_FlwTme 12;
BA_ "GenSigDeltaValue" SG_ 2149793792 VADIR_FlwTme 1;
BA_ "VNSigAllNodes" SG_ 2149793792 VADIR_FlwTme 1;
BA_ "SignalType" SG_ 2149793792 VADIR_FlwTme "UNM";
BA_ "PacketOrder" SG_ 2149793792 VADIR_FlwTme 2;
BA_ "SignalLongName" SG_ 2149793792 VADIR_FlwTme "Vehicle Ahead Distance Indication Request : Following Time";
BA_ "GenSigSendOnInit" SG_ 2149793792 VADIR_FlwDst 1;
BA_ "GenSigSendType" SG_ 2149793792 VADIR_FlwDst 12;
BA_ "GenSigDeltaValue" SG_ 2149793792 VADIR_FlwDst 1;
BA_ "VNSigAllNodes" SG_ 2149793792 VADIR_FlwDst 1;
BA_ "SignalType" SG_ 2149793792 VADIR_FlwDst "UNM";
BA_ "PacketOrder" SG_ 2149793792 VADIR_FlwDst 3;
BA_ "SignalLongName" SG_ 2149793792 VADIR_FlwDst "Vehicle Ahead Distance Indication Request : Following Distance";
BA_ "GenSigSendOnInit" SG_ 2149793792 FCACustStngAvlbl 2;
BA_ "GenSigSendType" SG_ 2149793792 FCACustStngAvlbl 10;
BA_ "VNSigAllNodes" SG_ 2149793792 FCACustStngAvlbl 1;
BA_ "SignalType" SG_ 2149793792 FCACustStngAvlbl "BLN";
BA_ "SignalLongName" SG_ 2149793792 FCACustStngAvlbl "Forward Collision Alert Customization Setting Available";
BA_ "GenSigSendOnInit" SG_ 2149793792 FwdClnAlrtCustCrntSetngVal 2;
BA_ "GenSigSendType" SG_ 2149793792 FwdClnAlrtCustCrntSetngVal 10;
BA_ "VNSigAllNodes" SG_ 2149793792 FwdClnAlrtCustCrntSetngVal 1;
BA_ "SignalType" SG_ 2149793792 FwdClnAlrtCustCrntSetngVal "ENM";
BA_ "SignalLongName" SG_ 2149793792 FwdClnAlrtCustCrntSetngVal "Forward Collision Alert Customization Current Setting Value";
BA_ "VNSigAllNodes" SG_ 2152128512 PSPMCA_PsngStPrfMd6Avl 1;
BA_ "SignalType" SG_ 2152128512 PSPMCA_PsngStPrfMd6Avl "BLN";
BA_ "PacketOrder" SG_ 2152128512 PSPMCA_PsngStPrfMd6Avl 6;
BA_ "SignalLongName" SG_ 2152128512 PSPMCA_PsngStPrfMd6Avl "Passenger Seat Performance Mode Customization Available : Passenger Seat Performance Mode 6 Available";
BA_ "VNSigAllNodes" SG_ 2152128512 PSPMCA_PsngStPrfMd5Avl 1;
BA_ "SignalType" SG_ 2152128512 PSPMCA_PsngStPrfMd5Avl "BLN";
BA_ "PacketOrder" SG_ 2152128512 PSPMCA_PsngStPrfMd5Avl 5;
BA_ "SignalLongName" SG_ 2152128512 PSPMCA_PsngStPrfMd5Avl "Passenger Seat Performance Mode Customization Available : Passenger Seat Performance Mode 5 Available";
BA_ "VNSigAllNodes" SG_ 2152128512 PSPMCA_PsngStPrfMd4Avl 1;
BA_ "SignalType" SG_ 2152128512 PSPMCA_PsngStPrfMd4Avl "BLN";
BA_ "PacketOrder" SG_ 2152128512 PSPMCA_PsngStPrfMd4Avl 4;
BA_ "SignalLongName" SG_ 2152128512 PSPMCA_PsngStPrfMd4Avl "Passenger Seat Performance Mode Customization Available : Passenger Seat Performance Mode 4 Available";
BA_ "VNSigAllNodes" SG_ 2152128512 PSPMCA_PsngStPrfMd3Avl 1;
BA_ "SignalType" SG_ 2152128512 PSPMCA_PsngStPrfMd3Avl "BLN";
BA_ "PacketOrder" SG_ 2152128512 PSPMCA_PsngStPrfMd3Avl 3;
BA_ "SignalLongName" SG_ 2152128512 PSPMCA_PsngStPrfMd3Avl "Passenger Seat Performance Mode Customization Available : Passenger Seat Performance Mode 3 Available";
BA_ "VNSigAllNodes" SG_ 2152128512 PSPMCA_PsngStPrfMd2Avl 1;
BA_ "SignalType" SG_ 2152128512 PSPMCA_PsngStPrfMd2Avl "BLN";
BA_ "PacketOrder" SG_ 2152128512 PSPMCA_PsngStPrfMd2Avl 2;
BA_ "SignalLongName" SG_ 2152128512 PSPMCA_PsngStPrfMd2Avl "Passenger Seat Performance Mode Customization Available : Passenger Seat Performance Mode 2 Available";
BA_ "VNSigAllNodes" SG_ 2152128512 PSPMCA_PsngStPrfMd1Avl 1;
BA_ "SignalType" SG_ 2152128512 PSPMCA_PsngStPrfMd1Avl "BLN";
BA_ "PacketOrder" SG_ 2152128512 PSPMCA_PsngStPrfMd1Avl 1;
BA_ "SignalLongName" SG_ 2152128512 PSPMCA_PsngStPrfMd1Avl "Passenger Seat Performance Mode Customization Available : Passenger Seat Performance Mode 1 Available";
BA_ "VNSigAllNodes" SG_ 2152128512 DSPMCA_DrvrStPrfMd6Avl 1;
BA_ "SignalType" SG_ 2152128512 DSPMCA_DrvrStPrfMd6Avl "BLN";
BA_ "PacketOrder" SG_ 2152128512 DSPMCA_DrvrStPrfMd6Avl 6;
BA_ "SignalLongName" SG_ 2152128512 DSPMCA_DrvrStPrfMd6Avl "Driver Seat Performance Mode Customization Available : Driver Seat Performance Mode 6 Available";
BA_ "VNSigAllNodes" SG_ 2152128512 DSPMCA_DrvrStPrfMd5Avl 1;
BA_ "SignalType" SG_ 2152128512 DSPMCA_DrvrStPrfMd5Avl "BLN";
BA_ "PacketOrder" SG_ 2152128512 DSPMCA_DrvrStPrfMd5Avl 5;
BA_ "SignalLongName" SG_ 2152128512 DSPMCA_DrvrStPrfMd5Avl "Driver Seat Performance Mode Customization Available : Driver Seat Performance Mode 5 Available";
BA_ "VNSigAllNodes" SG_ 2152128512 DSPMCA_DrvrStPrfMd4Avl 1;
BA_ "SignalType" SG_ 2152128512 DSPMCA_DrvrStPrfMd4Avl "BLN";
BA_ "PacketOrder" SG_ 2152128512 DSPMCA_DrvrStPrfMd4Avl 4;
BA_ "SignalLongName" SG_ 2152128512 DSPMCA_DrvrStPrfMd4Avl "Driver Seat Performance Mode Customization Available : Driver Seat Performance Mode 4 Available";
BA_ "VNSigAllNodes" SG_ 2152128512 DSPMCA_DrvrStPrfMd3Avl 1;
BA_ "SignalType" SG_ 2152128512 DSPMCA_DrvrStPrfMd3Avl "BLN";
BA_ "PacketOrder" SG_ 2152128512 DSPMCA_DrvrStPrfMd3Avl 3;
BA_ "SignalLongName" SG_ 2152128512 DSPMCA_DrvrStPrfMd3Avl "Driver Seat Performance Mode Customization Available : Driver Seat Performance Mode 3 Available";
BA_ "VNSigAllNodes" SG_ 2152128512 DSPMCA_DrvrStPrfMd2Avl 1;
BA_ "SignalType" SG_ 2152128512 DSPMCA_DrvrStPrfMd2Avl "BLN";
BA_ "PacketOrder" SG_ 2152128512 DSPMCA_DrvrStPrfMd2Avl 2;
BA_ "SignalLongName" SG_ 2152128512 DSPMCA_DrvrStPrfMd2Avl "Driver Seat Performance Mode Customization Available : Driver Seat Performance Mode 2 Available";
BA_ "VNSigAllNodes" SG_ 2152128512 DSPMCA_DrvrStPrfMd1Avl 1;
BA_ "SignalType" SG_ 2152128512 DSPMCA_DrvrStPrfMd1Avl "BLN";
BA_ "PacketOrder" SG_ 2152128512 DSPMCA_DrvrStPrfMd1Avl 1;
BA_ "SignalLongName" SG_ 2152128512 DSPMCA_DrvrStPrfMd1Avl "Driver Seat Performance Mode Customization Available : Driver Seat Performance Mode 1 Available";
BA_ "VNSigAllNodes" SG_ 2152128512 DSPMCA_DrvStyPrfMd7Avl 1;
BA_ "SignalType" SG_ 2152128512 DSPMCA_DrvStyPrfMd7Avl "BLN";
BA_ "PacketOrder" SG_ 2152128512 DSPMCA_DrvStyPrfMd7Avl 7;
BA_ "SignalLongName" SG_ 2152128512 DSPMCA_DrvStyPrfMd7Avl "Driving Style Performance Mode Customization Available : Driving Style Performance Mode 7 Available";
BA_ "VNSigAllNodes" SG_ 2152128512 DSPMCA_DrvStyPrfMd6Avl 1;
BA_ "SignalType" SG_ 2152128512 DSPMCA_DrvStyPrfMd6Avl "BLN";
BA_ "PacketOrder" SG_ 2152128512 DSPMCA_DrvStyPrfMd6Avl 6;
BA_ "SignalLongName" SG_ 2152128512 DSPMCA_DrvStyPrfMd6Avl "Driving Style Performance Mode Customization Available : Driving Style Performance Mode 6 Available";
BA_ "VNSigAllNodes" SG_ 2152128512 DSPMCA_DrvStyPrfMd5Avl 1;
BA_ "SignalType" SG_ 2152128512 DSPMCA_DrvStyPrfMd5Avl "BLN";
BA_ "PacketOrder" SG_ 2152128512 DSPMCA_DrvStyPrfMd5Avl 5;
BA_ "SignalLongName" SG_ 2152128512 DSPMCA_DrvStyPrfMd5Avl "Driving Style Performance Mode Customization Available : Driving Style Performance Mode 5 Available";
BA_ "VNSigAllNodes" SG_ 2152128512 DSPMCA_DrvStyPrfMd4Avl 1;
BA_ "SignalType" SG_ 2152128512 DSPMCA_DrvStyPrfMd4Avl "BLN";
BA_ "PacketOrder" SG_ 2152128512 DSPMCA_DrvStyPrfMd4Avl 4;
BA_ "SignalLongName" SG_ 2152128512 DSPMCA_DrvStyPrfMd4Avl "Driving Style Performance Mode Customization Available : Driving Style Performance Mode 4 Available";
BA_ "VNSigAllNodes" SG_ 2152128512 DSPMCA_DrvStyPrfMd3Avl 1;
BA_ "SignalType" SG_ 2152128512 DSPMCA_DrvStyPrfMd3Avl "BLN";
BA_ "PacketOrder" SG_ 2152128512 DSPMCA_DrvStyPrfMd3Avl 3;
BA_ "SignalLongName" SG_ 2152128512 DSPMCA_DrvStyPrfMd3Avl "Driving Style Performance Mode Customization Available : Driving Style Performance Mode 3 Available";
BA_ "VNSigAllNodes" SG_ 2152128512 DSPMCA_DrvStyPrfMd2Avl 1;
BA_ "SignalType" SG_ 2152128512 DSPMCA_DrvStyPrfMd2Avl "BLN";
BA_ "PacketOrder" SG_ 2152128512 DSPMCA_DrvStyPrfMd2Avl 2;
BA_ "SignalLongName" SG_ 2152128512 DSPMCA_DrvStyPrfMd2Avl "Driving Style Performance Mode Customization Available : Driving Style Performance Mode 2 Available";
BA_ "VNSigAllNodes" SG_ 2152128512 DSPMCA_DrvStyPrfMd1Avl 1;
BA_ "SignalType" SG_ 2152128512 DSPMCA_DrvStyPrfMd1Avl "BLN";
BA_ "PacketOrder" SG_ 2152128512 DSPMCA_DrvStyPrfMd1Avl 1;
BA_ "SignalLongName" SG_ 2152128512 DSPMCA_DrvStyPrfMd1Avl "Driving Style Performance Mode Customization Available : Driving Style Performance Mode 1 Available";
BA_ "VNSigAllNodes" SG_ 2152128512 ACCPMCA_ACCPrfMd6Avl 1;
BA_ "SignalType" SG_ 2152128512 ACCPMCA_ACCPrfMd6Avl "BLN";
BA_ "PacketOrder" SG_ 2152128512 ACCPMCA_ACCPrfMd6Avl 6;
BA_ "SignalLongName" SG_ 2152128512 ACCPMCA_ACCPrfMd6Avl "Adaptive Cruise Control Performance Mode Customization Available : Adaptive Cruise Control Performance Mode 6 Available";
BA_ "VNSigAllNodes" SG_ 2152128512 ACCPMCA_ACCPrfMd5Avl 1;
BA_ "SignalType" SG_ 2152128512 ACCPMCA_ACCPrfMd5Avl "BLN";
BA_ "PacketOrder" SG_ 2152128512 ACCPMCA_ACCPrfMd5Avl 5;
BA_ "SignalLongName" SG_ 2152128512 ACCPMCA_ACCPrfMd5Avl "Adaptive Cruise Control Performance Mode Customization Available : Adaptive Cruise Control Performance Mode 5 Available";
BA_ "VNSigAllNodes" SG_ 2152128512 ACCPMCA_ACCPrfMd4Avl 1;
BA_ "SignalType" SG_ 2152128512 ACCPMCA_ACCPrfMd4Avl "BLN";
BA_ "PacketOrder" SG_ 2152128512 ACCPMCA_ACCPrfMd4Avl 4;
BA_ "SignalLongName" SG_ 2152128512 ACCPMCA_ACCPrfMd4Avl "Adaptive Cruise Control Performance Mode Customization Available : Adaptive Cruise Control Performance Mode 4 Available";
BA_ "VNSigAllNodes" SG_ 2152128512 ACCPMCA_ACCPrfMd3Avl 1;
BA_ "SignalType" SG_ 2152128512 ACCPMCA_ACCPrfMd3Avl "BLN";
BA_ "PacketOrder" SG_ 2152128512 ACCPMCA_ACCPrfMd3Avl 3;
BA_ "SignalLongName" SG_ 2152128512 ACCPMCA_ACCPrfMd3Avl "Adaptive Cruise Control Performance Mode Customization Available : Adaptive Cruise Control Performance Mode 3 Available";
BA_ "VNSigAllNodes" SG_ 2152128512 ACCPMCA_ACCPrfMd2Avl 1;
BA_ "SignalType" SG_ 2152128512 ACCPMCA_ACCPrfMd2Avl "BLN";
BA_ "PacketOrder" SG_ 2152128512 ACCPMCA_ACCPrfMd2Avl 2;
BA_ "SignalLongName" SG_ 2152128512 ACCPMCA_ACCPrfMd2Avl "Adaptive Cruise Control Performance Mode Customization Available : Adaptive Cruise Control Performance Mode 2 Available";
BA_ "VNSigAllNodes" SG_ 2152128512 ACCPMCA_ACCPrfMd1Avl 1;
BA_ "SignalType" SG_ 2152128512 ACCPMCA_ACCPrfMd1Avl "BLN";
BA_ "PacketOrder" SG_ 2152128512 ACCPMCA_ACCPrfMd1Avl 1;
BA_ "SignalLongName" SG_ 2152128512 ACCPMCA_ACCPrfMd1Avl "Adaptive Cruise Control Performance Mode Customization Available : Adaptive Cruise Control Performance Mode 1 Available";
BA_ "GenSigSendType" SG_ 2149924864 PTOMobModTrnsInGrIO 10;
BA_ "VNSigAllNodes" SG_ 2149924864 PTOMobModTrnsInGrIO 1;
BA_ "SignalType" SG_ 2149924864 PTOMobModTrnsInGrIO "BLN";
BA_ "SignalLongName" SG_ 2149924864 PTOMobModTrnsInGrIO "Power Take Off Mobile Mode Transmission In Gear Indication On";
BA_ "GenSigSendType" SG_ 2149924864 FwdClnMtgnBrkReqAct 10;
BA_ "VNSigAllNodes" SG_ 2149924864 FwdClnMtgnBrkReqAct 1;
BA_ "SignalType" SG_ 2149924864 FwdClnMtgnBrkReqAct "BLN";
BA_ "SignalLongName" SG_ 2149924864 FwdClnMtgnBrkReqAct "Forward Collision Mitigation Braking Request Active";
BA_ "GenSigSendType" SG_ 2149924864 TireRRLowTracIO 10;
BA_ "VNSigAllNodes" SG_ 2149924864 TireRRLowTracIO 1;
BA_ "SignalType" SG_ 2149924864 TireRRLowTracIO "BLN";
BA_ "SignalLongName" SG_ 2149924864 TireRRLowTracIO "Tire Right Rear Low Traction Indication On";
BA_ "GenSigSendType" SG_ 2149924864 TireRFLowTracIO 10;
BA_ "VNSigAllNodes" SG_ 2149924864 TireRFLowTracIO 1;
BA_ "SignalType" SG_ 2149924864 TireRFLowTracIO "BLN";
BA_ "SignalLongName" SG_ 2149924864 TireRFLowTracIO "Tire Right Front Low Traction Indication On";
BA_ "GenSigSendType" SG_ 2149924864 TireLRLowTracIO 10;
BA_ "VNSigAllNodes" SG_ 2149924864 TireLRLowTracIO 1;
BA_ "SignalType" SG_ 2149924864 TireLRLowTracIO "BLN";
BA_ "SignalLongName" SG_ 2149924864 TireLRLowTracIO "Tire Left Rear Low Traction Indication On";
BA_ "GenSigSendType" SG_ 2149924864 TireLFLowTracIO 10;
BA_ "VNSigAllNodes" SG_ 2149924864 TireLFLowTracIO 1;
BA_ "SignalType" SG_ 2149924864 TireLFLowTracIO "BLN";
BA_ "SignalLongName" SG_ 2149924864 TireLFLowTracIO "Tire Left Front Low Traction Indication On";
BA_ "GenSigSendType" SG_ 2149924864 HilRlbkCtrlActIO 10;
BA_ "VNSigAllNodes" SG_ 2149924864 HilRlbkCtrlActIO 1;
BA_ "SignalType" SG_ 2149924864 HilRlbkCtrlActIO "BLN";
BA_ "SignalLongName" SG_ 2149924864 HilRlbkCtrlActIO "Hill Rollback Control Active Indiction On";
BA_ "GenSigSendType" SG_ 2149924864 FstIdlMdAct 10;
BA_ "VNSigAllNodes" SG_ 2149924864 FstIdlMdAct 1;
BA_ "SignalType" SG_ 2149924864 FstIdlMdAct "BLN";
BA_ "SignalLongName" SG_ 2149924864 FstIdlMdAct "Fast Idle Mode Active";
BA_ "GenSigSendType" SG_ 2149924864 DsplyPerfMdRq 10;
BA_ "VNSigAllNodes" SG_ 2149924864 DsplyPerfMdRq 1;
BA_ "SignalType" SG_ 2149924864 DsplyPerfMdRq "ENM";
BA_ "SignalLongName" SG_ 2149924864 DsplyPerfMdRq "Display Performance Mode Request";
BA_ "GenSigSendType" SG_ 2149924864 DrvSelMd8Stat 10;
BA_ "VNSigAllNodes" SG_ 2149924864 DrvSelMd8Stat 1;
BA_ "SignalType" SG_ 2149924864 DrvSelMd8Stat "ENM";
BA_ "SignalLongName" SG_ 2149924864 DrvSelMd8Stat "Driver Selected Mode 8 Status";
BA_ "GenSigSendType" SG_ 2149924864 DrvSelMd8ReqDnd 10;
BA_ "VNSigAllNodes" SG_ 2149924864 DrvSelMd8ReqDnd 1;
BA_ "SignalType" SG_ 2149924864 DrvSelMd8ReqDnd "BLN";
BA_ "SignalLongName" SG_ 2149924864 DrvSelMd8ReqDnd "Driver Selected Mode 8 Request Denied";
BA_ "GenSigSendType" SG_ 2149924864 DrvSelMd7Stat 10;
BA_ "VNSigAllNodes" SG_ 2149924864 DrvSelMd7Stat 1;
BA_ "SignalType" SG_ 2149924864 DrvSelMd7Stat "ENM";
BA_ "SignalLongName" SG_ 2149924864 DrvSelMd7Stat "Driver Selected Mode 7 Status";
BA_ "GenSigSendType" SG_ 2149924864 DrvSelMd7ReqDnd 10;
BA_ "VNSigAllNodes" SG_ 2149924864 DrvSelMd7ReqDnd 1;
BA_ "SignalType" SG_ 2149924864 DrvSelMd7ReqDnd "BLN";
BA_ "SignalLongName" SG_ 2149924864 DrvSelMd7ReqDnd "Driver Selected Mode 7 Request Denied";
BA_ "GenSigSendType" SG_ 2149924864 DrvSelMd6Stat 10;
BA_ "VNSigAllNodes" SG_ 2149924864 DrvSelMd6Stat 1;
BA_ "SignalType" SG_ 2149924864 DrvSelMd6Stat "ENM";
BA_ "SignalLongName" SG_ 2149924864 DrvSelMd6Stat "Driver Selected Mode 6 Status";
BA_ "GenSigSendType" SG_ 2149924864 DrvSelMd6ReqDnd 10;
BA_ "VNSigAllNodes" SG_ 2149924864 DrvSelMd6ReqDnd 1;
BA_ "SignalType" SG_ 2149924864 DrvSelMd6ReqDnd "BLN";
BA_ "SignalLongName" SG_ 2149924864 DrvSelMd6ReqDnd "Driver Selected Mode 6 Request Denied";
BA_ "GenSigSendType" SG_ 2149924864 DrvSelMd5Stat 10;
BA_ "VNSigAllNodes" SG_ 2149924864 DrvSelMd5Stat 1;
BA_ "SignalType" SG_ 2149924864 DrvSelMd5Stat "ENM";
BA_ "SignalLongName" SG_ 2149924864 DrvSelMd5Stat "Driver Selected Mode 5 Status";
BA_ "GenSigSendType" SG_ 2149924864 DrvSelMd5ReqDnd 10;
BA_ "VNSigAllNodes" SG_ 2149924864 DrvSelMd5ReqDnd 1;
BA_ "SignalType" SG_ 2149924864 DrvSelMd5ReqDnd "BLN";
BA_ "SignalLongName" SG_ 2149924864 DrvSelMd5ReqDnd "Driver Selected Mode 5 Request Denied";
BA_ "GenSigSendType" SG_ 2149924864 DrvSelMd4Stat 10;
BA_ "VNSigAllNodes" SG_ 2149924864 DrvSelMd4Stat 1;
BA_ "SignalType" SG_ 2149924864 DrvSelMd4Stat "ENM";
BA_ "SignalLongName" SG_ 2149924864 DrvSelMd4Stat "Driver Selected Mode 4 Status";
BA_ "GenSigSendType" SG_ 2149924864 DrvSelMd4ReqDnd 10;
BA_ "VNSigAllNodes" SG_ 2149924864 DrvSelMd4ReqDnd 1;
BA_ "SignalType" SG_ 2149924864 DrvSelMd4ReqDnd "BLN";
BA_ "SignalLongName" SG_ 2149924864 DrvSelMd4ReqDnd "Driver Selected Mode 4 Request Denied";
BA_ "GenSigSendType" SG_ 2149924864 EDADS_RcmndtFwdGr 10;
BA_ "VNSigAllNodes" SG_ 2149924864 EDADS_RcmndtFwdGr 1;
BA_ "SignalType" SG_ 2149924864 EDADS_RcmndtFwdGr "ENM";
BA_ "PacketOrder" SG_ 2149924864 EDADS_RcmndtFwdGr 4;
BA_ "SignalLongName" SG_ 2149924864 EDADS_RcmndtFwdGr "ECO Drive Assist Display Status : Recommended Forward Gear";
BA_ "GenSigSendType" SG_ 2149924864 EDADS_CrntFwdMsdG 10;
BA_ "VNSigAllNodes" SG_ 2149924864 EDADS_CrntFwdMsdG 1;
BA_ "SignalType" SG_ 2149924864 EDADS_CrntFwdMsdG "ENM";
BA_ "PacketOrder" SG_ 2149924864 EDADS_CrntFwdMsdG 3;
BA_ "SignalLongName" SG_ 2149924864 EDADS_CrntFwdMsdG "ECO Drive Assist Display Status : Current Forward Measured Gear";
BA_ "GenSigSendType" SG_ 2149924864 EDADS_ShftIndStat 10;
BA_ "VNSigAllNodes" SG_ 2149924864 EDADS_ShftIndStat 1;
BA_ "SignalType" SG_ 2149924864 EDADS_ShftIndStat "ENM";
BA_ "PacketOrder" SG_ 2149924864 EDADS_ShftIndStat 2;
BA_ "SignalLongName" SG_ 2149924864 EDADS_ShftIndStat "ECO Drive Assist Display Status : Shift Indication Status";
BA_ "GenSigSendType" SG_ 2149924864 EDADS_EcoDrvShftIO 10;
BA_ "VNSigAllNodes" SG_ 2149924864 EDADS_EcoDrvShftIO 1;
BA_ "SignalType" SG_ 2149924864 EDADS_EcoDrvShftIO "BLN";
BA_ "PacketOrder" SG_ 2149924864 EDADS_EcoDrvShftIO 1;
BA_ "SignalLongName" SG_ 2149924864 EDADS_EcoDrvShftIO "ECO Drive Assist Display Status : ECO Drive Assist Shift Indication On";
BA_ "GenSigSendOnInit" SG_ 2149924864 DSMSS_DrvSelMd0Pn 1;
BA_ "GenSigSendType" SG_ 2149924864 DSMSS_DrvSelMd0Pn 10;
BA_ "VNSigAllNodes" SG_ 2149924864 DSMSS_DrvSelMd0Pn 1;
BA_ "SignalType" SG_ 2149924864 DSMSS_DrvSelMd0Pn "BLN";
BA_ "PacketOrder" SG_ 2149924864 DSMSS_DrvSelMd0Pn 17;
BA_ "SignalLongName" SG_ 2149924864 DSMSS_DrvSelMd0Pn "Driver Selected Mode Selection Status : Driver Selected Mode 0 Pending";
BA_ "GenSigSendOnInit" SG_ 2149924864 DSMSS_DrvSelMd8Pn 1;
BA_ "GenSigSendType" SG_ 2149924864 DSMSS_DrvSelMd8Pn 10;
BA_ "VNSigAllNodes" SG_ 2149924864 DSMSS_DrvSelMd8Pn 1;
BA_ "SignalType" SG_ 2149924864 DSMSS_DrvSelMd8Pn "BLN";
BA_ "PacketOrder" SG_ 2149924864 DSMSS_DrvSelMd8Pn 16;
BA_ "SignalLongName" SG_ 2149924864 DSMSS_DrvSelMd8Pn "Driver Selected Mode Selection Status : Driver Selected Mode 8 Pending";
BA_ "GenSigSendOnInit" SG_ 2149924864 DSMSS_DrvSelMd7Pn 1;
BA_ "GenSigSendType" SG_ 2149924864 DSMSS_DrvSelMd7Pn 10;
BA_ "VNSigAllNodes" SG_ 2149924864 DSMSS_DrvSelMd7Pn 1;
BA_ "SignalType" SG_ 2149924864 DSMSS_DrvSelMd7Pn "BLN";
BA_ "PacketOrder" SG_ 2149924864 DSMSS_DrvSelMd7Pn 15;
BA_ "SignalLongName" SG_ 2149924864 DSMSS_DrvSelMd7Pn "Driver Selected Mode Selection Status : Driver Selected Mode 7 Pending";
BA_ "GenSigSendOnInit" SG_ 2149924864 DSMSS_DrvSelMd6Pn 1;
BA_ "GenSigSendType" SG_ 2149924864 DSMSS_DrvSelMd6Pn 10;
BA_ "VNSigAllNodes" SG_ 2149924864 DSMSS_DrvSelMd6Pn 1;
BA_ "SignalType" SG_ 2149924864 DSMSS_DrvSelMd6Pn "BLN";
BA_ "PacketOrder" SG_ 2149924864 DSMSS_DrvSelMd6Pn 14;
BA_ "SignalLongName" SG_ 2149924864 DSMSS_DrvSelMd6Pn "Driver Selected Mode Selection Status : Driver Selected Mode 6 Pending";
BA_ "GenSigSendOnInit" SG_ 2149924864 DSMSS_DrvSelMd5Pn 1;
BA_ "GenSigSendType" SG_ 2149924864 DSMSS_DrvSelMd5Pn 10;
BA_ "VNSigAllNodes" SG_ 2149924864 DSMSS_DrvSelMd5Pn 1;
BA_ "SignalType" SG_ 2149924864 DSMSS_DrvSelMd5Pn "BLN";
BA_ "PacketOrder" SG_ 2149924864 DSMSS_DrvSelMd5Pn 13;
BA_ "SignalLongName" SG_ 2149924864 DSMSS_DrvSelMd5Pn "Driver Selected Mode Selection Status : Driver Selected Mode 5 Pending";
BA_ "GenSigSendOnInit" SG_ 2149924864 DSMSS_DrvSelMd4Pn 1;
BA_ "GenSigSendType" SG_ 2149924864 DSMSS_DrvSelMd4Pn 10;
BA_ "VNSigAllNodes" SG_ 2149924864 DSMSS_DrvSelMd4Pn 1;
BA_ "SignalType" SG_ 2149924864 DSMSS_DrvSelMd4Pn "BLN";
BA_ "PacketOrder" SG_ 2149924864 DSMSS_DrvSelMd4Pn 12;
BA_ "SignalLongName" SG_ 2149924864 DSMSS_DrvSelMd4Pn "Driver Selected Mode Selection Status : Driver Selected Mode 4 Pending";
BA_ "GenSigSendOnInit" SG_ 2149924864 DSMSS_DrvSelMd3Pn 1;
BA_ "GenSigSendType" SG_ 2149924864 DSMSS_DrvSelMd3Pn 10;
BA_ "VNSigAllNodes" SG_ 2149924864 DSMSS_DrvSelMd3Pn 1;
BA_ "SignalType" SG_ 2149924864 DSMSS_DrvSelMd3Pn "BLN";
BA_ "PacketOrder" SG_ 2149924864 DSMSS_DrvSelMd3Pn 11;
BA_ "SignalLongName" SG_ 2149924864 DSMSS_DrvSelMd3Pn "Driver Selected Mode Selection Status : Driver Selected Mode 3 Pending";
BA_ "GenSigSendOnInit" SG_ 2149924864 DSMSS_DrvSelMd2Pn 1;
BA_ "GenSigSendType" SG_ 2149924864 DSMSS_DrvSelMd2Pn 10;
BA_ "VNSigAllNodes" SG_ 2149924864 DSMSS_DrvSelMd2Pn 1;
BA_ "SignalType" SG_ 2149924864 DSMSS_DrvSelMd2Pn "BLN";
BA_ "PacketOrder" SG_ 2149924864 DSMSS_DrvSelMd2Pn 10;
BA_ "SignalLongName" SG_ 2149924864 DSMSS_DrvSelMd2Pn "Driver Selected Mode Selection Status : Driver Selected Mode 2 Pending";
BA_ "GenSigSendOnInit" SG_ 2149924864 DSMSS_DrvSelMd1Pn 1;
BA_ "GenSigSendType" SG_ 2149924864 DSMSS_DrvSelMd1Pn 10;
BA_ "VNSigAllNodes" SG_ 2149924864 DSMSS_DrvSelMd1Pn 1;
BA_ "SignalType" SG_ 2149924864 DSMSS_DrvSelMd1Pn "BLN";
BA_ "PacketOrder" SG_ 2149924864 DSMSS_DrvSelMd1Pn 9;
BA_ "SignalLongName" SG_ 2149924864 DSMSS_DrvSelMd1Pn "Driver Selected Mode Selection Status : Driver Selected Mode 1 Pending";
BA_ "GenSigSendOnInit" SG_ 2149924864 DSMSS_DrvSelMd8Un 1;
BA_ "GenSigSendType" SG_ 2149924864 DSMSS_DrvSelMd8Un 10;
BA_ "VNSigAllNodes" SG_ 2149924864 DSMSS_DrvSelMd8Un 1;
BA_ "SignalType" SG_ 2149924864 DSMSS_DrvSelMd8Un "BLN";
BA_ "PacketOrder" SG_ 2149924864 DSMSS_DrvSelMd8Un 8;
BA_ "SignalLongName" SG_ 2149924864 DSMSS_DrvSelMd8Un "Driver Selected Mode Selection Status : Driver Selected Mode 8 Unavailable";
BA_ "GenSigSendOnInit" SG_ 2149924864 DSMSS_DrvSelMd7Un 1;
BA_ "GenSigSendType" SG_ 2149924864 DSMSS_DrvSelMd7Un 10;
BA_ "VNSigAllNodes" SG_ 2149924864 DSMSS_DrvSelMd7Un 1;
BA_ "SignalType" SG_ 2149924864 DSMSS_DrvSelMd7Un "BLN";
BA_ "PacketOrder" SG_ 2149924864 DSMSS_DrvSelMd7Un 7;
BA_ "SignalLongName" SG_ 2149924864 DSMSS_DrvSelMd7Un "Driver Selected Mode Selection Status : Driver Selected Mode 7 Unavailable";
BA_ "GenSigSendOnInit" SG_ 2149924864 DSMSS_DrvSelMd6Un 1;
BA_ "GenSigSendType" SG_ 2149924864 DSMSS_DrvSelMd6Un 10;
BA_ "VNSigAllNodes" SG_ 2149924864 DSMSS_DrvSelMd6Un 1;
BA_ "SignalType" SG_ 2149924864 DSMSS_DrvSelMd6Un "BLN";
BA_ "PacketOrder" SG_ 2149924864 DSMSS_DrvSelMd6Un 6;
BA_ "SignalLongName" SG_ 2149924864 DSMSS_DrvSelMd6Un "Driver Selected Mode Selection Status : Driver Selected Mode 6 Unavailable";
BA_ "GenSigSendOnInit" SG_ 2149924864 DSMSS_DrvSelMd5Un 1;
BA_ "GenSigSendType" SG_ 2149924864 DSMSS_DrvSelMd5Un 10;
BA_ "VNSigAllNodes" SG_ 2149924864 DSMSS_DrvSelMd5Un 1;
BA_ "SignalType" SG_ 2149924864 DSMSS_DrvSelMd5Un "BLN";
BA_ "PacketOrder" SG_ 2149924864 DSMSS_DrvSelMd5Un 5;
BA_ "SignalLongName" SG_ 2149924864 DSMSS_DrvSelMd5Un "Driver Selected Mode Selection Status : Driver Selected Mode 5 Unavailable";
BA_ "GenSigSendOnInit" SG_ 2149924864 DSMSS_DrvSelMd4Un 1;
BA_ "GenSigSendType" SG_ 2149924864 DSMSS_DrvSelMd4Un 10;
BA_ "VNSigAllNodes" SG_ 2149924864 DSMSS_DrvSelMd4Un 1;
BA_ "SignalType" SG_ 2149924864 DSMSS_DrvSelMd4Un "BLN";
BA_ "PacketOrder" SG_ 2149924864 DSMSS_DrvSelMd4Un 4;
BA_ "SignalLongName" SG_ 2149924864 DSMSS_DrvSelMd4Un "Driver Selected Mode Selection Status : Driver Selected Mode 4 Unavailable";
BA_ "GenSigSendOnInit" SG_ 2149924864 DSMSS_DrvSelMd3Un 1;
BA_ "GenSigSendType" SG_ 2149924864 DSMSS_DrvSelMd3Un 10;
BA_ "VNSigAllNodes" SG_ 2149924864 DSMSS_DrvSelMd3Un 1;
BA_ "SignalType" SG_ 2149924864 DSMSS_DrvSelMd3Un "BLN";
BA_ "PacketOrder" SG_ 2149924864 DSMSS_DrvSelMd3Un 3;
BA_ "SignalLongName" SG_ 2149924864 DSMSS_DrvSelMd3Un "Driver Selected Mode Selection Status : Driver Selected Mode 3 Unavailable";
BA_ "GenSigSendOnInit" SG_ 2149924864 DSMSS_DrvSelMd2Un 1;
BA_ "GenSigSendType" SG_ 2149924864 DSMSS_DrvSelMd2Un 10;
BA_ "VNSigAllNodes" SG_ 2149924864 DSMSS_DrvSelMd2Un 1;
BA_ "SignalType" SG_ 2149924864 DSMSS_DrvSelMd2Un "BLN";
BA_ "PacketOrder" SG_ 2149924864 DSMSS_DrvSelMd2Un 2;
BA_ "SignalLongName" SG_ 2149924864 DSMSS_DrvSelMd2Un "Driver Selected Mode Selection Status : Driver Selected Mode 2 Unavailable";
BA_ "GenSigSendOnInit" SG_ 2149924864 DSMSS_DrvSelMd1Un 1;
BA_ "GenSigSendType" SG_ 2149924864 DSMSS_DrvSelMd1Un 10;
BA_ "VNSigAllNodes" SG_ 2149924864 DSMSS_DrvSelMd1Un 1;
BA_ "SignalType" SG_ 2149924864 DSMSS_DrvSelMd1Un "BLN";
BA_ "PacketOrder" SG_ 2149924864 DSMSS_DrvSelMd1Un 1;
BA_ "SignalLongName" SG_ 2149924864 DSMSS_DrvSelMd1Un "Driver Selected Mode Selection Status : Driver Selected Mode 1 Unavailable";
BA_ "GenSigSendOnInit" SG_ 2149924864 DrvSelMd3Stat 1;
BA_ "GenSigSendType" SG_ 2149924864 DrvSelMd3Stat 10;
BA_ "VNSigAllNodes" SG_ 2149924864 DrvSelMd3Stat 1;
BA_ "SignalType" SG_ 2149924864 DrvSelMd3Stat "ENM";
BA_ "SignalLongName" SG_ 2149924864 DrvSelMd3Stat "Driver Selected Mode 3 Status";
BA_ "GenSigSendType" SG_ 2149924864 DrvSelMd3ReqDnd 10;
BA_ "VNSigAllNodes" SG_ 2149924864 DrvSelMd3ReqDnd 1;
BA_ "SignalType" SG_ 2149924864 DrvSelMd3ReqDnd "BLN";
BA_ "SignalLongName" SG_ 2149924864 DrvSelMd3ReqDnd "Driver Selected Mode 3 Request Denied";
BA_ "GenSigSendOnInit" SG_ 2149924864 DrvSelMd2Stat 1;
BA_ "GenSigSendType" SG_ 2149924864 DrvSelMd2Stat 10;
BA_ "VNSigAllNodes" SG_ 2149924864 DrvSelMd2Stat 1;
BA_ "SignalType" SG_ 2149924864 DrvSelMd2Stat "ENM";
BA_ "SignalLongName" SG_ 2149924864 DrvSelMd2Stat "Driver Selected Mode 2 Status";
BA_ "GenSigSendType" SG_ 2149924864 DrvSelMd2ReqDnd 10;
BA_ "VNSigAllNodes" SG_ 2149924864 DrvSelMd2ReqDnd 1;
BA_ "SignalType" SG_ 2149924864 DrvSelMd2ReqDnd "BLN";
BA_ "SignalLongName" SG_ 2149924864 DrvSelMd2ReqDnd "Driver Selected Mode 2 Request Denied";
BA_ "GenSigSendOnInit" SG_ 2149924864 DrvSelMd1Stat 1;
BA_ "GenSigSendType" SG_ 2149924864 DrvSelMd1Stat 10;
BA_ "VNSigAllNodes" SG_ 2149924864 DrvSelMd1Stat 1;
BA_ "SignalType" SG_ 2149924864 DrvSelMd1Stat "ENM";
BA_ "SignalLongName" SG_ 2149924864 DrvSelMd1Stat "Driver Selected Mode 1 Status";
BA_ "GenSigSendType" SG_ 2149924864 DrvSelMd1ReqDnd 10;
BA_ "VNSigAllNodes" SG_ 2149924864 DrvSelMd1ReqDnd 1;
BA_ "SignalType" SG_ 2149924864 DrvSelMd1ReqDnd "BLN";
BA_ "SignalLongName" SG_ 2149924864 DrvSelMd1ReqDnd "Driver Selected Mode 1 Request Denied";
BA_ "GenSigSendOnInit" SG_ 2149924864 CPSCA_Resrv3Avail 1;
BA_ "GenSigSendType" SG_ 2149924864 CPSCA_Resrv3Avail 10;
BA_ "VNSigAllNodes" SG_ 2149924864 CPSCA_Resrv3Avail 1;
BA_ "SignalType" SG_ 2149924864 CPSCA_Resrv3Avail "BLN";
BA_ "PacketOrder" SG_ 2149924864 CPSCA_Resrv3Avail 7;
BA_ "SignalLongName" SG_ 2149924864 CPSCA_Resrv3Avail "Collision Preparation System Customization Available : Reserved3 Available";
BA_ "GenSigSendOnInit" SG_ 2149924864 CPSCA_Resrv2Avail 1;
BA_ "GenSigSendType" SG_ 2149924864 CPSCA_Resrv2Avail 10;
BA_ "VNSigAllNodes" SG_ 2149924864 CPSCA_Resrv2Avail 1;
BA_ "SignalType" SG_ 2149924864 CPSCA_Resrv2Avail "BLN";
BA_ "PacketOrder" SG_ 2149924864 CPSCA_Resrv2Avail 6;
BA_ "SignalLongName" SG_ 2149924864 CPSCA_Resrv2Avail "Collision Preparation System Customization Available : Reserved2 Available";
BA_ "GenSigSendOnInit" SG_ 2149924864 CPSCA_Resrv1Avail 1;
BA_ "GenSigSendType" SG_ 2149924864 CPSCA_Resrv1Avail 10;
BA_ "VNSigAllNodes" SG_ 2149924864 CPSCA_Resrv1Avail 1;
BA_ "SignalType" SG_ 2149924864 CPSCA_Resrv1Avail "BLN";
BA_ "PacketOrder" SG_ 2149924864 CPSCA_Resrv1Avail 5;
BA_ "SignalLongName" SG_ 2149924864 CPSCA_Resrv1Avail "Collision Preparation System Customization Available : Reserved1 Available";
BA_ "GenSigSendOnInit" SG_ 2149924864 CPSCA_AlrtBrkStrAvail 1;
BA_ "GenSigSendType" SG_ 2149924864 CPSCA_AlrtBrkStrAvail 10;
BA_ "VNSigAllNodes" SG_ 2149924864 CPSCA_AlrtBrkStrAvail 1;
BA_ "SignalType" SG_ 2149924864 CPSCA_AlrtBrkStrAvail "BLN";
BA_ "PacketOrder" SG_ 2149924864 CPSCA_AlrtBrkStrAvail 4;
BA_ "SignalLongName" SG_ 2149924864 CPSCA_AlrtBrkStrAvail "Collision Preparation System Customization Available : Alert and Brake and Steer Available";
BA_ "GenSigSendOnInit" SG_ 2149924864 CPSCA_AlrtBrkAvail 1;
BA_ "GenSigSendType" SG_ 2149924864 CPSCA_AlrtBrkAvail 10;
BA_ "VNSigAllNodes" SG_ 2149924864 CPSCA_AlrtBrkAvail 1;
BA_ "SignalType" SG_ 2149924864 CPSCA_AlrtBrkAvail "BLN";
BA_ "PacketOrder" SG_ 2149924864 CPSCA_AlrtBrkAvail 3;
BA_ "SignalLongName" SG_ 2149924864 CPSCA_AlrtBrkAvail "Collision Preparation System Customization Available : Alert and Brake Available";
BA_ "GenSigStartValue" SG_ 2149924864 CPSCA_AlrtBrkAvail 1;
BA_ "GenSigSendOnInit" SG_ 2149924864 CPSCA_AlrtAvail 1;
BA_ "GenSigSendType" SG_ 2149924864 CPSCA_AlrtAvail 10;
BA_ "VNSigAllNodes" SG_ 2149924864 CPSCA_AlrtAvail 1;
BA_ "SignalType" SG_ 2149924864 CPSCA_AlrtAvail "BLN";
BA_ "PacketOrder" SG_ 2149924864 CPSCA_AlrtAvail 2;
BA_ "SignalLongName" SG_ 2149924864 CPSCA_AlrtAvail "Collision Preparation System Customization Available : Alert Available";
BA_ "GenSigStartValue" SG_ 2149924864 CPSCA_AlrtAvail 1;
BA_ "GenSigSendOnInit" SG_ 2149924864 CPSCA_OffAvail 1;
BA_ "GenSigSendType" SG_ 2149924864 CPSCA_OffAvail 10;
BA_ "VNSigAllNodes" SG_ 2149924864 CPSCA_OffAvail 1;
BA_ "SignalType" SG_ 2149924864 CPSCA_OffAvail "BLN";
BA_ "PacketOrder" SG_ 2149924864 CPSCA_OffAvail 1;
BA_ "SignalLongName" SG_ 2149924864 CPSCA_OffAvail "Collision Preparation System Customization Available : Off Available";
BA_ "GenSigStartValue" SG_ 2149924864 CPSCA_OffAvail 1;
BA_ "GenSigSendType" SG_ 2149924864 a_12VBatSysUnstab 10;
BA_ "VNSigAllNodes" SG_ 2149924864 a_12VBatSysUnstab 1;
BA_ "SignalType" SG_ 2149924864 a_12VBatSysUnstab "BLN";
BA_ "SignalLongName" SG_ 2149924864 a_12VBatSysUnstab "12 Volt Battery System Unstable";
BA_ "GenSigSendType" SG_ 2150301696 WlcAnmReq 10;
BA_ "VNSigAllNodes" SG_ 2150301696 WlcAnmReq 1;
BA_ "SignalType" SG_ 2150301696 WlcAnmReq "BLN";
BA_ "SignalLongName" SG_ 2150301696 WlcAnmReq "Welcome Animation Request";
BA_ "GenSigSendType" SG_ 2154856448 HmdtySnsrTemp 12;
BA_ "GenSigDeltaValue" SG_ 2154856448 HmdtySnsrTemp 1;
BA_ "VNSigAllNodes" SG_ 2154856448 HmdtySnsrTemp 1;
BA_ "SignalType" SG_ 2154856448 HmdtySnsrTemp "UNM";
BA_ "SignalLongName" SG_ 2154856448 HmdtySnsrTemp "Humidity Sensor Temperature";
BA_ "GenSigSendType" SG_ 2154856448 HmdtySnsrRltvHmdty 12;
BA_ "GenSigDeltaValue" SG_ 2154856448 HmdtySnsrRltvHmdty 1;
BA_ "VNSigAllNodes" SG_ 2154856448 HmdtySnsrRltvHmdty 1;
BA_ "SignalType" SG_ 2154856448 HmdtySnsrRltvHmdty "UNM";
BA_ "SignalLongName" SG_ 2154856448 HmdtySnsrRltvHmdty "Humidity Sensor Relative Humidity";
BA_ "GenSigSendType" SG_ 2154856448 HmdtySnsrGlssTemp 12;
BA_ "GenSigDeltaValue" SG_ 2154856448 HmdtySnsrGlssTemp 1;
BA_ "VNSigAllNodes" SG_ 2154856448 HmdtySnsrGlssTemp 1;
BA_ "SignalType" SG_ 2154856448 HmdtySnsrGlssTemp "UNM";
BA_ "SignalLongName" SG_ 2154856448 HmdtySnsrGlssTemp "Humidity Sensor Glass Temperature";
BA_REL_ "GenSigSuprvResp" BU_SG_REL_ ECC_LS SG_ 2153381888 PwrLftgtMotStat 1;
BA_REL_ "GenSigSuprvResp" BU_SG_REL_ BCM_LS SG_ 2153381888 RrClosOpenSwAct 1;
BA_REL_ "GenSigVBitResp" BU_SG_REL_ BCM_LS SG_ 2153381888 RrClosOpenSwAct 1;
BA_REL_ "GenSigSuprvResp" BU_SG_REL_ BCM_LS SG_ 2153381888 RrClsrInMtn 1;
BA_REL_ "GenSigSuprvResp" BU_SG_REL_ VIS2_LS SG_ 2150268928 CldrYr_154 1;
BA_REL_ "GenSigSuprvResp" BU_SG_REL_ EOCM_F_LS SG_ 2150268928 CldrYr_154 1;
BA_REL_ "GenSigSuprvResp" BU_SG_REL_ BCM_LS SG_ 2150268928 CldrYr_154 1;
BA_REL_ "GenSigSuprvResp" BU_SG_REL_ VIS2_LS SG_ 2150268928 CldrMth_154 1;
BA_REL_ "GenSigSuprvResp" BU_SG_REL_ EOCM_F_LS SG_ 2150268928 CldrMth_154 1;
BA_REL_ "GenSigSuprvResp" BU_SG_REL_ BCM_LS SG_ 2150268928 CldrMth_154 1;
BA_REL_ "GenSigSuprvResp" BU_SG_REL_ VIS2_LS SG_ 2150268928 CldrDay_154 1;
BA_REL_ "GenSigSuprvResp" BU_SG_REL_ EOCM_F_LS SG_ 2150268928 CldrDay_154 1;
BA_REL_ "GenSigSuprvResp" BU_SG_REL_ BCM_LS SG_ 2150268928 CldrDay_154 1;
BA_REL_ "GenSigSuprvResp" BU_SG_REL_ EOCM_F_LS SG_ 2150268928 Sec 1;
BA_REL_ "GenSigSuprvResp" BU_SG_REL_ BCM_LS SG_ 2150268928 Sec 1;
BA_REL_ "GenSigSuprvResp" BU_SG_REL_ EOCM_F_LS SG_ 2150268928 Mins 1;
BA_REL_ "GenSigSuprvResp" BU_SG_REL_ BCM_LS SG_ 2150268928 Mins 1;
BA_REL_ "GenSigSuprvResp" BU_SG_REL_ EOCM_F_LS SG_ 2150268928 Hrs 1;
BA_REL_ "GenSigSuprvResp" BU_SG_REL_ BCM_LS SG_ 2150268928 Hrs 1;
BA_REL_ "GenSigSuprvResp" BU_SG_REL_ EOCM_F_LS SG_ 2156175360 DispMeasSys 1;
BA_REL_ "GenSigSuprvResp" BU_SG_REL_ BCM_LS SG_ 2156175360 DispMeasSys 1;
BA_REL_ "GenSigSuprvResp" BU_SG_REL_ BCM_LS SG_ 2155036672 ACCompModReq 1;
BA_REL_ "GenSigSuprvResp" BU_SG_REL_ BCM_LS SG_ 2155036672 ACCompNormLd 1;
BA_REL_ "GenSigVBitResp" BU_SG_REL_ BCM_LS SG_ 2155036672 ACCompNormLd 1;
BA_REL_ "GenSigSuprvResp" BU_SG_REL_ BCM_LS SG_ 2151186432 CtLghtDet 1;
BA_REL_ "GenSigSuprvResp" BU_SG_REL_ BCM_LS SG_ 2151186432 AutoBmSlctStat 1;
BA_REL_ "GenSigSuprvResp" BU_SG_REL_ ECC_LS SG_ 2154602496 EHCCT_EHtrCrOutClntTmp 1;
BA_REL_ "GenSigSuprvResp" BU_SG_REL_ ECC_LS SG_ 2154602496 EHCCT_EHtrCrInClntTmp 1;
BA_REL_ "GenSigSuprvResp" BU_SG_REL_ ECC_LS SG_ 2154602496 EHCCT_EHtrCrOutClntTmpV 1;
BA_REL_ "GenSigSuprvResp" BU_SG_REL_ ECC_LS SG_ 2154602496 EHCCT_EHtrCrInClntTmpV 1;
BA_REL_ "GenSigSuprvResp" BU_SG_REL_ ECC_LS SG_ 2154602496 EstHtrCrClntFlwrtFdbk 1;
BA_REL_ "GenSigSuprvResp" BU_SG_REL_ ECC_LS SG_ 2154725376 AuxHtrAtv378 1;
BA_REL_ "GenSigSuprvResp" BU_SG_REL_ ECC_LS SG_ 2154725376 AuxHtrRq 1;
BA_REL_ "GenSigSuprvResp" BU_SG_REL_ CGM_LS SG_ 2151931904 VehStbCmptvMdCstAvl 1;
BA_REL_ "GenSigSuprvResp" BU_SG_REL_ CGM_LS SG_ 2151931904 VehStbCmptvMdCurSt 1;
BA_REL_ "GenSigSuprvResp" BU_SG_REL_ CGM_LS SG_ 2151915520 ElcShfPriTwoGrsSlInRq 1;
BA_REL_ "GenSigSuprvResp" BU_SG_REL_ CGM_LS SG_ 2151915520 ESPTransMalfIO 1;
BA_REL_ "GenSigSuprvResp" BU_SG_REL_ VIS2_LS SG_ 2150449152 SpdLmtrSttngTypAct 1;
BA_REL_ "GenSigSuprvResp" BU_SG_REL_ MSM_LS SG_ 2149810176 FCAHptcStVbnRqSeqN 1;
BA_REL_ "GenSigSuprvResp" BU_SG_REL_ MSM_LS SG_ 2149810176 FCAHptcStVbnReq 1;
BA_REL_ "GenSigSuprvResp" BU_SG_REL_ ECC_LS SG_ 2149924864 DrvSelMd8Stat 1;
BA_REL_ "GenSigSuprvResp" BU_SG_REL_ ECC_LS SG_ 2149924864 DrvSelMd7Stat 1;
BA_REL_ "GenSigSuprvResp" BU_SG_REL_ ECC_LS SG_ 2149924864 DrvSelMd6Stat 1;
BA_REL_ "GenSigSuprvResp" BU_SG_REL_ ECC_LS SG_ 2149924864 DrvSelMd5Stat 1;
BA_REL_ "GenSigSuprvResp" BU_SG_REL_ ECC_LS SG_ 2149924864 DrvSelMd4Stat 1;
BA_REL_ "GenSigSuprvResp" BU_SG_REL_ ECC_LS SG_ 2149924864 DrvSelMd3Stat 1;
BA_REL_ "GenSigSuprvResp" BU_SG_REL_ ECC_LS SG_ 2149924864 DrvSelMd2Stat 1;
BA_REL_ "GenSigSuprvResp" BU_SG_REL_ ECC_LS SG_ 2149924864 DrvSelMd1Stat 1;
BA_REL_ "GenSigSuprvResp" BU_SG_REL_ BSM_LS SG_ 2154856448 HmdtySnsrTemp 1;
BA_REL_ "GenSigSuprvResp" BU_SG_REL_ BSM_LS SG_ 2154856448 HmdtySnsrRltvHmdty 1;
VAL_ 2153381888 VltActRrAccUnavlIO 1 "true" 0 "false" ;
VAL_ 2153381888 PwrLftgtMotStat 0 "Unknown" 1 "Full open" 2 "Closed" 3 "Opening" 4 "Closing" 5 "Stopped" ;
VAL_ 2153381888 PwrLftgtInclAngV 1 "Invalid" 0 "Valid" ;
VAL_ 2153381888 FnshRrClsrMtnBfrDrvIO 1 "true" 0 "false" ;
VAL_ 2153381888 GrgPrgMdCmpl 1 "true" 0 "false" ;
VAL_ 2153381888 RrClsrObstclDtctd 1 "true" 0 "false" ;
VAL_ 2153381888 RrClosOpenSwAct 1 "true" 0 "false" ;
VAL_ 2153381888 RrClosOpenSwActV 1 "Invalid" 0 "Valid" ;
VAL_ 2153381888 RrClsrInMtn 1 "true" 0 "false" ;
VAL_ 2153381888 RrWprInhbRq 1 "true" 0 "false" ;
VAL_ 2151514112 EngOilLfRstRq 1 "true" 0 "false" ;
VAL_ 2151153664 RrWndDfgOn 1 "true" 0 "false" ;
VAL_ 2151874560 RstVTDTmprDtctd 1 "Reset" 0 "No Action" ;
VAL_ 2151874560 RstIllDrIdDevDtctd 1 "Reset" 0 "No Action" ;
VAL_ 2151874560 RstDrIdDevLrnd 1 "Reset" 0 "No Action" ;
VAL_ 2151874560 ESEIC_EngImmbRq 1 "Immobilize" 0 "Do Not Immobilize" ;
VAL_ 2150268928 EmrgncyRspSysTyp 7 "Ununsed and Reserved 1" 6 "Generic" 5 "ERA" 4 "ChevyStar" 3 "eCall" 2 "Onstar" 1 "None" 0 "Unknown" ;
VAL_ 2150268928 EmrgncyRspSysSrvIndOn 1 "true" 0 "false" ;
VAL_ 2150268928 CldrMth_154 1 "January" 0 "Unknown" 12 "December" 11 "November" 10 "October" 9 "September" 8 "August" 7 "July" 6 "June" 5 "May" 4 "April" 3 "March" 2 "February" ;
VAL_ 2150268928 SecV 1 "Invalid" 0 "Valid" ;
VAL_ 2150268928 MinsV 1 "Invalid" 0 "Valid" ;
VAL_ 2150268928 HrsV 1 "Invalid" 0 "Valid" ;
VAL_ 2156175360 DispMeasSys 1 "English" 0 "Metric" ;
VAL_ 2156175360 NtVsnSysEnbld 1 "true" 0 "false" ;
VAL_ 2156175360 DispMeasSysExt 2 "Imperial" 1 "US" 0 "Metric" ;
VAL_ 2155036672 ACCompModReq 3 "No Action" 2 "Engage" 1 "Disengage" 0 "Disengage Immediately" ;
VAL_ 2155036672 ACCompNormLdV 1 "Invalid" 0 "Valid" ;
VAL_ 2155036672 ACCmEngRunReq 1 "Engine Run Requested" 0 "No Action" ;
VAL_ 2155036672 ACCmpsrFldOn 1 "true" 0 "false" ;
VAL_ 2151186432 CtLghtDet 1 "true" 0 "false" ;
VAL_ 2151186432 AutoBmSlctStat 2 "High Beam" 1 "Low  Beam" 0 "Disabled" ;
VAL_ 2152062976 ThrmlRefCompStatFdbck 3 "Invalid" 2 "Inoperative" 1 "Degraded Operation" 0 "Normal Operation" ;
VAL_ 2153406464 RrClsrInrAjrSwAct 1 "true" 0 "false" ;
VAL_ 2153406464 TlgtUnavlbleIO 1 "true" 0 "false" ;
VAL_ 2154602496 EHCCT_EHtrCrOutClntTmpV 1 "Invalid" 0 "Valid" ;
VAL_ 2154602496 EHCCT_EHtrCrInClntTmpV 1 "Invalid" 0 "Valid" ;
VAL_ 2154602496 EstHtrCrClntFlwrtFdbkV 1 "Invalid" 0 "Valid" ;
VAL_ 2154602496 CCFrBlwFnSpdFbkRatV 1 "Invalid" 0 "Valid" ;
VAL_ 2153906176 BrkSysVTopSpdLimIO 1 "true" 0 "false" ;
VAL_ 2153906176 TDLKARptCrdDspDtAvail 1 "true" 0 "false" ;
VAL_ 2153906176 TDODDRptCrdDspDtAvail 1 "true" 0 "false" ;
VAL_ 2153906176 TDUDDRptCrdDspDtAvail 1 "true" 0 "false" ;
VAL_ 2155978752 BrkPdLfRrCnfrmReplcmntIO 1 "true" 0 "false" ;
VAL_ 2155978752 BrkPdLfFrtCnfrmReplcmntIO 1 "true" 0 "false" ;
VAL_ 2155978752 ABSActIO 1 "true" 0 "false" ;
VAL_ 2155978752 CrwlModeDndRsnIndReq 4 "Reduce Speed" 3 "Shift To 4 High" 2 "Brakes Overtemp" 1 "Unavailable" 0 "No Action" ;
VAL_ 2155978752 BrkPdLfRrDstWrnIndRq 2 "Display Distance" 1 "Low" 0 "No Action" ;
VAL_ 2155978752 BrkPdLfFrtDstWrnIndRq 2 "Display Distance" 1 "Low" 0 "No Action" ;
VAL_ 2155978752 BrkPdLfRrRstAvail 1 "true" 0 "false" ;
VAL_ 2155978752 BrkPdLfFrtRstAvail 1 "true" 0 "false" ;
VAL_ 2155978752 BrkPdLfRrV 1 "Invalid" 0 "Valid" ;
VAL_ 2155978752 BrkPdLfFrtV 1 "Invalid" 0 "Valid" ;
VAL_ 2155978752 BrkPdLfStatIndRq 5 "Service" 4 "Disabled" 3 "Change Now" 2 "Change Soon" 1 "Ok" 0 "Not Present" ;
VAL_ 2155978752 EngAirFltMonSt 7 "Unused and Reserved 3" 6 "Unused and Reserved 2" 5 "Unused and Reserved 1" 4 "Disabled" 3 "Fault Present" 2 "Replace Air Filter Now" 1 "Replace Air Filter Soon" 0 "Ok" ;
VAL_ 2150236160 UlckKyStrCrptoDt2M 1 "Use Data" 0 "Dont Use Data" ;
VAL_ 2150170624 UlckKyStrCrptoDt1M 1 "Use Data" 0 "Dont Use Data" ;
VAL_ 2154725376 AuxHtrAtv378 1 "true" 0 "false" ;
VAL_ 2154725376 AuxHtrRq 1 "On" 0 "Off" ;
VAL_ 2151931904 FourWhlDrvIdReqExtRng 15 "Front Wheel Drive Mode Active" 14 "Front Wheel Drive Mode Pending" 13 "AWD Connected Mode Active" 12 "AWD Connected Mode Pending" 11 "Position Undetermined Active" 10 "Transfer Case Neutral Active" 9 "Transfer Case Neutral Pending" 8 "Four Wheel Drive Low Lock Active" 7 "Four Wheel Drive Low Lock Pending" 6 "Four Wheel Drive High Lock Active" 5 "Four Wheel Drive High Lock Pending" 4 "Four Wheel Drive High Auto Active" 3 "Four Wheel Drive High Auto Pending" 2 "Two Wheel Drive High Active" 1 "Two Wheel Drive High Pending" 0 "No Indication" ;
VAL_ 2151931904 FuelMdTrnstnIndReq 15 "Unused and Reserved 9" 14 "Unused and Reserved 8" 13 "Unused and Reserved 7" 12 "Unused and Reserved 6" 11 "Unused and Reserved 5" 10 "Unused and Reserved 4" 9 "Unused and Reserved 3" 8 "Unused and Reserved 2" 7 "Unused and Reserved 1" 6 "Indication 6" 5 "Indication 5" 4 "Indication 4" 3 "Indication 3" 2 "Indication 2" ;
VAL_ 2151931904 BiFuelRflGaslinIndReq 7 "Unused and Reserved 5" 6 "Unused and Reserved 4" 5 "Unused and Reserved 3" 4 "Unused and Reserved 2" 3 "Unused and Reserved 1" 2 "Indication 2" ;
VAL_ 2151931904 TCSTempDsblReqIO 0 "false" 1 "true" ;
VAL_ 2151931904 VehStbCmptvMdCstAvl 1 "true" 0 "false" ;
VAL_ 2151931904 VehStbEnmntCstAvl 1 "true" 0 "false" ;
VAL_ 2151931904 TCSysCstAvl 1 "true" 0 "false" ;
VAL_ 2151931904 VehStbCmptvMdCurSt 1 "On" 0 "Off" ;
VAL_ 2151931904 VehStbEnhmntCurSt 1 "On" 0 "Off" ;
VAL_ 2151931904 TCSysCurSt 1 "On" 0 "Off" ;
VAL_ 2151931904 TracAndStbScrnCnfg 3 "TCS ESC and Comp" 2 "TCS and ESC" 1 "TCS Only" 0 "None" ;
VAL_ 2151931904 ElctShfPriLtdPerfMdIO 1 "true" 0 "false" ;
VAL_ 2151931904 LnchCtrlWhlSlpStat 31 "Unused and Reserved 10" 30 "Unused and Reserved 9" 29 "Unused and Reserved 8" 28 "Unused and Reserved 7" 27 "Unused and Reserved 6" 26 "Unused and Reserved 5" 25 "Unused and Reserved 4" 24 "Unused and Reserved 3" 23 "Unused and Reserved 2" 22 "Unused and Reserved 1" 21 "Fifteen Percent" 20 "Fourteen And A Half Percent" 19 "Fourteen Percent" 18 "Thirteen And A Half Percent" 17 "Thirteen Percent" 16 "Twelve And A Half Percent" 15 "Twelve Percent" 14 "Eleven And a Half Percent" 13 "Eleven Percent" 12 "Ten And A Half Percent" 11 "Ten Percent" 10 "Nine And A Half Percent" 9 "Nine Percent" 8 "Eight And A Half Percent" 7 "Eight Percent" 6 "Seven And A Half Percent" 5 "Seven Percent" 4 "Six And A Half Percent" 3 "Six Percent" 2 "Five And A Half Percent" 1 "Five Percent" 0 "No Action" ;
VAL_ 2151931904 LnchCtrlMdStat 7 "Line Lock Release Brake" 6 "Line Lock Press Brake" 5 "Burn Out Or Line Lock" 4 "High Traction Custom" 3 "High Traction" 2 "General Custom" 1 "General" 0 "Disable" ;
VAL_ 2151931904 LnchCtrlEngRPMStat 0 "No Action" 63 "Unused and Reserved 30" 62 "Unused and Reserved 29" 61 "Unused and Reserved 28" 60 "Unused and Reserved 27" 59 "Unused and Reserved 26" 58 "Unused and Reserved 25" 57 "Unused and Reserved 24" 56 "Unused and Reserved 23" 55 "Unused and Reserved 22" 54 "Unused and Reserved 21" 53 "Unused and Reserved 20" 52 "Unused and Reserved 19" 51 "Unused and Reserved 18" 50 "Unused and Reserved 17" 49 "Unused and Reserved 16" 48 "Unused and Reserved 15" 47 "Unused and Reserved 14" 46 "Unused and Reserved 13" 45 "Unused and Reserved 12" 44 "Unused and Reserved 11" 43 "Unused and Reserved 10" 42 "Unused and Reserved 9" 41 "Unused and Reserved 8" 40 "Unused and Reserved 7" 39 "Unused and Reserved 6" 38 "Unused and Reserved 5" 37 "Unused and Reserved 4" 36 "Unused and Reserved 3" 35 "Unused and Reserved 2" 34 "Unused and Reserved 1" 33 "4000" 32 "3900" 31 "3800" 30 "3700" 29 "3600" 28 "3500" 27 "3400" 26 "3300" 25 "3200" 24 "3100" 23 "3000" 22 "2900" 21 "2800" 20 "2700" 19 "2600" 18 "2500" 17 "2400" 16 "2300" 15 "2200" 14 "2100" 13 "2000" 12 "1900" 11 "1800" 10 "1700" 9 "1600" 8 "1500" 7 "1400" 6 "1300" 5 "1200" 4 "1100" 3 "1000" 2 "900" 1 "800" ;
VAL_ 2151931904 RegVltCtlEngyRcvryAct 1 "true" 0 "false" ;
VAL_ 2151931904 VehSpdCntlSystmType 2 "Adaptive Cruise Control" 1 "Conventional Cruise Control" 0 "No Vehicle Speed Control" ;
VAL_ 2151931904 ACCSysSltdMdDispIO 1 "true" 0 "false" ;
VAL_ 2151931904 ACCSysSltdMd 3 "Unused And Reserved" 2 "Enhanced Cruise Control" 1 "Adaptive Cruise Control" 0 "Cruise Control Mode Switching Not Supported" ;
VAL_ 2151931904 PTExPrtclFltWrng3IO 1 "true" 0 "false" ;
VAL_ 2151931904 PTExPartFltManRegStat 7 "Unused and Reserved 2" 6 "Unused and Reserved 1" 5 "Pending Driver Input" 4 "Complete" 3 "In Progress" 2 "Not Allowed" 1 "Allowed" 0 "Cleaning Not Required" ;
VAL_ 2151931904 AWDRecmndIO 1 "true" 0 "false" ;
VAL_ 2151915520 ESPTrnVehOffFrPrkIO 1 "true" 0 "false" ;
VAL_ 2151915520 ESPTrnsCtlrMalfIO 1 "true" 0 "false" ;
VAL_ 2151915520 ESPShfToDrvTryAgnIO 1 "true" 0 "false" ;
VAL_ 2151915520 ElcShfPriTwoGrsSlInRq 3 "Drive Indication" 2 "Neutral Indication" 1 "Park Indication" 0 "No Indication" ;
VAL_ 2151915520 EngIntkArBstPrExtRngV 1 "Invalid" 0 "Valid" ;
VAL_ 2151915520 ElecShfRngDisp 15 "Unused and Reserved 3" 14 "Unused and Reserved 2" 13 "Unused and Reserved 1" 12 "Park Requested And Denied" 11 "Drive Requested And In Progress" 10 "Neutral Requested And In Progress" 9 "Reverse Requested And In Progress" 8 "Park Requested And In Progress" 7 "Reserved" 6 "Manual Nominal" 5 "Low Nominal" 4 "Drive Nominal" 3 "Neutral Nominal" 2 "Reverse Nominal" 1 "Park Nominal" 0 "No Display " ;
VAL_ 2151915520 ESPTransMalfIO 1 "true" 0 "false" ;
VAL_ 2151915520 ESPRngInvldReqIO 1 "true" 0 "false" ;
VAL_ 2151915520 ESPPrkInvldReqIO 1 "true" 0 "false" ;
VAL_ 2151915520 ESPHldShfLvrToEngRgIO 1 "true" 0 "false" ;
VAL_ 2151915520 ESPDrvrPrkIlkSftAtdIO 1 "true" 0 "false" ;
VAL_ 2151915520 ESPDrvrIlkShfAtdIO 1 "true" 0 "false" ;
VAL_ 2151915520 AHAct 1 "true" 0 "false" ;
VAL_ 2151915520 AHEnbld 1 "true" 0 "false" ;
VAL_ 2151915520 ShfToPrkBfExtngIO 1 "true" 0 "false" ;
VAL_ 2151915520 AHServcIO 1 "true" 0 "false" ;
VAL_ 2151915520 AHAppBrkPedlIO 1 "true" 0 "false" ;
VAL_ 2151915520 AHDisbldStbltIO 1 "true" 0 "false" ;
VAL_ 2151915520 AHDisbldDrOpnIO 1 "true" 0 "false" ;
VAL_ 2151915520 ElcTransRngSlctVDA 1 "Virtual Device Available" 0 "Virtual Device Unavailable" ;
VAL_ 2153947136 RmtRflshMdAct 1 "true" 0 "false" ;
VAL_ 2152112128 PMVSS_Disps 7 "Visualization Type 7" 6 "Visualization Type 6" 5 "Visualization Type 5" 4 "Visualization Type 4" 3 "Visualization Type 3" 2 "Visualization Type 2" 1 "Visualization Type 1" 0 "No Action" ;
VAL_ 2152112128 PMVSS_Exhst 7 "Visualization Type 7" 6 "Visualization Type 6" 5 "Visualization Type 5" 4 "Visualization Type 4" 3 "Visualization Type 3" 2 "Visualization Type 2" 1 "Visualization Type 1" 0 "No Action" ;
VAL_ 2152112128 PMVSS_PsngrSeat 7 "Visualization Type 7" 6 "Visualization Type 6" 5 "Visualization Type 5" 4 "Visualization Type 4" 3 "Visualization Type 3" 2 "Visualization Type 2" 1 "Visualization Type 1" 0 "No Action" ;
VAL_ 2152112128 PMVSS_DrvrSeat 7 "Visualization Type 7" 6 "Visualization Type 6" 5 "Visualization Type 5" 4 "Visualization Type 4" 3 "Visualization Type 3" 2 "Visualization Type 2" 1 "Visualization Type 1" 0 "No Action" ;
VAL_ 2152112128 PMVSS_AdptCrsCnt 7 "Visualization Type 7" 6 "Visualization Type 6" 5 "Visualization Type 5" 4 "Visualization Type 4" 3 "Visualization Type 3" 2 "Visualization Type 2" 1 "Visualization Type 1" 0 "No Action" ;
VAL_ 2152112128 PMVSS_Drvln 7 "Visualization Type 7" 6 "Visualization Type 6" 5 "Visualization Type 5" 4 "Visualization Type 4" 3 "Visualization Type 3" 2 "Visualization Type 2" 1 "Visualization Type 1" 0 "No Action" ;
VAL_ 2152112128 PMVSS_Susp 7 "Visualization Type 7" 6 "Visualization Type 6" 5 "Visualization Type 5" 4 "Visualization Type 4" 3 "Visualization Type 3" 2 "Visualization Type 2" 1 "Visualization Type 1" 0 "No Action" ;
VAL_ 2152112128 PMVSS_Strng 7 "Visualization Type 7" 6 "Visualization Type 6" 5 "Visualization Type 5" 4 "Visualization Type 4" 3 "Visualization Type 3" 2 "Visualization Type 2" 1 "Visualization Type 1" 0 "No Action" ;
VAL_ 2152112128 PMVSS_Trans 7 "Visualization Type 7" 6 "Visualization Type 6" 5 "Visualization Type 5" 4 "Visualization Type 4" 3 "Visualization Type 3" 2 "Visualization Type 2" 1 "Visualization Type 1" 0 "No Action" ;
VAL_ 2152112128 PMVSS_Eng 7 "Visualization Type 7" 6 "Visualization Type 6" 5 "Visualization Type 5" 4 "Visualization Type 4" 3 "Visualization Type 3" 2 "Visualization Type 2" 1 "Visualization Type 1" 0 "No Action" ;
VAL_ 2152112128 PMVSS_Snd 7 "Visualization Type 7" 6 "Visualization Type 6" 5 "Visualization Type 5" 4 "Visualization Type 4" 3 "Visualization Type 3" 2 "Visualization Type 2" 1 "Visualization Type 1" 0 "No Action" ;
VAL_ 2152112128 PerfMdMainMenuType 7 "Reserved" 6 "Reserved" 5 "Reserved" 4 "Reserved" 3 "Main Menu Type 3" 2 "Main Menu Type 2" 1 "Main Menu Type 1" 0 "No Action" ;
VAL_ 2153857024 TDRCADD_WOTEvnts 1 "true" 0 "false" ;
VAL_ 2153857024 TDRCADD_LDWEvnts 1 "true" 0 "false" ;
VAL_ 2153857024 TDRCADD_FCMBrEvts 1 "true" 0 "false" ;
VAL_ 2153857024 TDRCADD_DrwDrvAlrt 1 "true" 0 "false" ;
VAL_ 2153857024 TDRCADD_RCMBrEvts 1 "true" 0 "false" ;
VAL_ 2153857024 TDRCADD_FCImntAlrts 1 "true" 0 "false" ;
VAL_ 2153857024 TDRCADD_FCHdwyAlrt 1 "true" 0 "false" ;
VAL_ 2153857024 TDRCADD_StCtrlEvnts 1 "true" 0 "false" ;
VAL_ 2153857024 TDRCADD_ABSAtvEvt 1 "true" 0 "false" ;
VAL_ 2153857024 TDRCADD_TrCtrlEvnts 1 "true" 0 "false" ;
VAL_ 2153857024 TDRCADD_OvSpdEvnt 1 "true" 0 "false" ;
VAL_ 2153857024 TDRCADD_DistDrvn 1 "true" 0 "false" ;
VAL_ 2153857024 TDRCADD_MaxSpd 1 "true" 0 "false" ;
VAL_ 2153840640 TnDrvDRLOffUnbIO 1 "true" 0 "false" ;
VAL_ 2153840640 TnDrvALCOffUnbIO 1 "true" 0 "false" ;
VAL_ 2155913216 PFAS_SrvPedAlrtIO 1 "true" 0 "false" ;
VAL_ 2155913216 PFAS_PFASysStat 0 "Disable" 1 "Active" 2 "Fault" 3 "Unused and Reserved" ;
VAL_ 2155913216 PFAS_PFASndGenEn 1 "true" 0 "false" ;
VAL_ 2155913216 PFAS_PFARevSnd 0 "No Action" 1 "Sound #1" 2 "Sound #2" 3 "Sound #3" ;
VAL_ 2155913216 PFAS_PFAFwdSnd 0 "No Action" 1 "Sound #1" 2 "Sound #2" 3 "Sound #3" ;
VAL_ 2155913216 PedFrndlyAlrtCsSetAvl 1 "true" 0 "false" ;
VAL_ 2155913216 PedFrndlyAlrtCsCrStVal 0 "No Value" 1 "Off" 2 "On" ;
VAL_ 2155913216 DslExhFluidLvlPrcntV 1 "Invalid" 0 "Valid" ;
VAL_ 2155913216 DslEmnsOBDMrkt 0 "North America" 1 "Europe" ;
VAL_ 2155913216 DslExhFldRmngDstHRsV 1 "Invalid" 0 "Valid" ;
VAL_ 2152095744 SPMCA_SusPrfMd6Avl 1 "true" 0 "false" ;
VAL_ 2152095744 SPMCA_SusPrfMd5Avl 1 "true" 0 "false" ;
VAL_ 2152095744 SPMCA_SusPrfMd4Avl 1 "true" 0 "false" ;
VAL_ 2152095744 SPMCA_SusPrfMd3Avl 1 "true" 0 "false" ;
VAL_ 2152095744 SPMCA_SusPrfMd2Avl 1 "true" 0 "false" ;
VAL_ 2152095744 SPMCA_SusPrfMd1Avl 1 "true" 0 "false" ;
VAL_ 2152095744 SPMCA_StrPrfMd6Avl 1 "true" 0 "false" ;
VAL_ 2152095744 SPMCA_StrPrfMd5Avl 1 "true" 0 "false" ;
VAL_ 2152095744 SPMCA_StrPrfMd4Avl 1 "true" 0 "false" ;
VAL_ 2152095744 SPMCA_StrPrfMd3Avl 1 "true" 0 "false" ;
VAL_ 2152095744 SPMCA_StrPrfMd2Avl 1 "true" 0 "false" ;
VAL_ 2152095744 SPMCA_StrPrfMd1Avl 1 "true" 0 "false" ;
VAL_ 2152095744 SPMCA_SndPrfMd6Avl 1 "true" 0 "false" ;
VAL_ 2152095744 SPMCA_SndPrfMd5Avl 1 "true" 0 "false" ;
VAL_ 2152095744 SPMCA_SndPrfMd4Avl 1 "true" 0 "false" ;
VAL_ 2152095744 SPMCA_SndPrfMd3Avl 1 "true" 0 "false" ;
VAL_ 2152095744 SPMCA_SndPrfMd2Avl 1 "true" 0 "false" ;
VAL_ 2152095744 SPMCA_SndPrfMd1Avl 1 "true" 0 "false" ;
VAL_ 2152095744 DPMCA_DispPrfMd6Avl 1 "true" 0 "false" ;
VAL_ 2152095744 DPMCA_DispPrfMd5Avl 1 "true" 0 "false" ;
VAL_ 2152095744 DPMCA_DispPrfMd4Avl 1 "true" 0 "false" ;
VAL_ 2152095744 DPMCA_DispPrfMd3Avl 1 "true" 0 "false" ;
VAL_ 2152095744 DPMCA_DispPrfMd2Avl 1 "true" 0 "false" ;
VAL_ 2152095744 DPMCA_DispPrfMd1Avl 1 "true" 0 "false" ;
VAL_ 2152095744 DPMCA_DrvlPrfMd6Avl 1 "true" 0 "false" ;
VAL_ 2152095744 DPMCA_DrvlPrfMd5Avl 1 "true" 0 "false" ;
VAL_ 2152095744 DPMCA_DrvlPrfMd4Avl 1 "true" 0 "false" ;
VAL_ 2152095744 DPMCA_DrvlPrfMd3Avl 1 "true" 0 "false" ;
VAL_ 2152095744 DPMCA_DrvlPrfMd2Avl 1 "true" 0 "false" ;
VAL_ 2152095744 DPMCA_DrvlPrfMd1Avl 1 "true" 0 "false" ;
VAL_ 2151899136 PTOAccelUpnBrkRelIO 1 "true" 0 "false" ;
VAL_ 2151899136 PTOEngUpnBrkRelIO 1 "true" 0 "false" ;
VAL_ 2151899136 PTOManTransInGrIO 1 "true" 0 "false" ;
VAL_ 2151899136 PTOServIndOn 1 "true" 0 "false" ;
VAL_ 2151899136 PTOVDM 0 "Don't Use Data" 1 "Use Data" ;
VAL_ 2151899136 PTOVDA 1 "VirtualDeviceAvailable" 0 "VirtualDeviceUnavailable" ;
VAL_ 2151899136 PTOTransInGearIO 1 "true" 0 "false" ;
VAL_ 2151899136 PTOTpStpSpdCsStAvl 1 "true" 0 "false" ;
VAL_ 2151899136 PTOTpStSpdCsCrStVal 0 "No Action" 1 "5 rpm" 2 "10 rpm" 3 "25 rpm" 4 "50 rpm" 5 "100 rpm" 6 "250 rpm" 7 "500 rpm" ;
VAL_ 2151899136 PTOStdbySpdCsStAvl 1 "true" 0 "false" ;
VAL_ 2151899136 PTOStdbSpdCsCrStVal 0 "No Action" 1 "900 rpm" 2 "1000 rpm" 3 "1100 rpm" 4 "1200 rpm" 5 "1300 rpm" 6 "1400 rpm" 7 "1500 rpm" ;
VAL_ 2151899136 PTOSetPrkBrkIO 1 "true" 0 "false" ;
VAL_ 2151899136 PTOSet2SpdCsStAvl 1 "true" 0 "false" ;
VAL_ 2151899136 PTOSet2SpdCsCrStVal 0 "No Action" 1 "1900 rpm" 2 "2000 rpm" 3 "2100 rpm" 4 "2200 rpm" 5 "2300 rpm" 6 "2400 rpm" 7 "2500 rpm" 8 "2600 rpm" 9 "2700 rpm" 10 "2800 rpm" 11 "2900 rpm" 12 "3000 rpm" 13 "3100 rpm" 14 "3200 rpm" 15 "3300 rpm" ;
VAL_ 2151899136 PTOSet1SpdCsStAvl 1 "true" 0 "false" ;
VAL_ 2151899136 PTOSet1SpdCsCrStVal 0 "No Action" 1 "1100 rpm" 2 "1200 rpm" 3 "1300 rpm" 4 "1400 rpm" 5 "1500 rpm" 6 "1600 rpm" 7 "1700 rpm" 8 "1800 rpm" 9 "1900 rpm" 10 "2000 rpm" 11 "2100 rpm" 12 "2200 rpm" 13 "2300 rpm" 14 "2400 rpm" 15 "2500 rpm" ;
VAL_ 2151899136 PTORelCltPedIO 1 "true" 0 "false" ;
VAL_ 2151899136 PTORelBrkPedIO 1 "true" 0 "false" ;
VAL_ 2151899136 PTORelAccPedIO 1 "true" 0 "false" ;
VAL_ 2151899136 PTORedEngSpdIO 1 "true" 0 "false" ;
VAL_ 2151899136 PTOPrsRelCltPedIO 1 "true" 0 "false" ;
VAL_ 2151899136 PTOPrsRelBrkPedIO 1 "true" 0 "false" ;
VAL_ 2151899136 PTOEngRnTmrCsStAvl 1 "true" 0 "false" ;
VAL_ 2151899136 PTOEnRnTmCsCrStVal 0 "No Action" 1 "10 min" 2 "30 min" 3 "90 min" 4 "120 min" 5 "150 min" 6 "180 min" 7 "210 min" 8 "240 min" 9 "270 min" 10 "300 min" 11 "330 min" 12 "360 min" 13 "390 min" 14 "420 min" 15 "450 min" ;
VAL_ 2151899136 PTOEngmntStatInd 0 "No Indication" 1 "Continuous Indication" 2 "Slow Flashing Indication" 3 "Fast Flashing Indication" ;
VAL_ 2151899136 PTODisengCrsCntlIO 1 "true" 0 "false" ;
VAL_ 2150449152 ESPDrvrExtIO 1 "true" 0 "false" ;
VAL_ 2150449152 ESPDrvrDrStIndtrmntIO 1 "true" 0 "false" ;
VAL_ 2150449152 ESPAutoPrkIO 1 "true" 0 "false" ;
VAL_ 2150449152 ManTransIndReq 3 "Indication 3" 2 "Indication 2" 1 "Indication 1" 0 "No Indication" ;
VAL_ 2150449152 SrvcFlSysPrkInOpnArIO 1 "true" 0 "false" ;
VAL_ 2150449152 TnDrvStblCtrlOffUnbIO 1 "true" 0 "false" ;
VAL_ 2150449152 TnDrvTrCtrlOffUnbIO 1 "true" 0 "false" ;
VAL_ 2150449152 ASIRI_Indication08 1 "true" 0 "false" ;
VAL_ 2150449152 ASIRI_Indication07 1 "true" 0 "false" ;
VAL_ 2150449152 ASIRI_Indication06 1 "true" 0 "false" ;
VAL_ 2150449152 ASIRI_Indication05 1 "true" 0 "false" ;
VAL_ 2150449152 ASIRI_Indication04 1 "true" 0 "false" ;
VAL_ 2150449152 ASIRI_Indication03 1 "true" 0 "false" ;
VAL_ 2150449152 ASIRI_Indication02 1 "true" 0 "false" ;
VAL_ 2150449152 ASIRI_Indication01 1 "true" 0 "false" ;
VAL_ 2150449152 SpdLmtrSttngTypAct 3 "Reserved" 2 "Auto" 1 "Manual" 0 "Off" ;
VAL_ 2150449152 FuelSysNEmsRltMalfAct 1 "true" 0 "false" ;
VAL_ 2150449152 InActFuelMdFuelLvlIO 1 "true" 0 "false" ;
VAL_ 2150449152 EngInltSpcfcHmdtyV 1 "Invalid" 0 "Valid" ;
VAL_ 2150449152 EngInltSpcfcHmdtyM 0 "Don't Use Data" 1 "Use Data" ;
VAL_ 2149793792 VADIR_IndLvl 0 "No indication" 1 "Indication level 1" 2 "Indication Level 2" 3 "Indication Level 3" 4 "Indication Level 4" 5 "Indication Level 5" 6 "Indication Level 6" 7 "Indication Level 7" 8 "Indication Level 8" ;
VAL_ 2149793792 FCACustStngAvlbl 1 "true" 0 "false" ;
VAL_ 2149793792 FwdClnAlrtCustCrntSetngVal 0 "No Action" 1 "Off" 2 "On" ;
VAL_ 2152128512 PSPMCA_PsngStPrfMd6Avl 1 "true" 0 "false" ;
VAL_ 2152128512 PSPMCA_PsngStPrfMd5Avl 1 "true" 0 "false" ;
VAL_ 2152128512 PSPMCA_PsngStPrfMd4Avl 1 "true" 0 "false" ;
VAL_ 2152128512 PSPMCA_PsngStPrfMd3Avl 1 "true" 0 "false" ;
VAL_ 2152128512 PSPMCA_PsngStPrfMd2Avl 1 "true" 0 "false" ;
VAL_ 2152128512 PSPMCA_PsngStPrfMd1Avl 1 "true" 0 "false" ;
VAL_ 2152128512 DSPMCA_DrvrStPrfMd6Avl 1 "true" 0 "false" ;
VAL_ 2152128512 DSPMCA_DrvrStPrfMd5Avl 1 "true" 0 "false" ;
VAL_ 2152128512 DSPMCA_DrvrStPrfMd4Avl 1 "true" 0 "false" ;
VAL_ 2152128512 DSPMCA_DrvrStPrfMd3Avl 1 "true" 0 "false" ;
VAL_ 2152128512 DSPMCA_DrvrStPrfMd2Avl 1 "true" 0 "false" ;
VAL_ 2152128512 DSPMCA_DrvrStPrfMd1Avl 1 "true" 0 "false" ;
VAL_ 2152128512 DSPMCA_DrvStyPrfMd7Avl 1 "true" 0 "false" ;
VAL_ 2152128512 DSPMCA_DrvStyPrfMd6Avl 1 "true" 0 "false" ;
VAL_ 2152128512 DSPMCA_DrvStyPrfMd5Avl 1 "true" 0 "false" ;
VAL_ 2152128512 DSPMCA_DrvStyPrfMd4Avl 1 "true" 0 "false" ;
VAL_ 2152128512 DSPMCA_DrvStyPrfMd3Avl 1 "true" 0 "false" ;
VAL_ 2152128512 DSPMCA_DrvStyPrfMd2Avl 1 "true" 0 "false" ;
VAL_ 2152128512 DSPMCA_DrvStyPrfMd1Avl 1 "true" 0 "false" ;
VAL_ 2152128512 ACCPMCA_ACCPrfMd6Avl 1 "true" 0 "false" ;
VAL_ 2152128512 ACCPMCA_ACCPrfMd5Avl 1 "true" 0 "false" ;
VAL_ 2152128512 ACCPMCA_ACCPrfMd4Avl 1 "true" 0 "false" ;
VAL_ 2152128512 ACCPMCA_ACCPrfMd3Avl 1 "true" 0 "false" ;
VAL_ 2152128512 ACCPMCA_ACCPrfMd2Avl 1 "true" 0 "false" ;
VAL_ 2152128512 ACCPMCA_ACCPrfMd1Avl 1 "true" 0 "false" ;
VAL_ 2149924864 PTOMobModTrnsInGrIO 1 "true" 0 "false" ;
VAL_ 2149924864 FwdClnMtgnBrkReqAct 1 "true" 0 "false" ;
VAL_ 2149924864 TireRRLowTracIO 1 "true" 0 "false" ;
VAL_ 2149924864 TireRFLowTracIO 1 "true" 0 "false" ;
VAL_ 2149924864 TireLRLowTracIO 1 "true" 0 "false" ;
VAL_ 2149924864 TireLFLowTracIO 1 "true" 0 "false" ;
VAL_ 2149924864 HilRlbkCtrlActIO 1 "true" 0 "false" ;
VAL_ 2149924864 FstIdlMdAct 1 "true" 0 "false" ;
VAL_ 2149924864 DsplyPerfMdRq 7 "Performance Mode 7" 6 "Performance Mode 6" 5 "Performance Mode 5" 4 "Performance Mode 4" 3 "Performance Mode 3" 2 "Performance Mode 2" 1 "Performance Mode 1" 0 "No Action" ;
VAL_ 2149924864 DrvSelMd8Stat 1 "Active" 0 "Inactive" ;
VAL_ 2149924864 DrvSelMd8ReqDnd 1 "true" 0 "false" ;
VAL_ 2149924864 DrvSelMd7Stat 1 "Active" 0 "Inactive" ;
VAL_ 2149924864 DrvSelMd7ReqDnd 1 "true" 0 "false" ;
VAL_ 2149924864 DrvSelMd6Stat 1 "Active" 0 "Inactive" ;
VAL_ 2149924864 DrvSelMd6ReqDnd 1 "true" 0 "false" ;
VAL_ 2149924864 DrvSelMd5Stat 1 "Active" 0 "Inactive" ;
VAL_ 2149924864 DrvSelMd5ReqDnd 1 "true" 0 "false" ;
VAL_ 2149924864 DrvSelMd4Stat 1 "Active" 0 "Inactive" ;
VAL_ 2149924864 DrvSelMd4ReqDnd 1 "true" 0 "false" ;
VAL_ 2149924864 EDADS_RcmndtFwdGr 15 "Unused and Reserved 7" 14 "Unused and Reserved 6" 13 "Unused and Reserved 5" 12 "Unused and Reserved 4" 11 "Unused and Reserved 3" 10 "Tenth Gear" 9 "Ninth Gear" 8 "Eighth Gear" 7 "Seventh Gear" 6 "Sixth Gear" 5 "Fifth Gear" 4 "Fourth Gear" 3 "Third Gear" 2 "Second Gear" 1 "First Gear" 0 "None" ;
VAL_ 2149924864 EDADS_CrntFwdMsdG 15 "Unused and Reserved 7" 14 "Unused and Reserved 6" 13 "Unused and Reserved 5" 12 "Unused and Reserved 4" 11 "Unused and Reserved 3" 10 "Tenth Gear" 9 "Ninth Gear" 8 "Eighth Gear" 7 "Seventh Gear" 6 "Sixth Gear" 5 "Fifth Gear" 4 "Fourth Gear" 3 "Third Gear" 2 "Second Gear" 1 "First Gear" 0 "None" ;
VAL_ 2149924864 EDADS_ShftIndStat 2 "No Shift" 1 "Shift Up" 0 "Shift Down" ;
VAL_ 2149924864 EDADS_EcoDrvShftIO 1 "true" 0 "false" ;
VAL_ 2149924864 DSMSS_DrvSelMd0Pn 1 "true" 0 "false" ;
VAL_ 2149924864 DSMSS_DrvSelMd8Pn 1 "true" 0 "false" ;
VAL_ 2149924864 DSMSS_DrvSelMd7Pn 1 "true" 0 "false" ;
VAL_ 2149924864 DSMSS_DrvSelMd6Pn 1 "true" 0 "false" ;
VAL_ 2149924864 DSMSS_DrvSelMd5Pn 1 "true" 0 "false" ;
VAL_ 2149924864 DSMSS_DrvSelMd4Pn 1 "true" 0 "false" ;
VAL_ 2149924864 DSMSS_DrvSelMd3Pn 1 "true" 0 "false" ;
VAL_ 2149924864 DSMSS_DrvSelMd2Pn 1 "true" 0 "false" ;
VAL_ 2149924864 DSMSS_DrvSelMd1Pn 1 "true" 0 "false" ;
VAL_ 2149924864 DSMSS_DrvSelMd8Un 1 "true" 0 "false" ;
VAL_ 2149924864 DSMSS_DrvSelMd7Un 1 "true" 0 "false" ;
VAL_ 2149924864 DSMSS_DrvSelMd6Un 1 "true" 0 "false" ;
VAL_ 2149924864 DSMSS_DrvSelMd5Un 1 "true" 0 "false" ;
VAL_ 2149924864 DSMSS_DrvSelMd4Un 1 "true" 0 "false" ;
VAL_ 2149924864 DSMSS_DrvSelMd3Un 1 "true" 0 "false" ;
VAL_ 2149924864 DSMSS_DrvSelMd2Un 1 "true" 0 "false" ;
VAL_ 2149924864 DSMSS_DrvSelMd1Un 1 "true" 0 "false" ;
VAL_ 2149924864 DrvSelMd3Stat 1 "Active" 0 "Inactive" ;
VAL_ 2149924864 DrvSelMd3ReqDnd 1 "true" 0 "false" ;
VAL_ 2149924864 DrvSelMd2Stat 1 "Active" 0 "Inactive" ;
VAL_ 2149924864 DrvSelMd2ReqDnd 1 "true" 0 "false" ;
VAL_ 2149924864 DrvSelMd1Stat 1 "Active" 0 "Inactive" ;
VAL_ 2149924864 DrvSelMd1ReqDnd 1 "true" 0 "false" ;
VAL_ 2149924864 CPSCA_Resrv3Avail 1 "true" 0 "false" ;
VAL_ 2149924864 CPSCA_Resrv2Avail 1 "true" 0 "false" ;
VAL_ 2149924864 CPSCA_Resrv1Avail 1 "true" 0 "false" ;
VAL_ 2149924864 CPSCA_AlrtBrkStrAvail 1 "true" 0 "false" ;
VAL_ 2149924864 CPSCA_AlrtBrkAvail 1 "true" 0 "false" ;
VAL_ 2149924864 CPSCA_AlrtAvail 1 "true" 0 "false" ;
VAL_ 2149924864 CPSCA_OffAvail 1 "true" 0 "false" ;
VAL_ 2149924864 a_12VBatSysUnstab 1 "true" 0 "false" ;
VAL_ 2150301696 WlcAnmReq 1 "true" 0 "false" ;
SIG_GROUP_ 2151874560 EhnSrvEngImmbCom 1 : ESEIC_EngImRqPsw ESEIC_EngImmbRq;
SIG_GROUP_ 2154602496 EstHtrCorClntTemp 1 : EHCCT_EHtrCrOutClntTmp EHCCT_EHtrCrInClntTmp EHCCT_EHtrCrOutClntTmpV EHCCT_EHtrCrInClntTmpV;
SIG_GROUP_ 2152112128 PerfMdVislztnScrnStat 1 : PMVSS_Disps PMVSS_Exhst PMVSS_PsngrSeat PMVSS_DrvrSeat PMVSS_AdptCrsCnt PMVSS_Drvln PMVSS_Susp PMVSS_Strng PMVSS_Trans PMVSS_Eng PMVSS_Snd;
SIG_GROUP_ 2153857024 TnDrvRptCrdAvlDspDat 1 : TDRCADD_OvSpdEvnt TDRCADD_DistDrvn TDRCADD_MaxSpd TDRCADD_WOTEvnts TDRCADD_LDWEvnts TDRCADD_FCMBrEvts TDRCADD_DrwDrvAlrt TDRCADD_RCMBrEvts TDRCADD_FCImntAlrts TDRCADD_FCHdwyAlrt TDRCADD_StCtrlEvnts TDRCADD_ABSAtvEvt TDRCADD_TrCtrlEvnts;
SIG_GROUP_ 2155913216 PedFrndlyAlrtStat 1 : PFAS_SrvPedAlrtIO PFAS_PFASysStat PFAS_PFASndVolCtrl PFAS_PFASndGenEn PFAS_PFARevSnd PFAS_PFAFwdSnd PFAS_PFACrsOvrSpd;
SIG_GROUP_ 2152095744 SusPerfMdCustAvl 1 : SPMCA_SusPrfMd6Avl SPMCA_SusPrfMd5Avl SPMCA_SusPrfMd4Avl SPMCA_SusPrfMd3Avl SPMCA_SusPrfMd2Avl SPMCA_SusPrfMd1Avl;
SIG_GROUP_ 2152095744 StrPerfMdCustAvl 1 : SPMCA_StrPrfMd6Avl SPMCA_StrPrfMd5Avl SPMCA_StrPrfMd4Avl SPMCA_StrPrfMd3Avl SPMCA_StrPrfMd2Avl SPMCA_StrPrfMd1Avl;
SIG_GROUP_ 2152095744 SndPerfMdCustAvl 1 : SPMCA_SndPrfMd6Avl SPMCA_SndPrfMd5Avl SPMCA_SndPrfMd4Avl SPMCA_SndPrfMd3Avl SPMCA_SndPrfMd2Avl SPMCA_SndPrfMd1Avl;
SIG_GROUP_ 2152095744 DispPerfCustMdAvl 1 : DPMCA_DispPrfMd6Avl DPMCA_DispPrfMd5Avl DPMCA_DispPrfMd4Avl DPMCA_DispPrfMd3Avl DPMCA_DispPrfMd2Avl DPMCA_DispPrfMd1Avl;
SIG_GROUP_ 2152095744 DrvlnPerfMdCustAvl 1 : DPMCA_DrvlPrfMd6Avl DPMCA_DrvlPrfMd5Avl DPMCA_DrvlPrfMd4Avl DPMCA_DrvlPrfMd3Avl DPMCA_DrvlPrfMd2Avl DPMCA_DrvlPrfMd1Avl;
SIG_GROUP_ 2150449152 AutoStpInhbtRsnInd 1 : ASIRI_Indication08 ASIRI_Indication07 ASIRI_Indication06 ASIRI_Indication05 ASIRI_Indication04 ASIRI_Indication03 ASIRI_Indication02 ASIRI_Indication01;
SIG_GROUP_ 2149793792 VhlAhdDstIndReq 1 : VADIR_IndLvl VADIR_FlwTme VADIR_FlwDst;
SIG_GROUP_ 2152128512 PsngStPerfMdCustAvl 1 : PSPMCA_PsngStPrfMd6Avl PSPMCA_PsngStPrfMd5Avl PSPMCA_PsngStPrfMd4Avl PSPMCA_PsngStPrfMd3Avl PSPMCA_PsngStPrfMd2Avl PSPMCA_PsngStPrfMd1Avl;
SIG_GROUP_ 2152128512 DrvrStPerfMdCustAvl 1 : DSPMCA_DrvrStPrfMd6Avl DSPMCA_DrvrStPrfMd5Avl DSPMCA_DrvrStPrfMd4Avl DSPMCA_DrvrStPrfMd3Avl DSPMCA_DrvrStPrfMd2Avl DSPMCA_DrvrStPrfMd1Avl;
SIG_GROUP_ 2152128512 DrvStyPerfMdCustAvl 1 : DSPMCA_DrvStyPrfMd7Avl DSPMCA_DrvStyPrfMd6Avl DSPMCA_DrvStyPrfMd5Avl DSPMCA_DrvStyPrfMd4Avl DSPMCA_DrvStyPrfMd3Avl DSPMCA_DrvStyPrfMd2Avl DSPMCA_DrvStyPrfMd1Avl;
SIG_GROUP_ 2152128512 ACCPerfMdCustAvl 1 : ACCPMCA_ACCPrfMd6Avl ACCPMCA_ACCPrfMd5Avl ACCPMCA_ACCPrfMd4Avl ACCPMCA_ACCPrfMd3Avl ACCPMCA_ACCPrfMd2Avl ACCPMCA_ACCPrfMd1Avl;
SIG_GROUP_ 2149924864 ECODrvAsstDsplyStat 1 : EDADS_RcmndtFwdGr EDADS_CrntFwdMsdG EDADS_ShftIndStat EDADS_EcoDrvShftIO;
SIG_GROUP_ 2149924864 DrvSelMdSelnStat 1 : DSMSS_DrvSelMd0Pn DSMSS_DrvSelMd8Pn DSMSS_DrvSelMd7Pn DSMSS_DrvSelMd6Pn DSMSS_DrvSelMd5Pn DSMSS_DrvSelMd4Pn DSMSS_DrvSelMd3Pn DSMSS_DrvSelMd2Pn DSMSS_DrvSelMd1Pn DSMSS_DrvSelMd8Un DSMSS_DrvSelMd7Un DSMSS_DrvSelMd6Un DSMSS_DrvSelMd5Un DSMSS_DrvSelMd4Un DSMSS_DrvSelMd3Un DSMSS_DrvSelMd2Un DSMSS_DrvSelMd1Un;
SIG_GROUP_ 2149924864 ColPrepSysCustAvail 1 : CPSCA_Resrv3Avail CPSCA_Resrv2Avail CPSCA_Resrv1Avail CPSCA_AlrtBrkStrAvail CPSCA_AlrtBrkAvail CPSCA_AlrtAvail CPSCA_OffAvail;
